VERSION ""

NS_ :

BS_:

BU_:

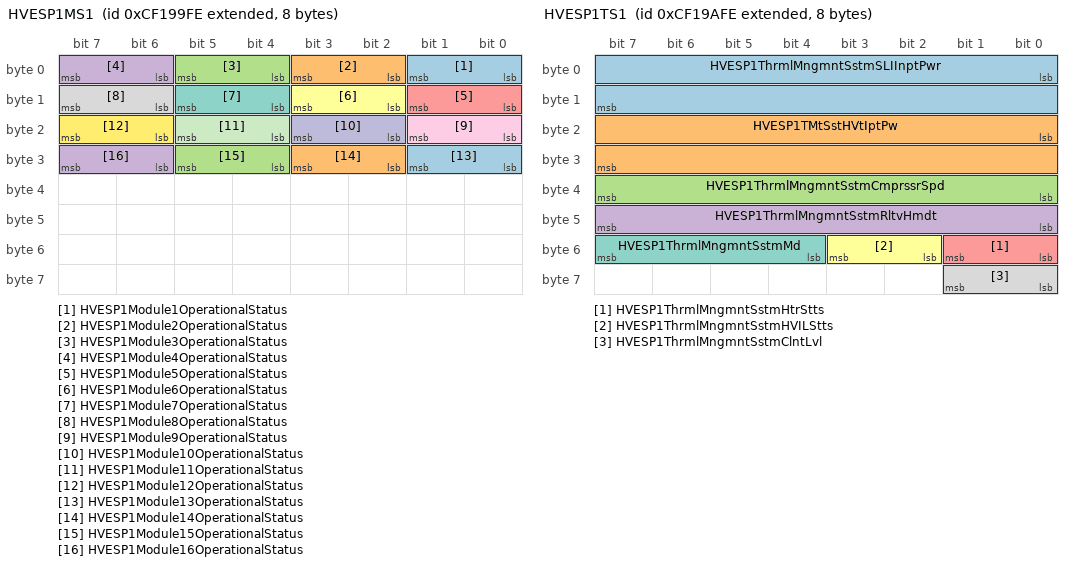
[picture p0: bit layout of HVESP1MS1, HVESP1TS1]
BO_ 2364643838 HVESP1MS1: 8 Vector__XXX
 SG_ HVESP1Module1OperationalStatus : 0|2@1+ (1,0) [0|3] "" Vector__XXX
 SG_ HVESP1Module2OperationalStatus : 2|2@1+ (1,0) [0|3] "" Vector__XXX
 SG_ HVESP1Module3OperationalStatus : 4|2@1+ (1,0) [0|3] "" Vector__XXX
 SG_ HVESP1Module4OperationalStatus : 6|2@1+ (1,0) [0|3] "" Vector__XXX
 SG_ HVESP1Module5OperationalStatus : 8|2@1+ (1,0) [0|3] "" Vector__XXX
 SG_ HVESP1Module6OperationalStatus : 10|2@1+ (1,0) [0|3] "" Vector__XXX
 SG_ HVESP1Module7OperationalStatus : 12|2@1+ (1,0) [0|3] "" Vector__XXX
 SG_ HVESP1Module8OperationalStatus : 14|2@1+ (1,0) [0|3] "" Vector__XXX
 SG_ HVESP1Module9OperationalStatus : 16|2@1+ (1,0) [0|3] "" Vector__XXX
 SG_ HVESP1Module10OperationalStatus : 18|2@1+ (1,0) [0|3] "" Vector__XXX
 SG_ HVESP1Module11OperationalStatus : 20|2@1+ (1,0) [0|3] "" Vector__XXX
 SG_ HVESP1Module12OperationalStatus : 22|2@1+ (1,0) [0|3] "" Vector__XXX
 SG_ HVESP1Module13OperationalStatus : 24|2@1+ (1,0) [0|3] "" Vector__XXX
 SG_ HVESP1Module14OperationalStatus : 26|2@1+ (1,0) [0|3] "" Vector__XXX
 SG_ HVESP1Module15OperationalStatus : 28|2@1+ (1,0) [0|3] "" Vector__XXX
 SG_ HVESP1Module16OperationalStatus : 30|2@1+ (1,0) [0|3] "" Vector__XXX

BO_ 2364644094 HVESP1TS1: 8 Vector__XXX
 SG_ HVESP1ThrmlMngmntSstmSLIInptPwr : 0|16@1+ (0.5,0) [0|32127.5] "W" Vector__XXX
 SG_ HVESP1TMtSstHVtIptPw : 16|16@1+ (0.5,0) [0|32127.5] "W" Vector__XXX
 SG_ HVESP1ThrmlMngmntSstmCmprssrSpd : 32|8@1+ (32,0) [0|8000] "rpm" Vector__XXX
 SG_ HVESP1ThrmlMngmntSstmRltvHmdt : 40|8@1+ (0.4,0) [0|100] "%" Vector__XXX
 SG_ HVESP1ThrmlMngmntSstmHtrStts : 48|2@1+ (1,0) [0|3] "" Vector__XXX
 SG_ HVESP1ThrmlMngmntSstmHVILStts : 50|2@1+ (1,0) [0|3] "" Vector__XXX
 SG_ HVESP1ThrmlMngmntSstmMd : 52|4@1+ (1,0) [0|15] "" Vector__XXX
 SG_ HVESP1ThrmlMngmntSstmClntLvl : 56|2@1+ (1,0) [0|3] "" Vector__XXX

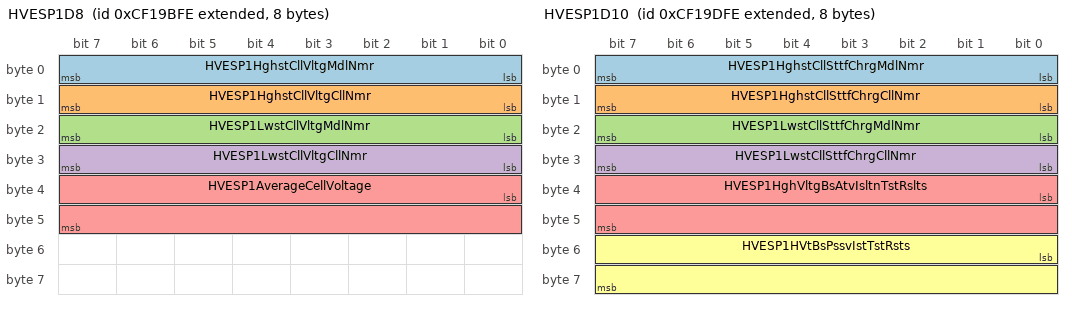
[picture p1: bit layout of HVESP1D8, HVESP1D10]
BO_ 2364644350 HVESP1D8: 8 Vector__XXX
 SG_ HVESP1HghstCllVltgMdlNmr : 0|8@1+ (1,0) [0|250] "count" Vector__XXX
 SG_ HVESP1HghstCllVltgCllNmr : 8|8@1+ (1,0) [0|250] "count" Vector__XXX
 SG_ HVESP1LwstCllVltgMdlNmr : 16|8@1+ (1,0) [0|250] "count" Vector__XXX
 SG_ HVESP1LwstCllVltgCllNmr : 24|8@1+ (1,0) [0|250] "count" Vector__XXX
 SG_ HVESP1AverageCellVoltage : 32|16@1+ (0.001,0) [0|64.255] "V" Vector__XXX

BO_ 2364644606 HVESP1D9: 8 Vector__XXX
 SG_ HVESP1HghstCllTmprtrMdlNmr : 0|8@1+ (1,0) [0|250] "count" Vector__XXX
 SG_ HVESP1HghstCllTmprtrCllNmr : 8|8@1+ (1,0) [0|250] "count" Vector__XXX
 SG_ HVESP1LwstCllTmprtrMdlNmr : 16|8@1+ (1,0) [0|250] "count" Vector__XXX
 SG_ HVESP1LwstCllTmprtrCllNmr : 24|8@1+ (1,0) [0|250] "count" Vector__XXX

BO_ 2364644862 HVESP1D10: 8 Vector__XXX
 SG_ HVESP1HghstCllSttfChrgMdlNmr : 0|8@1+ (1,0) [0|250] "count" Vector__XXX
 SG_ HVESP1HghstCllSttfChrgCllNmr : 8|8@1+ (1,0) [0|250] "count" Vector__XXX
 SG_ HVESP1LwstCllSttfChrgMdlNmr : 16|8@1+ (1,0) [0|250] "count" Vector__XXX
 SG_ HVESP1LwstCllSttfChrgCllNmr : 24|8@1+ (1,0) [0|250] "count" Vector__XXX
 SG_ HVESP1HghVltgBsAtvIsltnTstRslts : 32|16@1+ (0.1,0) [0|6425.5] "ohm/V" Vector__XXX
 SG_ HVESP1HVtBsPssvIstTstRsts : 48|16@1+ (0.1,0) [0|6425.5] "ohm/V" Vector__XXX

BO_ 2364645118 HVESP1D11: 8 Vector__XXX
 SG_ HVESP1BsVltgNgtvtChsssGrndVltg : 0|16@1+ (0.05,0) [0|3212.75] "V" Vector__XXX
 SG_ HVESP1VltgLvlNgtvtChsssGrndVltg : 16|16@1+ (0.05,0) [0|3212.75] "V" Vector__XXX

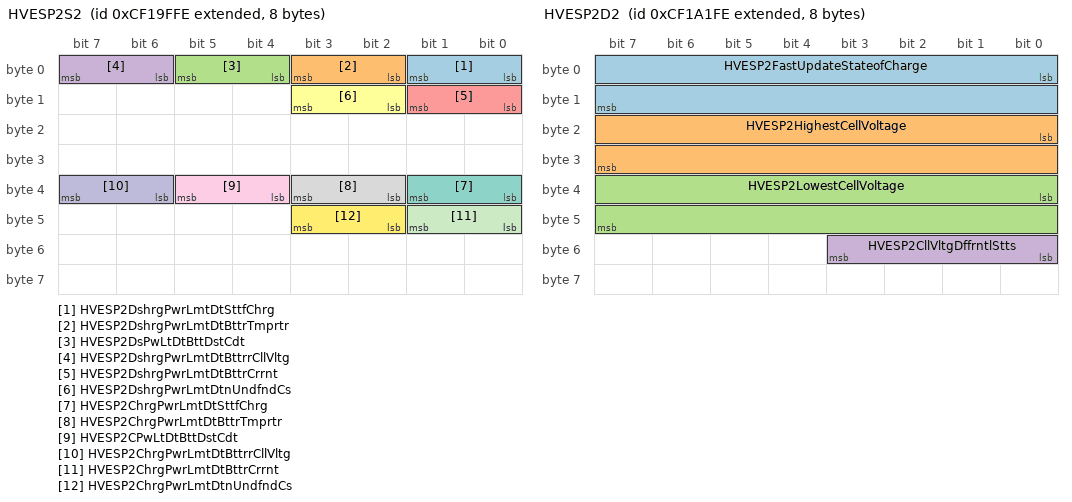
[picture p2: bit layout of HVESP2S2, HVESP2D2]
BO_ 2364645374 HVESP2S2: 8 Vector__XXX
 SG_ HVESP2DshrgPwrLmtDtSttfChrg : 0|2@1+ (1,0) [0|3] "" Vector__XXX
 SG_ HVESP2DshrgPwrLmtDtBttrTmprtr : 2|2@1+ (1,0) [0|3] "" Vector__XXX
 SG_ HVESP2DsPwLtDtBttDstCdt : 4|2@1+ (1,0) [0|3] "" Vector__XXX
 SG_ HVESP2DshrgPwrLmtDtBttrrCllVltg : 6|2@1+ (1,0) [0|3] "" Vector__XXX
 SG_ HVESP2DshrgPwrLmtDtBttrCrrnt : 8|2@1+ (1,0) [0|3] "" Vector__XXX
 SG_ HVESP2DshrgPwrLmtDtnUndfndCs : 10|2@1+ (1,0) [0|3] "" Vector__XXX
 SG_ HVESP2ChrgPwrLmtDtSttfChrg : 32|2@1+ (1,0) [0|3] "" Vector__XXX
 SG_ HVESP2ChrgPwrLmtDtBttrTmprtr : 34|2@1+ (1,0) [0|3] "" Vector__XXX
 SG_ HVESP2CPwLtDtBttDstCdt : 36|2@1+ (1,0) [0|3] "" Vector__XXX
 SG_ HVESP2ChrgPwrLmtDtBttrrCllVltg : 38|2@1+ (1,0) [0|3] "" Vector__XXX
 SG_ HVESP2ChrgPwrLmtDtBttrCrrnt : 40|2@1+ (1,0) [0|3] "" Vector__XXX
 SG_ HVESP2ChrgPwrLmtDtnUndfndCs : 42|2@1+ (1,0) [0|3] "" Vector__XXX

BO_ 2364645630 HVESP2D1: 8 Vector__XXX
 SG_ HVESP2AvailableDischargePower : 0|16@1+ (0.05,0) [0|3212.75] "kW" Vector__XXX
 SG_ HVESP2AvailableChargePower : 16|16@1+ (0.05,0) [0|3212.75] "kW" Vector__XXX
 SG_ HVESP2VoltageLevel : 32|16@1+ (0.05,0) [0|3212.75] "V" Vector__XXX
 SG_ HVESP2Current : 48|16@1+ (0.05,-1600) [-1600|1612.75] "A" Vector__XXX

BO_ 2364645886 HVESP2D2: 8 Vector__XXX
 SG_ HVESP2FastUpdateStateofCharge : 0|16@1+ (0.0015625,0) [0|100.3984375] "%" Vector__XXX
 SG_ HVESP2HighestCellVoltage : 16|16@1+ (0.001,0) [0|64.255] "V" Vector__XXX
 SG_ HVESP2LowestCellVoltage : 32|16@1+ (0.001,0) [0|64.255] "V" Vector__XXX
 SG_ HVESP2CllVltgDffrntlStts : 48|4@1+ (1,0) [0|15] "" Vector__XXX

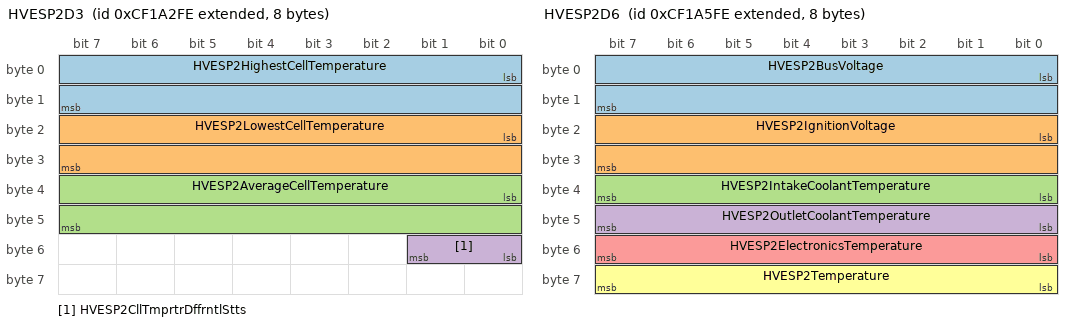
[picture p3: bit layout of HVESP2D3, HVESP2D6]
BO_ 2364646142 HVESP2D3: 8 Vector__XXX
 SG_ HVESP2HighestCellTemperature : 0|16@1+ (0.03125,-273) [-273|1734.96875] "degC" Vector__XXX
 SG_ HVESP2LowestCellTemperature : 16|16@1+ (0.03125,-273) [-273|1734.96875] "degC" Vector__XXX
 SG_ HVESP2AverageCellTemperature : 32|16@1+ (0.03125,-273) [-273|1734.96875] "degC" Vector__XXX
 SG_ HVESP2CllTmprtrDffrntlStts : 48|2@1+ (1,0) [0|3] "" Vector__XXX

BO_ 2364646398 HVESP2D4: 8 Vector__XXX
 SG_ HVESP2DischargeCapacity : 0|16@1+ (0.01,0) [0|642.55] "Ah" Vector__XXX
 SG_ HVESP2ChargeCapacity : 16|16@1+ (0.01,0) [0|642.55] "Ah" Vector__XXX
 SG_ HVESP2CellBalancingCount : 32|16@1+ (1,0) [0|64255] "count" Vector__XXX

BO_ 2364646654 HVESP2D5: 8 Vector__XXX
 SG_ HVESP2DischargeCurrentLimit : 0|16@1+ (0.05,-1600) [-1600|1612.75] "A" Vector__XXX
 SG_ HVESP2ChargeCurrentLimit : 16|16@1+ (0.05,-1600) [-1600|1612.75] "A" Vector__XXX
 SG_ HVESP2LowestCellStateofCharge : 32|16@1+ (0.0015625,0) [0|100.3984375] "%" Vector__XXX
 SG_ HVESP2HighestCellStateofCharge : 48|16@1+ (0.0015625,0) [0|100.3984375] "%" Vector__XXX

BO_ 2364646910 HVESP2D6: 8 Vector__XXX
 SG_ HVESP2BusVoltage : 0|16@1+ (0.05,0) [0|3212.75] "V" Vector__XXX
 SG_ HVESP2IgnitionVoltage : 16|16@1+ (0.01,0) [0|642.55] "V" Vector__XXX
 SG_ HVESP2IntakeCoolantTemperature : 32|8@1+ (1,-40) [-40|210] "degC" Vector__XXX
 SG_ HVESP2OutletCoolantTemperature : 40|8@1+ (1,-40) [-40|210] "degC" Vector__XXX
 SG_ HVESP2ElectronicsTemperature : 48|8@1+ (1,-40) [-40|210] "degC" Vector__XXX
 SG_ HVESP2Temperature : 56|8@1+ (1,-40) [-40|210] "degC" Vector__XXX

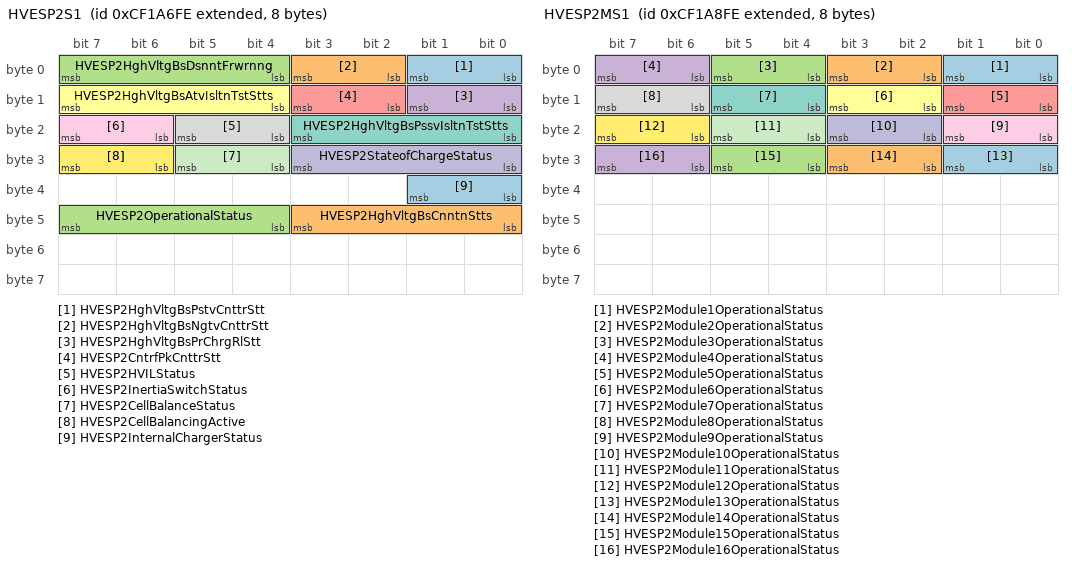
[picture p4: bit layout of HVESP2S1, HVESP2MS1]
BO_ 2364647166 HVESP2S1: 8 Vector__XXX
 SG_ HVESP2HghVltgBsPstvCnttrStt : 0|2@1+ (1,0) [0|3] "" Vector__XXX
 SG_ HVESP2HghVltgBsNgtvCnttrStt : 2|2@1+ (1,0) [0|3] "" Vector__XXX
 SG_ HVESP2HghVltgBsDsnntFrwrnng : 4|4@1+ (1,0) [0|15] "" Vector__XXX
 SG_ HVESP2HghVltgBsPrChrgRlStt : 8|2@1+ (1,0) [0|3] "" Vector__XXX
 SG_ HVESP2CntrfPkCnttrStt : 10|2@1+ (1,0) [0|3] "" Vector__XXX
 SG_ HVESP2HghVltgBsAtvIsltnTstStts : 12|4@1+ (1,0) [0|15] "" Vector__XXX
 SG_ HVESP2HghVltgBsPssvIsltnTstStts : 16|4@1+ (1,0) [0|15] "" Vector__XXX
 SG_ HVESP2HVILStatus : 20|2@1+ (1,0) [0|3] "" Vector__XXX
 SG_ HVESP2InertiaSwitchStatus : 22|2@1+ (1,0) [0|3] "" Vector__XXX
 SG_ HVESP2StateofChargeStatus : 24|4@1+ (1,0) [0|15] "" Vector__XXX
 SG_ HVESP2CellBalanceStatus : 28|2@1+ (1,0) [0|3] "" Vector__XXX
 SG_ HVESP2CellBalancingActive : 30|2@1+ (1,0) [0|3] "" Vector__XXX
 SG_ HVESP2InternalChargerStatus : 32|2@1+ (1,0) [0|3] "" Vector__XXX
 SG_ HVESP2HghVltgBsCnntnStts : 40|4@1+ (1,0) [0|15] "" Vector__XXX
 SG_ HVESP2OperationalStatus : 44|4@1+ (1,0) [0|15] "" Vector__XXX

BO_ 2364647422 HVESP2D7: 8 Vector__XXX
 SG_ HVESP2DischargeEnergyCapacity : 0|24@1+ (0.001,0) [0|16449.535] "kWh" Vector__XXX
 SG_ HVESP2ChargeEnergyCapacity : 24|24@1+ (0.001,0) [0|16449.535] "kWh" Vector__XXX
 SG_ HVESP2MaximumChargeVoltageLimit : 48|16@1+ (0.05,0) [0|3212.75] "V" Vector__XXX

BO_ 2364647678 HVESP2MS1: 8 Vector__XXX
 SG_ HVESP2Module1OperationalStatus : 0|2@1+ (1,0) [0|3] "" Vector__XXX
 SG_ HVESP2Module2OperationalStatus : 2|2@1+ (1,0) [0|3] "" Vector__XXX
 SG_ HVESP2Module3OperationalStatus : 4|2@1+ (1,0) [0|3] "" Vector__XXX
 SG_ HVESP2Module4OperationalStatus : 6|2@1+ (1,0) [0|3] "" Vector__XXX
 SG_ HVESP2Module5OperationalStatus : 8|2@1+ (1,0) [0|3] "" Vector__XXX
 SG_ HVESP2Module6OperationalStatus : 10|2@1+ (1,0) [0|3] "" Vector__XXX
 SG_ HVESP2Module7OperationalStatus : 12|2@1+ (1,0) [0|3] "" Vector__XXX
 SG_ HVESP2Module8OperationalStatus : 14|2@1+ (1,0) [0|3] "" Vector__XXX
 SG_ HVESP2Module9OperationalStatus : 16|2@1+ (1,0) [0|3] "" Vector__XXX
 SG_ HVESP2Module10OperationalStatus : 18|2@1+ (1,0) [0|3] "" Vector__XXX
 SG_ HVESP2Module11OperationalStatus : 20|2@1+ (1,0) [0|3] "" Vector__XXX
 SG_ HVESP2Module12OperationalStatus : 22|2@1+ (1,0) [0|3] "" Vector__XXX
 SG_ HVESP2Module13OperationalStatus : 24|2@1+ (1,0) [0|3] "" Vector__XXX
 SG_ HVESP2Module14OperationalStatus : 26|2@1+ (1,0) [0|3] "" Vector__XXX
 SG_ HVESP2Module15OperationalStatus : 28|2@1+ (1,0) [0|3] "" Vector__XXX
 SG_ HVESP2Module16OperationalStatus : 30|2@1+ (1,0) [0|3] "" Vector__XXX

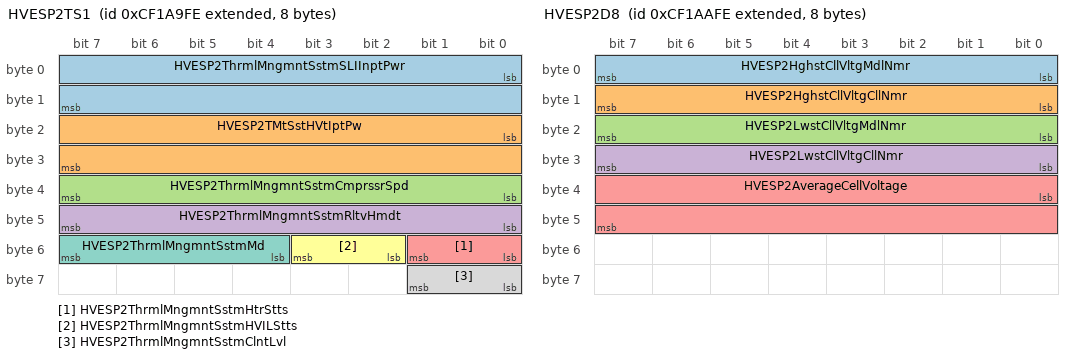
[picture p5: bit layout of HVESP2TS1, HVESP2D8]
BO_ 2364647934 HVESP2TS1: 8 Vector__XXX
 SG_ HVESP2ThrmlMngmntSstmSLIInptPwr : 0|16@1+ (0.5,0) [0|32127.5] "W" Vector__XXX
 SG_ HVESP2TMtSstHVtIptPw : 16|16@1+ (0.5,0) [0|32127.5] "W" Vector__XXX
 SG_ HVESP2ThrmlMngmntSstmCmprssrSpd : 32|8@1+ (32,0) [0|8000] "rpm" Vector__XXX
 SG_ HVESP2ThrmlMngmntSstmRltvHmdt : 40|8@1+ (0.4,0) [0|100] "%" Vector__XXX
 SG_ HVESP2ThrmlMngmntSstmHtrStts : 48|2@1+ (1,0) [0|3] "" Vector__XXX
 SG_ HVESP2ThrmlMngmntSstmHVILStts : 50|2@1+ (1,0) [0|3] "" Vector__XXX
 SG_ HVESP2ThrmlMngmntSstmMd : 52|4@1+ (1,0) [0|15] "" Vector__XXX
 SG_ HVESP2ThrmlMngmntSstmClntLvl : 56|2@1+ (1,0) [0|3] "" Vector__XXX

BO_ 2364648190 HVESP2D8: 8 Vector__XXX
 SG_ HVESP2HghstCllVltgMdlNmr : 0|8@1+ (1,0) [0|250] "count" Vector__XXX
 SG_ HVESP2HghstCllVltgCllNmr : 8|8@1+ (1,0) [0|250] "count" Vector__XXX
 SG_ HVESP2LwstCllVltgMdlNmr : 16|8@1+ (1,0) [0|250] "count" Vector__XXX
 SG_ HVESP2LwstCllVltgCllNmr : 24|8@1+ (1,0) [0|250] "count" Vector__XXX
 SG_ HVESP2AverageCellVoltage : 32|16@1+ (0.001,0) [0|64.255] "V" Vector__XXX

BO_ 2364648446 HVESP2D9: 8 Vector__XXX
 SG_ HVESP2HghstCllTmprtrMdlNmr : 0|8@1+ (1,0) [0|250] "count" Vector__XXX
 SG_ HVESP2HghstCllTmprtrCllNmr : 8|8@1+ (1,0) [0|250] "count" Vector__XXX
 SG_ HVESP2LwstCllTmprtrMdlNmr : 16|8@1+ (1,0) [0|250] "count" Vector__XXX
 SG_ HVESP2LwstCllTmprtrCllNmr : 24|8@1+ (1,0) [0|250] "count" Vector__XXX

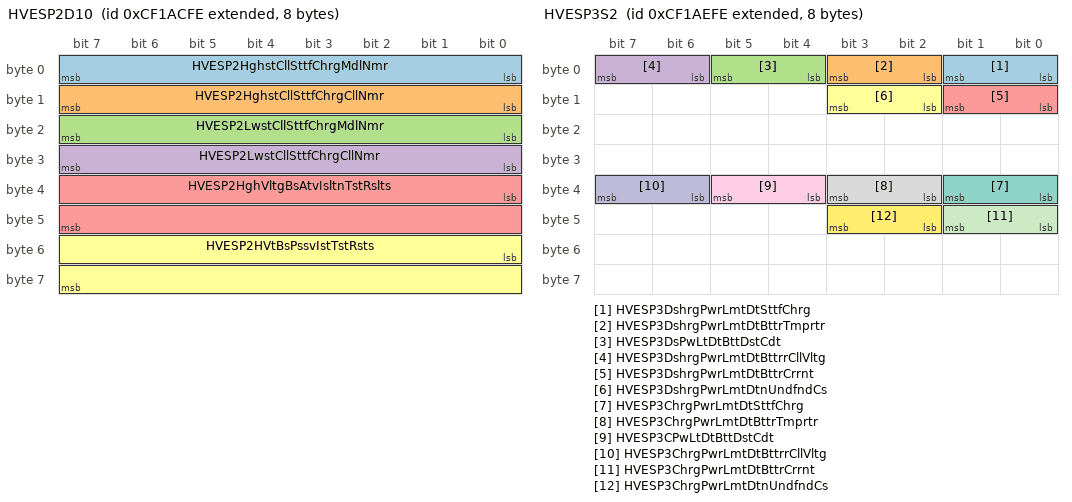
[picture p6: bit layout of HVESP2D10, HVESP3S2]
BO_ 2364648702 HVESP2D10: 8 Vector__XXX
 SG_ HVESP2HghstCllSttfChrgMdlNmr : 0|8@1+ (1,0) [0|250] "count" Vector__XXX
 SG_ HVESP2HghstCllSttfChrgCllNmr : 8|8@1+ (1,0) [0|250] "count" Vector__XXX
 SG_ HVESP2LwstCllSttfChrgMdlNmr : 16|8@1+ (1,0) [0|250] "count" Vector__XXX
 SG_ HVESP2LwstCllSttfChrgCllNmr : 24|8@1+ (1,0) [0|250] "count" Vector__XXX
 SG_ HVESP2HghVltgBsAtvIsltnTstRslts : 32|16@1+ (0.1,0) [0|6425.5] "ohm/V" Vector__XXX
 SG_ HVESP2HVtBsPssvIstTstRsts : 48|16@1+ (0.1,0) [0|6425.5] "ohm/V" Vector__XXX

BO_ 2364648958 HVESP2D11: 8 Vector__XXX
 SG_ HVESP2BsVltgNgtvtChsssGrndVltg : 0|16@1+ (0.05,0) [0|3212.75] "V" Vector__XXX
 SG_ HVESP2VltgLvlNgtvtChsssGrndVltg : 16|16@1+ (0.05,0) [0|3212.75] "V" Vector__XXX

BO_ 2364649214 HVESP3S2: 8 Vector__XXX
 SG_ HVESP3DshrgPwrLmtDtSttfChrg : 0|2@1+ (1,0) [0|3] "" Vector__XXX
 SG_ HVESP3DshrgPwrLmtDtBttrTmprtr : 2|2@1+ (1,0) [0|3] "" Vector__XXX
 SG_ HVESP3DsPwLtDtBttDstCdt : 4|2@1+ (1,0) [0|3] "" Vector__XXX
 SG_ HVESP3DshrgPwrLmtDtBttrrCllVltg : 6|2@1+ (1,0) [0|3] "" Vector__XXX
 SG_ HVESP3DshrgPwrLmtDtBttrCrrnt : 8|2@1+ (1,0) [0|3] "" Vector__XXX
 SG_ HVESP3DshrgPwrLmtDtnUndfndCs : 10|2@1+ (1,0) [0|3] "" Vector__XXX
 SG_ HVESP3ChrgPwrLmtDtSttfChrg : 32|2@1+ (1,0) [0|3] "" Vector__XXX
 SG_ HVESP3ChrgPwrLmtDtBttrTmprtr : 34|2@1+ (1,0) [0|3] "" Vector__XXX
 SG_ HVESP3CPwLtDtBttDstCdt : 36|2@1+ (1,0) [0|3] "" Vector__XXX
 SG_ HVESP3ChrgPwrLmtDtBttrrCllVltg : 38|2@1+ (1,0) [0|3] "" Vector__XXX
 SG_ HVESP3ChrgPwrLmtDtBttrCrrnt : 40|2@1+ (1,0) [0|3] "" Vector__XXX
 SG_ HVESP3ChrgPwrLmtDtnUndfndCs : 42|2@1+ (1,0) [0|3] "" Vector__XXX

BO_ 2364649470 HVESP3D1: 8 Vector__XXX
 SG_ HVESP3AvailableDischargePower : 0|16@1+ (0.05,0) [0|3212.75] "kW" Vector__XXX
 SG_ HVESP3AvailableChargePower : 16|16@1+ (0.05,0) [0|3212.75] "kW" Vector__XXX
 SG_ HVESP3VoltageLevel : 32|16@1+ (0.05,0) [0|3212.75] "V" Vector__XXX
 SG_ HVESP3Current : 48|16@1+ (0.05,-1600) [-1600|1612.75] "A" Vector__XXX

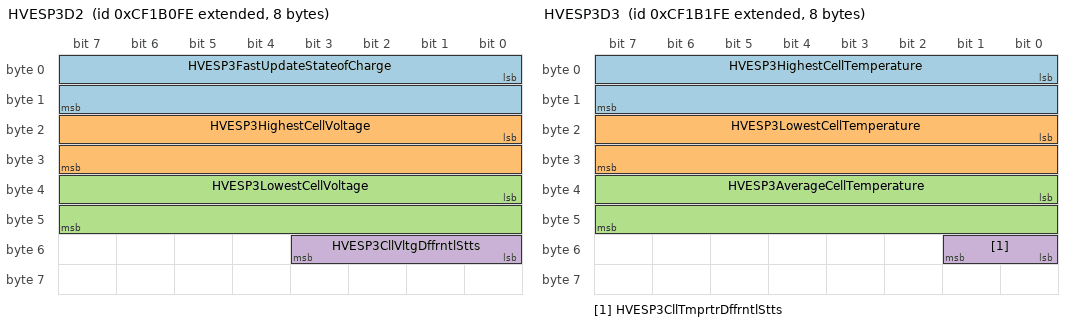
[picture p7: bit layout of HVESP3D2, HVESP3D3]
BO_ 2364649726 HVESP3D2: 8 Vector__XXX
 SG_ HVESP3FastUpdateStateofCharge : 0|16@1+ (0.0015625,0) [0|100.3984375] "%" Vector__XXX
 SG_ HVESP3HighestCellVoltage : 16|16@1+ (0.001,0) [0|64.255] "V" Vector__XXX
 SG_ HVESP3LowestCellVoltage : 32|16@1+ (0.001,0) [0|64.255] "V" Vector__XXX
 SG_ HVESP3CllVltgDffrntlStts : 48|4@1+ (1,0) [0|15] "" Vector__XXX

BO_ 2364649982 HVESP3D3: 8 Vector__XXX
 SG_ HVESP3HighestCellTemperature : 0|16@1+ (0.03125,-273) [-273|1734.96875] "degC" Vector__XXX
 SG_ HVESP3LowestCellTemperature : 16|16@1+ (0.03125,-273) [-273|1734.96875] "degC" Vector__XXX
 SG_ HVESP3AverageCellTemperature : 32|16@1+ (0.03125,-273) [-273|1734.96875] "degC" Vector__XXX
 SG_ HVESP3CllTmprtrDffrntlStts : 48|2@1+ (1,0) [0|3] "" Vector__XXX

BO_ 2364650238 HVESP3D4: 8 Vector__XXX
 SG_ HVESP3DischargeCapacity : 0|16@1+ (0.01,0) [0|642.55] "Ah" Vector__XXX
 SG_ HVESP3ChargeCapacity : 16|16@1+ (0.01,0) [0|642.55] "Ah" Vector__XXX
 SG_ HVESP3CellBalancingCount : 32|16@1+ (1,0) [0|64255] "count" Vector__XXX

BO_ 2364650494 HVESP3D5: 8 Vector__XXX
 SG_ HVESP3DischargeCurrentLimit : 0|16@1+ (0.05,-1600) [-1600|1612.75] "A" Vector__XXX
 SG_ HVESP3ChargeCurrentLimit : 16|16@1+ (0.05,-1600) [-1600|1612.75] "A" Vector__XXX
 SG_ HVESP3LowestCellStateofCharge : 32|16@1+ (0.0015625,0) [0|100.3984375] "%" Vector__XXX
 SG_ HVESP3HighestCellStateofCharge : 48|16@1+ (0.0015625,0) [0|100.3984375] "%" Vector__XXX

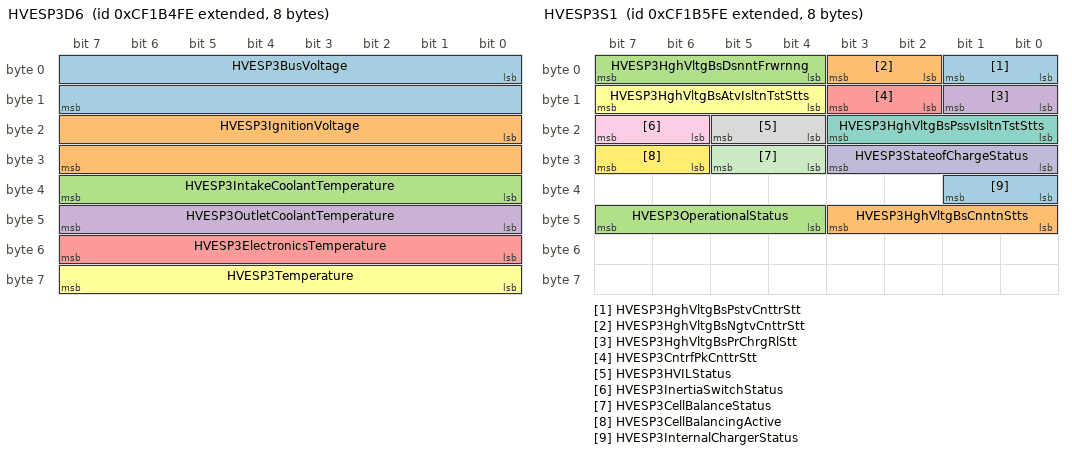
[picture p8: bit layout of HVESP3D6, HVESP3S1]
BO_ 2364650750 HVESP3D6: 8 Vector__XXX
 SG_ HVESP3BusVoltage : 0|16@1+ (0.05,0) [0|3212.75] "V" Vector__XXX
 SG_ HVESP3IgnitionVoltage : 16|16@1+ (0.01,0) [0|642.55] "V" Vector__XXX
 SG_ HVESP3IntakeCoolantTemperature : 32|8@1+ (1,-40) [-40|210] "degC" Vector__XXX
 SG_ HVESP3OutletCoolantTemperature : 40|8@1+ (1,-40) [-40|210] "degC" Vector__XXX
 SG_ HVESP3ElectronicsTemperature : 48|8@1+ (1,-40) [-40|210] "degC" Vector__XXX
 SG_ HVESP3Temperature : 56|8@1+ (1,-40) [-40|210] "degC" Vector__XXX

BO_ 2364651006 HVESP3S1: 8 Vector__XXX
 SG_ HVESP3HghVltgBsPstvCnttrStt : 0|2@1+ (1,0) [0|3] "" Vector__XXX
 SG_ HVESP3HghVltgBsNgtvCnttrStt : 2|2@1+ (1,0) [0|3] "" Vector__XXX
 SG_ HVESP3HghVltgBsDsnntFrwrnng : 4|4@1+ (1,0) [0|15] "" Vector__XXX
 SG_ HVESP3HghVltgBsPrChrgRlStt : 8|2@1+ (1,0) [0|3] "" Vector__XXX
 SG_ HVESP3CntrfPkCnttrStt : 10|2@1+ (1,0) [0|3] "" Vector__XXX
 SG_ HVESP3HghVltgBsAtvIsltnTstStts : 12|4@1+ (1,0) [0|15] "" Vector__XXX
 SG_ HVESP3HghVltgBsPssvIsltnTstStts : 16|4@1+ (1,0) [0|15] "" Vector__XXX
 SG_ HVESP3HVILStatus : 20|2@1+ (1,0) [0|3] "" Vector__XXX
 SG_ HVESP3InertiaSwitchStatus : 22|2@1+ (1,0) [0|3] "" Vector__XXX
 SG_ HVESP3StateofChargeStatus : 24|4@1+ (1,0) [0|15] "" Vector__XXX
 SG_ HVESP3CellBalanceStatus : 28|2@1+ (1,0) [0|3] "" Vector__XXX
 SG_ HVESP3CellBalancingActive : 30|2@1+ (1,0) [0|3] "" Vector__XXX
 SG_ HVESP3InternalChargerStatus : 32|2@1+ (1,0) [0|3] "" Vector__XXX
 SG_ HVESP3HghVltgBsCnntnStts : 40|4@1+ (1,0) [0|15] "" Vector__XXX
 SG_ HVESP3OperationalStatus : 44|4@1+ (1,0) [0|15] "" Vector__XXX

BO_ 2364651262 HVESP3D7: 8 Vector__XXX
 SG_ HVESP3DischargeEnergyCapacity : 0|24@1+ (0.001,0) [0|16449.535] "kWh" Vector__XXX
 SG_ HVESP3ChargeEnergyCapacity : 24|24@1+ (0.001,0) [0|16449.535] "kWh" Vector__XXX
 SG_ HVESP3MaximumChargeVoltageLimit : 48|16@1+ (0.05,0) [0|3212.75] "V" Vector__XXX

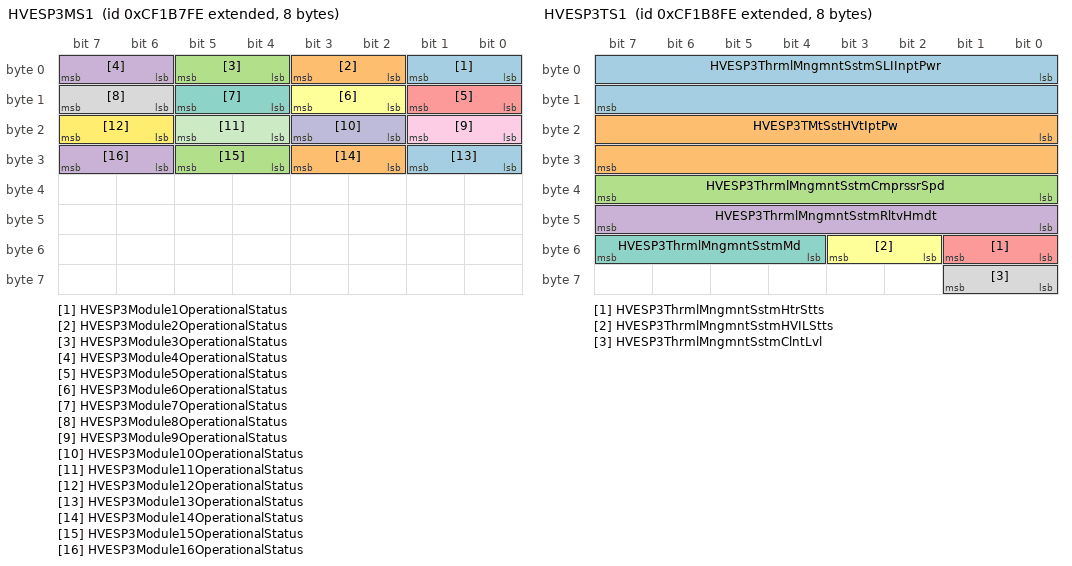
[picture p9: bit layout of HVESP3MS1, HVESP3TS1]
BO_ 2364651518 HVESP3MS1: 8 Vector__XXX
 SG_ HVESP3Module1OperationalStatus : 0|2@1+ (1,0) [0|3] "" Vector__XXX
 SG_ HVESP3Module2OperationalStatus : 2|2@1+ (1,0) [0|3] "" Vector__XXX
 SG_ HVESP3Module3OperationalStatus : 4|2@1+ (1,0) [0|3] "" Vector__XXX
 SG_ HVESP3Module4OperationalStatus : 6|2@1+ (1,0) [0|3] "" Vector__XXX
 SG_ HVESP3Module5OperationalStatus : 8|2@1+ (1,0) [0|3] "" Vector__XXX
 SG_ HVESP3Module6OperationalStatus : 10|2@1+ (1,0) [0|3] "" Vector__XXX
 SG_ HVESP3Module7OperationalStatus : 12|2@1+ (1,0) [0|3] "" Vector__XXX
 SG_ HVESP3Module8OperationalStatus : 14|2@1+ (1,0) [0|3] "" Vector__XXX
 SG_ HVESP3Module9OperationalStatus : 16|2@1+ (1,0) [0|3] "" Vector__XXX
 SG_ HVESP3Module10OperationalStatus : 18|2@1+ (1,0) [0|3] "" Vector__XXX
 SG_ HVESP3Module11OperationalStatus : 20|2@1+ (1,0) [0|3] "" Vector__XXX
 SG_ HVESP3Module12OperationalStatus : 22|2@1+ (1,0) [0|3] "" Vector__XXX
 SG_ HVESP3Module13OperationalStatus : 24|2@1+ (1,0) [0|3] "" Vector__XXX
 SG_ HVESP3Module14OperationalStatus : 26|2@1+ (1,0) [0|3] "" Vector__XXX
 SG_ HVESP3Module15OperationalStatus : 28|2@1+ (1,0) [0|3] "" Vector__XXX
 SG_ HVESP3Module16OperationalStatus : 30|2@1+ (1,0) [0|3] "" Vector__XXX

BO_ 2364651774 HVESP3TS1: 8 Vector__XXX
 SG_ HVESP3ThrmlMngmntSstmSLIInptPwr : 0|16@1+ (0.5,0) [0|32127.5] "W" Vector__XXX
 SG_ HVESP3TMtSstHVtIptPw : 16|16@1+ (0.5,0) [0|32127.5] "W" Vector__XXX
 SG_ HVESP3ThrmlMngmntSstmCmprssrSpd : 32|8@1+ (32,0) [0|8000] "rpm" Vector__XXX
 SG_ HVESP3ThrmlMngmntSstmRltvHmdt : 40|8@1+ (0.4,0) [0|100] "%" Vector__XXX
 SG_ HVESP3ThrmlMngmntSstmHtrStts : 48|2@1+ (1,0) [0|3] "" Vector__XXX
 SG_ HVESP3ThrmlMngmntSstmHVILStts : 50|2@1+ (1,0) [0|3] "" Vector__XXX
 SG_ HVESP3ThrmlMngmntSstmMd : 52|4@1+ (1,0) [0|15] "" Vector__XXX
 SG_ HVESP3ThrmlMngmntSstmClntLvl : 56|2@1+ (1,0) [0|3] "" Vector__XXX

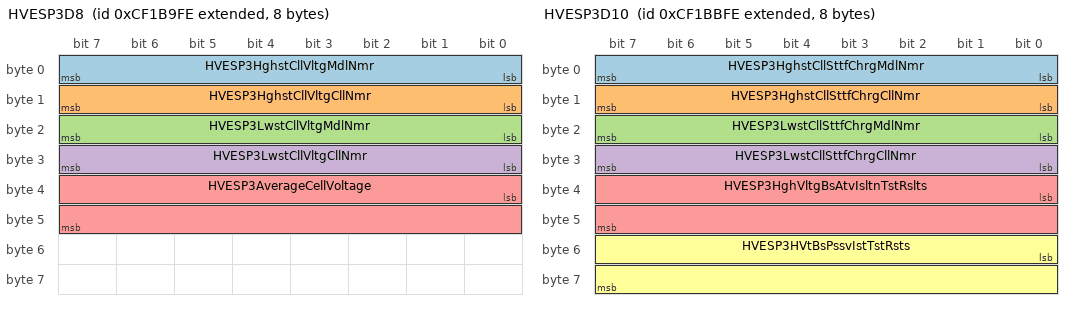
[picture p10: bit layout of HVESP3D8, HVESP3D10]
BO_ 2364652030 HVESP3D8: 8 Vector__XXX
 SG_ HVESP3HghstCllVltgMdlNmr : 0|8@1+ (1,0) [0|250] "count" Vector__XXX
 SG_ HVESP3HghstCllVltgCllNmr : 8|8@1+ (1,0) [0|250] "count" Vector__XXX
 SG_ HVESP3LwstCllVltgMdlNmr : 16|8@1+ (1,0) [0|250] "count" Vector__XXX
 SG_ HVESP3LwstCllVltgCllNmr : 24|8@1+ (1,0) [0|250] "count" Vector__XXX
 SG_ HVESP3AverageCellVoltage : 32|16@1+ (0.001,0) [0|64.255] "V" Vector__XXX

BO_ 2364652286 HVESP3D9: 8 Vector__XXX
 SG_ HVESP3HghstCllTmprtrMdlNmr : 0|8@1+ (1,0) [0|250] "count" Vector__XXX
 SG_ HVESP3HghstCllTmprtrCllNmr : 8|8@1+ (1,0) [0|250] "count" Vector__XXX
 SG_ HVESP3LwstCllTmprtrMdlNmr : 16|8@1+ (1,0) [0|250] "count" Vector__XXX
 SG_ HVESP3LwstCllTmprtrCllNmr : 24|8@1+ (1,0) [0|250] "count" Vector__XXX

BO_ 2364652542 HVESP3D10: 8 Vector__XXX
 SG_ HVESP3HghstCllSttfChrgMdlNmr : 0|8@1+ (1,0) [0|250] "count" Vector__XXX
 SG_ HVESP3HghstCllSttfChrgCllNmr : 8|8@1+ (1,0) [0|250] "count" Vector__XXX
 SG_ HVESP3LwstCllSttfChrgMdlNmr : 16|8@1+ (1,0) [0|250] "count" Vector__XXX
 SG_ HVESP3LwstCllSttfChrgCllNmr : 24|8@1+ (1,0) [0|250] "count" Vector__XXX
 SG_ HVESP3HghVltgBsAtvIsltnTstRslts : 32|16@1+ (0.1,0) [0|6425.5] "ohm/V" Vector__XXX
 SG_ HVESP3HVtBsPssvIstTstRsts : 48|16@1+ (0.1,0) [0|6425.5] "ohm/V" Vector__XXX

BO_ 2364652798 HVESP3D11: 8 Vector__XXX
 SG_ HVESP3BsVltgNgtvtChsssGrndVltg : 0|16@1+ (0.05,0) [0|3212.75] "V" Vector__XXX
 SG_ HVESP3VltgLvlNgtvtChsssGrndVltg : 16|16@1+ (0.05,0) [0|3212.75] "V" Vector__XXX

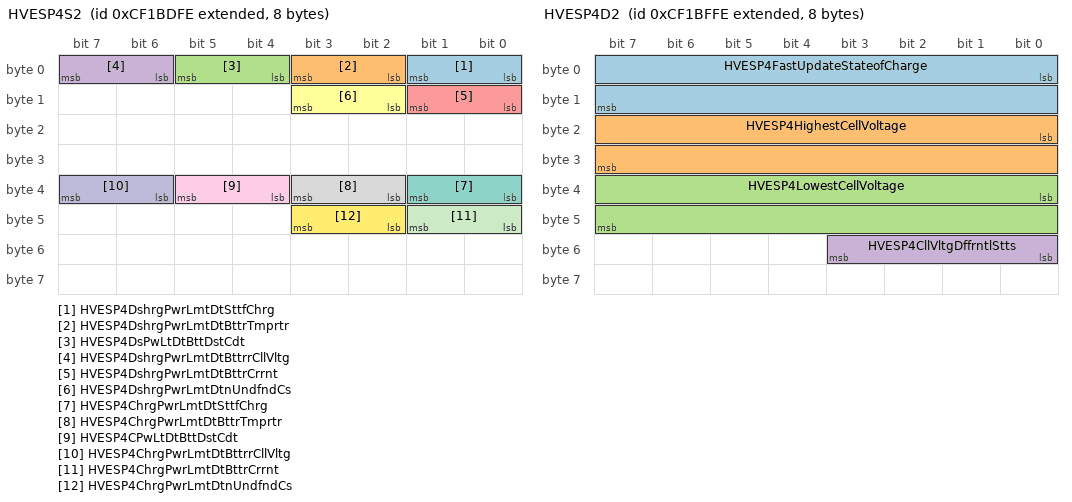
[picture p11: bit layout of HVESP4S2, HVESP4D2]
BO_ 2364653054 HVESP4S2: 8 Vector__XXX
 SG_ HVESP4DshrgPwrLmtDtSttfChrg : 0|2@1+ (1,0) [0|3] "" Vector__XXX
 SG_ HVESP4DshrgPwrLmtDtBttrTmprtr : 2|2@1+ (1,0) [0|3] "" Vector__XXX
 SG_ HVESP4DsPwLtDtBttDstCdt : 4|2@1+ (1,0) [0|3] "" Vector__XXX
 SG_ HVESP4DshrgPwrLmtDtBttrrCllVltg : 6|2@1+ (1,0) [0|3] "" Vector__XXX
 SG_ HVESP4DshrgPwrLmtDtBttrCrrnt : 8|2@1+ (1,0) [0|3] "" Vector__XXX
 SG_ HVESP4DshrgPwrLmtDtnUndfndCs : 10|2@1+ (1,0) [0|3] "" Vector__XXX
 SG_ HVESP4ChrgPwrLmtDtSttfChrg : 32|2@1+ (1,0) [0|3] "" Vector__XXX
 SG_ HVESP4ChrgPwrLmtDtBttrTmprtr : 34|2@1+ (1,0) [0|3] "" Vector__XXX
 SG_ HVESP4CPwLtDtBttDstCdt : 36|2@1+ (1,0) [0|3] "" Vector__XXX
 SG_ HVESP4ChrgPwrLmtDtBttrrCllVltg : 38|2@1+ (1,0) [0|3] "" Vector__XXX
 SG_ HVESP4ChrgPwrLmtDtBttrCrrnt : 40|2@1+ (1,0) [0|3] "" Vector__XXX
 SG_ HVESP4ChrgPwrLmtDtnUndfndCs : 42|2@1+ (1,0) [0|3] "" Vector__XXX

BO_ 2364653310 HVESP4D1: 8 Vector__XXX
 SG_ HVESP4AvailableDischargePower : 0|16@1+ (0.05,0) [0|3212.75] "kW" Vector__XXX
 SG_ HVESP4AvailableChargePower : 16|16@1+ (0.05,0) [0|3212.75] "kW" Vector__XXX
 SG_ HVESP4VoltageLevel : 32|16@1+ (0.05,0) [0|3212.75] "V" Vector__XXX
 SG_ HVESP4Current : 48|16@1+ (0.05,-1600) [-1600|1612.75] "A" Vector__XXX

BO_ 2364653566 HVESP4D2: 8 Vector__XXX
 SG_ HVESP4FastUpdateStateofCharge : 0|16@1+ (0.0015625,0) [0|100.3984375] "%" Vector__XXX
 SG_ HVESP4HighestCellVoltage : 16|16@1+ (0.001,0) [0|64.255] "V" Vector__XXX
 SG_ HVESP4LowestCellVoltage : 32|16@1+ (0.001,0) [0|64.255] "V" Vector__XXX
 SG_ HVESP4CllVltgDffrntlStts : 48|4@1+ (1,0) [0|15] "" Vector__XXX

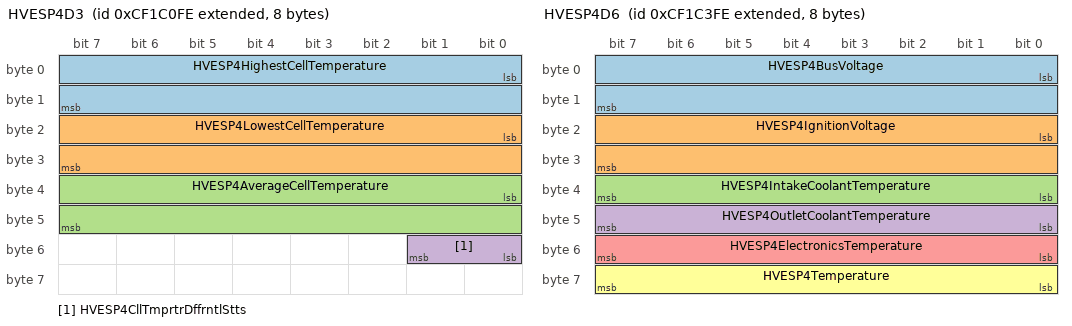
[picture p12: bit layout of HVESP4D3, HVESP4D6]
BO_ 2364653822 HVESP4D3: 8 Vector__XXX
 SG_ HVESP4HighestCellTemperature : 0|16@1+ (0.03125,-273) [-273|1734.96875] "degC" Vector__XXX
 SG_ HVESP4LowestCellTemperature : 16|16@1+ (0.03125,-273) [-273|1734.96875] "degC" Vector__XXX
 SG_ HVESP4AverageCellTemperature : 32|16@1+ (0.03125,-273) [-273|1734.96875] "degC" Vector__XXX
 SG_ HVESP4CllTmprtrDffrntlStts : 48|2@1+ (1,0) [0|3] "" Vector__XXX

BO_ 2364654078 HVESP4D4: 8 Vector__XXX
 SG_ HVESP4DischargeCapacity : 0|16@1+ (0.01,0) [0|642.55] "Ah" Vector__XXX
 SG_ HVESP4ChargeCapacity : 16|16@1+ (0.01,0) [0|642.55] "Ah" Vector__XXX
 SG_ HVESP4CellBalancingCount : 32|16@1+ (1,0) [0|64255] "count" Vector__XXX

BO_ 2364654334 HVESP4D5: 8 Vector__XXX
 SG_ HVESP4DischargeCurrentLimit : 0|16@1+ (0.05,-1600) [-1600|1612.75] "A" Vector__XXX
 SG_ HVESP4ChargeCurrentLimit : 16|16@1+ (0.05,-1600) [-1600|1612.75] "A" Vector__XXX
 SG_ HVESP4LowestCellStateofCharge : 32|16@1+ (0.0015625,0) [0|100.3984375] "%" Vector__XXX
 SG_ HVESP4HighestCellStateofCharge : 48|16@1+ (0.0015625,0) [0|100.3984375] "%" Vector__XXX

BO_ 2364654590 HVESP4D6: 8 Vector__XXX
 SG_ HVESP4BusVoltage : 0|16@1+ (0.05,0) [0|3212.75] "V" Vector__XXX
 SG_ HVESP4IgnitionVoltage : 16|16@1+ (0.01,0) [0|642.55] "V" Vector__XXX
 SG_ HVESP4IntakeCoolantTemperature : 32|8@1+ (1,-40) [-40|210] "degC" Vector__XXX
 SG_ HVESP4OutletCoolantTemperature : 40|8@1+ (1,-40) [-40|210] "degC" Vector__XXX
 SG_ HVESP4ElectronicsTemperature : 48|8@1+ (1,-40) [-40|210] "degC" Vector__XXX
 SG_ HVESP4Temperature : 56|8@1+ (1,-40) [-40|210] "degC" Vector__XXX

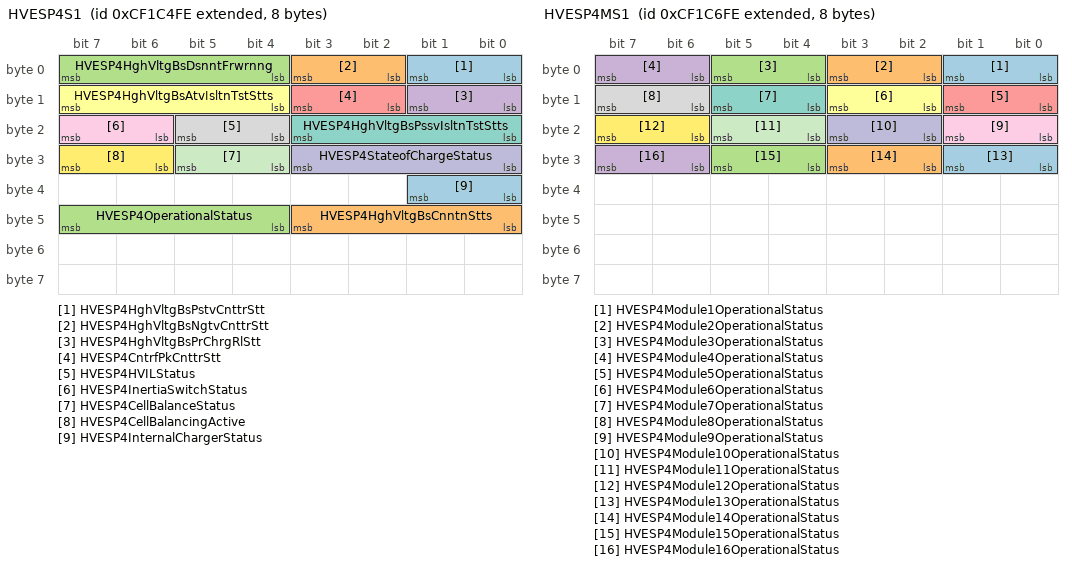
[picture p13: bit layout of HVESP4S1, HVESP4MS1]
BO_ 2364654846 HVESP4S1: 8 Vector__XXX
 SG_ HVESP4HghVltgBsPstvCnttrStt : 0|2@1+ (1,0) [0|3] "" Vector__XXX
 SG_ HVESP4HghVltgBsNgtvCnttrStt : 2|2@1+ (1,0) [0|3] "" Vector__XXX
 SG_ HVESP4HghVltgBsDsnntFrwrnng : 4|4@1+ (1,0) [0|15] "" Vector__XXX
 SG_ HVESP4HghVltgBsPrChrgRlStt : 8|2@1+ (1,0) [0|3] "" Vector__XXX
 SG_ HVESP4CntrfPkCnttrStt : 10|2@1+ (1,0) [0|3] "" Vector__XXX
 SG_ HVESP4HghVltgBsAtvIsltnTstStts : 12|4@1+ (1,0) [0|15] "" Vector__XXX
 SG_ HVESP4HghVltgBsPssvIsltnTstStts : 16|4@1+ (1,0) [0|15] "" Vector__XXX
 SG_ HVESP4HVILStatus : 20|2@1+ (1,0) [0|3] "" Vector__XXX
 SG_ HVESP4InertiaSwitchStatus : 22|2@1+ (1,0) [0|3] "" Vector__XXX
 SG_ HVESP4StateofChargeStatus : 24|4@1+ (1,0) [0|15] "" Vector__XXX
 SG_ HVESP4CellBalanceStatus : 28|2@1+ (1,0) [0|3] "" Vector__XXX
 SG_ HVESP4CellBalancingActive : 30|2@1+ (1,0) [0|3] "" Vector__XXX
 SG_ HVESP4InternalChargerStatus : 32|2@1+ (1,0) [0|3] "" Vector__XXX
 SG_ HVESP4HghVltgBsCnntnStts : 40|4@1+ (1,0) [0|15] "" Vector__XXX
 SG_ HVESP4OperationalStatus : 44|4@1+ (1,0) [0|15] "" Vector__XXX

BO_ 2364655102 HVESP4D7: 8 Vector__XXX
 SG_ HVESP4DischargeEnergyCapacity : 0|24@1+ (0.001,0) [0|16449.535] "kWh" Vector__XXX
 SG_ HVESP4ChargeEnergyCapacity : 24|24@1+ (0.001,0) [0|16449.535] "kWh" Vector__XXX
 SG_ HVESP4MaximumChargeVoltageLimit : 48|16@1+ (0.05,0) [0|3212.75] "V" Vector__XXX

BO_ 2364655358 HVESP4MS1: 8 Vector__XXX
 SG_ HVESP4Module1OperationalStatus : 0|2@1+ (1,0) [0|3] "" Vector__XXX
 SG_ HVESP4Module2OperationalStatus : 2|2@1+ (1,0) [0|3] "" Vector__XXX
 SG_ HVESP4Module3OperationalStatus : 4|2@1+ (1,0) [0|3] "" Vector__XXX
 SG_ HVESP4Module4OperationalStatus : 6|2@1+ (1,0) [0|3] "" Vector__XXX
 SG_ HVESP4Module5OperationalStatus : 8|2@1+ (1,0) [0|3] "" Vector__XXX
 SG_ HVESP4Module6OperationalStatus : 10|2@1+ (1,0) [0|3] "" Vector__XXX
 SG_ HVESP4Module7OperationalStatus : 12|2@1+ (1,0) [0|3] "" Vector__XXX
 SG_ HVESP4Module8OperationalStatus : 14|2@1+ (1,0) [0|3] "" Vector__XXX
 SG_ HVESP4Module9OperationalStatus : 16|2@1+ (1,0) [0|3] "" Vector__XXX
 SG_ HVESP4Module10OperationalStatus : 18|2@1+ (1,0) [0|3] "" Vector__XXX
 SG_ HVESP4Module11OperationalStatus : 20|2@1+ (1,0) [0|3] "" Vector__XXX
 SG_ HVESP4Module12OperationalStatus : 22|2@1+ (1,0) [0|3] "" Vector__XXX
 SG_ HVESP4Module13OperationalStatus : 24|2@1+ (1,0) [0|3] "" Vector__XXX
 SG_ HVESP4Module14OperationalStatus : 26|2@1+ (1,0) [0|3] "" Vector__XXX
 SG_ HVESP4Module15OperationalStatus : 28|2@1+ (1,0) [0|3] "" Vector__XXX
 SG_ HVESP4Module16OperationalStatus : 30|2@1+ (1,0) [0|3] "" Vector__XXX

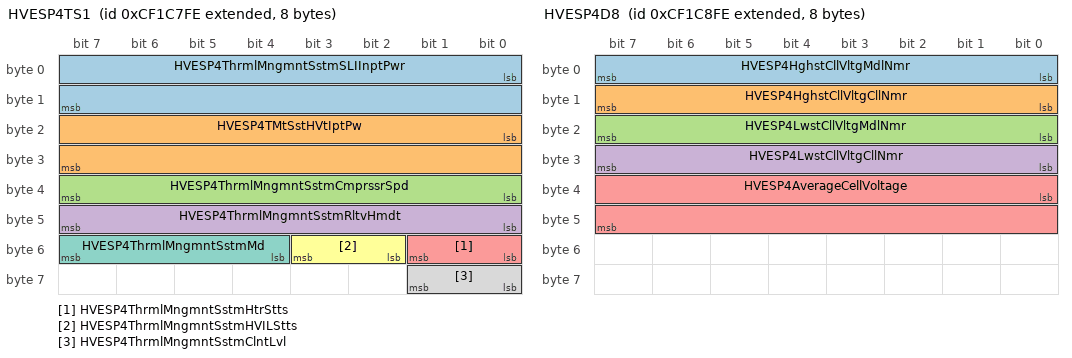
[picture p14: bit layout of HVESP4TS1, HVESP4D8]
BO_ 2364655614 HVESP4TS1: 8 Vector__XXX
 SG_ HVESP4ThrmlMngmntSstmSLIInptPwr : 0|16@1+ (0.5,0) [0|32127.5] "W" Vector__XXX
 SG_ HVESP4TMtSstHVtIptPw : 16|16@1+ (0.5,0) [0|32127.5] "W" Vector__XXX
 SG_ HVESP4ThrmlMngmntSstmCmprssrSpd : 32|8@1+ (32,0) [0|8000] "rpm" Vector__XXX
 SG_ HVESP4ThrmlMngmntSstmRltvHmdt : 40|8@1+ (0.4,0) [0|100] "%" Vector__XXX
 SG_ HVESP4ThrmlMngmntSstmHtrStts : 48|2@1+ (1,0) [0|3] "" Vector__XXX
 SG_ HVESP4ThrmlMngmntSstmHVILStts : 50|2@1+ (1,0) [0|3] "" Vector__XXX
 SG_ HVESP4ThrmlMngmntSstmMd : 52|4@1+ (1,0) [0|15] "" Vector__XXX
 SG_ HVESP4ThrmlMngmntSstmClntLvl : 56|2@1+ (1,0) [0|3] "" Vector__XXX

BO_ 2364655870 HVESP4D8: 8 Vector__XXX
 SG_ HVESP4HghstCllVltgMdlNmr : 0|8@1+ (1,0) [0|250] "count" Vector__XXX
 SG_ HVESP4HghstCllVltgCllNmr : 8|8@1+ (1,0) [0|250] "count" Vector__XXX
 SG_ HVESP4LwstCllVltgMdlNmr : 16|8@1+ (1,0) [0|250] "count" Vector__XXX
 SG_ HVESP4LwstCllVltgCllNmr : 24|8@1+ (1,0) [0|250] "count" Vector__XXX
 SG_ HVESP4AverageCellVoltage : 32|16@1+ (0.001,0) [0|64.255] "V" Vector__XXX

BO_ 2364656126 HVESP4D9: 8 Vector__XXX
 SG_ HVESP4HghstCllTmprtrMdlNmr : 0|8@1+ (1,0) [0|250] "count" Vector__XXX
 SG_ HVESP4HghstCllTmprtrCllNmr : 8|8@1+ (1,0) [0|250] "count" Vector__XXX
 SG_ HVESP4LwstCllTmprtrMdlNmr : 16|8@1+ (1,0) [0|250] "count" Vector__XXX
 SG_ HVESP4LwstCllTmprtrCllNmr : 24|8@1+ (1,0) [0|250] "count" Vector__XXX

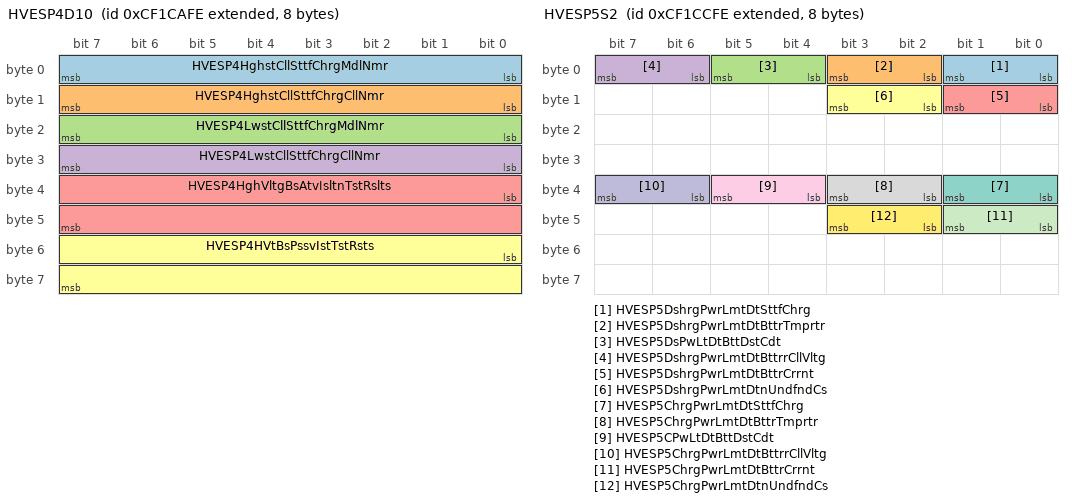
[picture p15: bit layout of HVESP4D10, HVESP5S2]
BO_ 2364656382 HVESP4D10: 8 Vector__XXX
 SG_ HVESP4HghstCllSttfChrgMdlNmr : 0|8@1+ (1,0) [0|250] "count" Vector__XXX
 SG_ HVESP4HghstCllSttfChrgCllNmr : 8|8@1+ (1,0) [0|250] "count" Vector__XXX
 SG_ HVESP4LwstCllSttfChrgMdlNmr : 16|8@1+ (1,0) [0|250] "count" Vector__XXX
 SG_ HVESP4LwstCllSttfChrgCllNmr : 24|8@1+ (1,0) [0|250] "count" Vector__XXX
 SG_ HVESP4HghVltgBsAtvIsltnTstRslts : 32|16@1+ (0.1,0) [0|6425.5] "ohm/V" Vector__XXX
 SG_ HVESP4HVtBsPssvIstTstRsts : 48|16@1+ (0.1,0) [0|6425.5] "ohm/V" Vector__XXX

BO_ 2364656638 HVESP4D11: 8 Vector__XXX
 SG_ HVESP4BsVltgNgtvtChsssGrndVltg : 0|16@1+ (0.05,0) [0|3212.75] "V" Vector__XXX
 SG_ HVESP4VltgLvlNgtvtChsssGrndVltg : 16|16@1+ (0.05,0) [0|3212.75] "V" Vector__XXX

BO_ 2364656894 HVESP5S2: 8 Vector__XXX
 SG_ HVESP5DshrgPwrLmtDtSttfChrg : 0|2@1+ (1,0) [0|3] "" Vector__XXX
 SG_ HVESP5DshrgPwrLmtDtBttrTmprtr : 2|2@1+ (1,0) [0|3] "" Vector__XXX
 SG_ HVESP5DsPwLtDtBttDstCdt : 4|2@1+ (1,0) [0|3] "" Vector__XXX
 SG_ HVESP5DshrgPwrLmtDtBttrrCllVltg : 6|2@1+ (1,0) [0|3] "" Vector__XXX
 SG_ HVESP5DshrgPwrLmtDtBttrCrrnt : 8|2@1+ (1,0) [0|3] "" Vector__XXX
 SG_ HVESP5DshrgPwrLmtDtnUndfndCs : 10|2@1+ (1,0) [0|3] "" Vector__XXX
 SG_ HVESP5ChrgPwrLmtDtSttfChrg : 32|2@1+ (1,0) [0|3] "" Vector__XXX
 SG_ HVESP5ChrgPwrLmtDtBttrTmprtr : 34|2@1+ (1,0) [0|3] "" Vector__XXX
 SG_ HVESP5CPwLtDtBttDstCdt : 36|2@1+ (1,0) [0|3] "" Vector__XXX
 SG_ HVESP5ChrgPwrLmtDtBttrrCllVltg : 38|2@1+ (1,0) [0|3] "" Vector__XXX
 SG_ HVESP5ChrgPwrLmtDtBttrCrrnt : 40|2@1+ (1,0) [0|3] "" Vector__XXX
 SG_ HVESP5ChrgPwrLmtDtnUndfndCs : 42|2@1+ (1,0) [0|3] "" Vector__XXX

BO_ 2364657150 HVESP5D1: 8 Vector__XXX
 SG_ HVESP5AvailableDischargePower : 0|16@1+ (0.05,0) [0|3212.75] "kW" Vector__XXX
 SG_ HVESP5AvailableChargePower : 16|16@1+ (0.05,0) [0|3212.75] "kW" Vector__XXX
 SG_ HVESP5VoltageLevel : 32|16@1+ (0.05,0) [0|3212.75] "V" Vector__XXX
 SG_ HVESP5Current : 48|16@1+ (0.05,-1600) [-1600|1612.75] "A" Vector__XXX

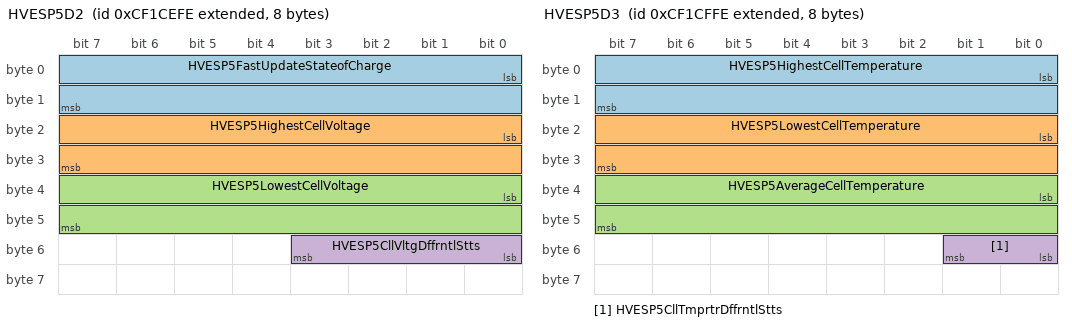
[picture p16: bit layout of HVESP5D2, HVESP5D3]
BO_ 2364657406 HVESP5D2: 8 Vector__XXX
 SG_ HVESP5FastUpdateStateofCharge : 0|16@1+ (0.0015625,0) [0|100.3984375] "%" Vector__XXX
 SG_ HVESP5HighestCellVoltage : 16|16@1+ (0.001,0) [0|64.255] "V" Vector__XXX
 SG_ HVESP5LowestCellVoltage : 32|16@1+ (0.001,0) [0|64.255] "V" Vector__XXX
 SG_ HVESP5CllVltgDffrntlStts : 48|4@1+ (1,0) [0|15] "" Vector__XXX

BO_ 2364657662 HVESP5D3: 8 Vector__XXX
 SG_ HVESP5HighestCellTemperature : 0|16@1+ (0.03125,-273) [-273|1734.96875] "degC" Vector__XXX
 SG_ HVESP5LowestCellTemperature : 16|16@1+ (0.03125,-273) [-273|1734.96875] "degC" Vector__XXX
 SG_ HVESP5AverageCellTemperature : 32|16@1+ (0.03125,-273) [-273|1734.96875] "degC" Vector__XXX
 SG_ HVESP5CllTmprtrDffrntlStts : 48|2@1+ (1,0) [0|3] "" Vector__XXX

BO_ 2364657918 HVESP5D4: 8 Vector__XXX
 SG_ HVESP5DischargeCapacity : 0|16@1+ (0.01,0) [0|642.55] "Ah" Vector__XXX
 SG_ HVESP5ChargeCapacity : 16|16@1+ (0.01,0) [0|642.55] "Ah" Vector__XXX
 SG_ HVESP5CellBalancingCount : 32|16@1+ (1,0) [0|64255] "count" Vector__XXX

BO_ 2364658174 HVESP5D5: 8 Vector__XXX
 SG_ HVESP5DischargeCurrentLimit : 0|16@1+ (0.05,-1600) [-1600|1612.75] "A" Vector__XXX
 SG_ HVESP5ChargeCurrentLimit : 16|16@1+ (0.05,-1600) [-1600|1612.75] "A" Vector__XXX
 SG_ HVESP5LowestCellStateofCharge : 32|16@1+ (0.0015625,0) [0|100.3984375] "%" Vector__XXX
 SG_ HVESP5HighestCellStateofCharge : 48|16@1+ (0.0015625,0) [0|100.3984375] "%" Vector__XXX

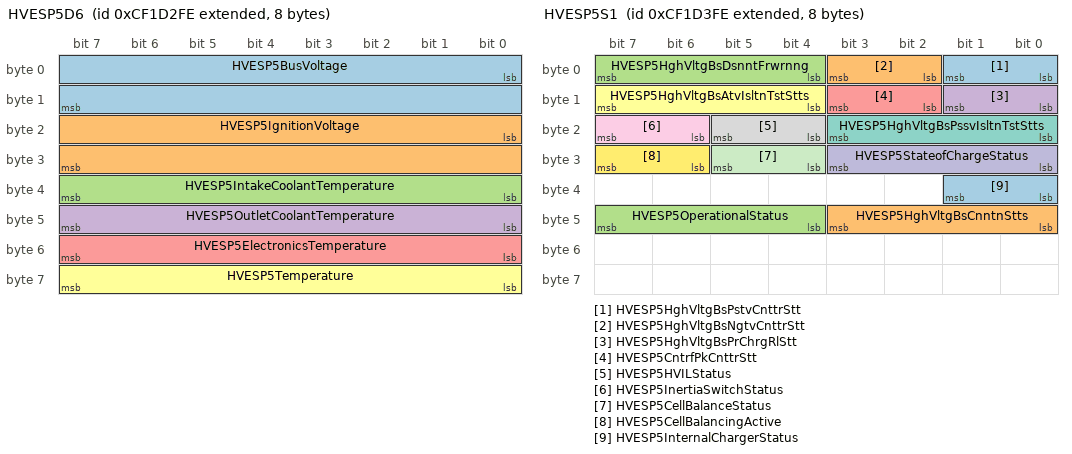
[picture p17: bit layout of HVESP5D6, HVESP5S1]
BO_ 2364658430 HVESP5D6: 8 Vector__XXX
 SG_ HVESP5BusVoltage : 0|16@1+ (0.05,0) [0|3212.75] "V" Vector__XXX
 SG_ HVESP5IgnitionVoltage : 16|16@1+ (0.01,0) [0|642.55] "V" Vector__XXX
 SG_ HVESP5IntakeCoolantTemperature : 32|8@1+ (1,-40) [-40|210] "degC" Vector__XXX
 SG_ HVESP5OutletCoolantTemperature : 40|8@1+ (1,-40) [-40|210] "degC" Vector__XXX
 SG_ HVESP5ElectronicsTemperature : 48|8@1+ (1,-40) [-40|210] "degC" Vector__XXX
 SG_ HVESP5Temperature : 56|8@1+ (1,-40) [-40|210] "degC" Vector__XXX

BO_ 2364658686 HVESP5S1: 8 Vector__XXX
 SG_ HVESP5HghVltgBsPstvCnttrStt : 0|2@1+ (1,0) [0|3] "" Vector__XXX
 SG_ HVESP5HghVltgBsNgtvCnttrStt : 2|2@1+ (1,0) [0|3] "" Vector__XXX
 SG_ HVESP5HghVltgBsDsnntFrwrnng : 4|4@1+ (1,0) [0|15] "" Vector__XXX
 SG_ HVESP5HghVltgBsPrChrgRlStt : 8|2@1+ (1,0) [0|3] "" Vector__XXX
 SG_ HVESP5CntrfPkCnttrStt : 10|2@1+ (1,0) [0|3] "" Vector__XXX
 SG_ HVESP5HghVltgBsAtvIsltnTstStts : 12|4@1+ (1,0) [0|15] "" Vector__XXX
 SG_ HVESP5HghVltgBsPssvIsltnTstStts : 16|4@1+ (1,0) [0|15] "" Vector__XXX
 SG_ HVESP5HVILStatus : 20|2@1+ (1,0) [0|3] "" Vector__XXX
 SG_ HVESP5InertiaSwitchStatus : 22|2@1+ (1,0) [0|3] "" Vector__XXX
 SG_ HVESP5StateofChargeStatus : 24|4@1+ (1,0) [0|15] "" Vector__XXX
 SG_ HVESP5CellBalanceStatus : 28|2@1+ (1,0) [0|3] "" Vector__XXX
 SG_ HVESP5CellBalancingActive : 30|2@1+ (1,0) [0|3] "" Vector__XXX
 SG_ HVESP5InternalChargerStatus : 32|2@1+ (1,0) [0|3] "" Vector__XXX
 SG_ HVESP5HghVltgBsCnntnStts : 40|4@1+ (1,0) [0|15] "" Vector__XXX
 SG_ HVESP5OperationalStatus : 44|4@1+ (1,0) [0|15] "" Vector__XXX

BO_ 2364658942 HVESP5D7: 8 Vector__XXX
 SG_ HVESP5DischargeEnergyCapacity : 0|24@1+ (0.001,0) [0|16449.535] "kWh" Vector__XXX
 SG_ HVESP5ChargeEnergyCapacity : 24|24@1+ (0.001,0) [0|16449.535] "kWh" Vector__XXX
 SG_ HVESP5MaximumChargeVoltageLimit : 48|16@1+ (0.05,0) [0|3212.75] "V" Vector__XXX

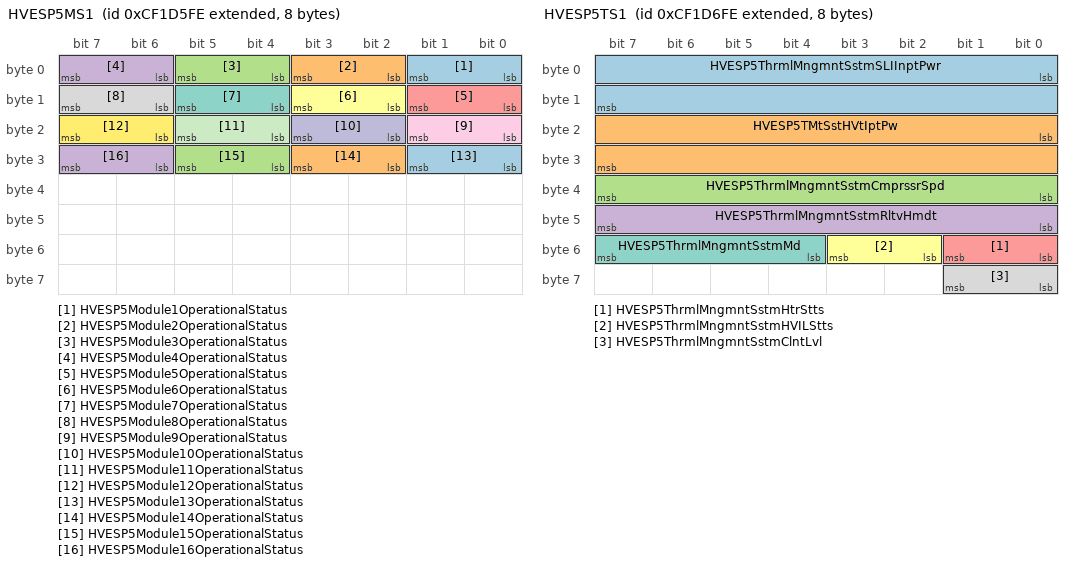
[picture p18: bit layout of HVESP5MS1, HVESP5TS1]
BO_ 2364659198 HVESP5MS1: 8 Vector__XXX
 SG_ HVESP5Module1OperationalStatus : 0|2@1+ (1,0) [0|3] "" Vector__XXX
 SG_ HVESP5Module2OperationalStatus : 2|2@1+ (1,0) [0|3] "" Vector__XXX
 SG_ HVESP5Module3OperationalStatus : 4|2@1+ (1,0) [0|3] "" Vector__XXX
 SG_ HVESP5Module4OperationalStatus : 6|2@1+ (1,0) [0|3] "" Vector__XXX
 SG_ HVESP5Module5OperationalStatus : 8|2@1+ (1,0) [0|3] "" Vector__XXX
 SG_ HVESP5Module6OperationalStatus : 10|2@1+ (1,0) [0|3] "" Vector__XXX
 SG_ HVESP5Module7OperationalStatus : 12|2@1+ (1,0) [0|3] "" Vector__XXX
 SG_ HVESP5Module8OperationalStatus : 14|2@1+ (1,0) [0|3] "" Vector__XXX
 SG_ HVESP5Module9OperationalStatus : 16|2@1+ (1,0) [0|3] "" Vector__XXX
 SG_ HVESP5Module10OperationalStatus : 18|2@1+ (1,0) [0|3] "" Vector__XXX
 SG_ HVESP5Module11OperationalStatus : 20|2@1+ (1,0) [0|3] "" Vector__XXX
 SG_ HVESP5Module12OperationalStatus : 22|2@1+ (1,0) [0|3] "" Vector__XXX
 SG_ HVESP5Module13OperationalStatus : 24|2@1+ (1,0) [0|3] "" Vector__XXX
 SG_ HVESP5Module14OperationalStatus : 26|2@1+ (1,0) [0|3] "" Vector__XXX
 SG_ HVESP5Module15OperationalStatus : 28|2@1+ (1,0) [0|3] "" Vector__XXX
 SG_ HVESP5Module16OperationalStatus : 30|2@1+ (1,0) [0|3] "" Vector__XXX

BO_ 2364659454 HVESP5TS1: 8 Vector__XXX
 SG_ HVESP5ThrmlMngmntSstmSLIInptPwr : 0|16@1+ (0.5,0) [0|32127.5] "W" Vector__XXX
 SG_ HVESP5TMtSstHVtIptPw : 16|16@1+ (0.5,0) [0|32127.5] "W" Vector__XXX
 SG_ HVESP5ThrmlMngmntSstmCmprssrSpd : 32|8@1+ (32,0) [0|8000] "rpm" Vector__XXX
 SG_ HVESP5ThrmlMngmntSstmRltvHmdt : 40|8@1+ (0.4,0) [0|100] "%" Vector__XXX
 SG_ HVESP5ThrmlMngmntSstmHtrStts : 48|2@1+ (1,0) [0|3] "" Vector__XXX
 SG_ HVESP5ThrmlMngmntSstmHVILStts : 50|2@1+ (1,0) [0|3] "" Vector__XXX
 SG_ HVESP5ThrmlMngmntSstmMd : 52|4@1+ (1,0) [0|15] "" Vector__XXX
 SG_ HVESP5ThrmlMngmntSstmClntLvl : 56|2@1+ (1,0) [0|3] "" Vector__XXX

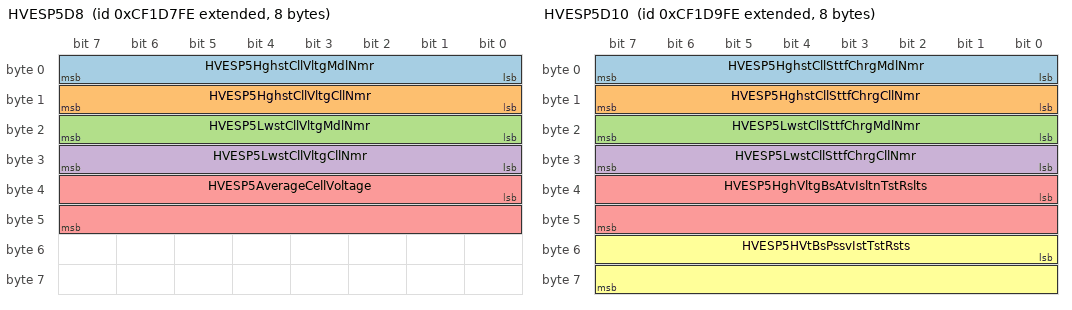
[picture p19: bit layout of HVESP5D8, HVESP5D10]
BO_ 2364659710 HVESP5D8: 8 Vector__XXX
 SG_ HVESP5HghstCllVltgMdlNmr : 0|8@1+ (1,0) [0|250] "count" Vector__XXX
 SG_ HVESP5HghstCllVltgCllNmr : 8|8@1+ (1,0) [0|250] "count" Vector__XXX
 SG_ HVESP5LwstCllVltgMdlNmr : 16|8@1+ (1,0) [0|250] "count" Vector__XXX
 SG_ HVESP5LwstCllVltgCllNmr : 24|8@1+ (1,0) [0|250] "count" Vector__XXX
 SG_ HVESP5AverageCellVoltage : 32|16@1+ (0.001,0) [0|64.255] "V" Vector__XXX

BO_ 2364659966 HVESP5D9: 8 Vector__XXX
 SG_ HVESP5HghstCllTmprtrMdlNmr : 0|8@1+ (1,0) [0|250] "count" Vector__XXX
 SG_ HVESP5HghstCllTmprtrCllNmr : 8|8@1+ (1,0) [0|250] "count" Vector__XXX
 SG_ HVESP5LwstCllTmprtrMdlNmr : 16|8@1+ (1,0) [0|250] "count" Vector__XXX
 SG_ HVESP5LwstCllTmprtrCllNmr : 24|8@1+ (1,0) [0|250] "count" Vector__XXX

BO_ 2364660222 HVESP5D10: 8 Vector__XXX
 SG_ HVESP5HghstCllSttfChrgMdlNmr : 0|8@1+ (1,0) [0|250] "count" Vector__XXX
 SG_ HVESP5HghstCllSttfChrgCllNmr : 8|8@1+ (1,0) [0|250] "count" Vector__XXX
 SG_ HVESP5LwstCllSttfChrgMdlNmr : 16|8@1+ (1,0) [0|250] "count" Vector__XXX
 SG_ HVESP5LwstCllSttfChrgCllNmr : 24|8@1+ (1,0) [0|250] "count" Vector__XXX
 SG_ HVESP5HghVltgBsAtvIsltnTstRslts : 32|16@1+ (0.1,0) [0|6425.5] "ohm/V" Vector__XXX
 SG_ HVESP5HVtBsPssvIstTstRsts : 48|16@1+ (0.1,0) [0|6425.5] "ohm/V" Vector__XXX

BO_ 2364660478 HVESP5D11: 8 Vector__XXX
 SG_ HVESP5BsVltgNgtvtChsssGrndVltg : 0|16@1+ (0.05,0) [0|3212.75] "V" Vector__XXX
 SG_ HVESP5VltgLvlNgtvtChsssGrndVltg : 16|16@1+ (0.05,0) [0|3212.75] "V" Vector__XXX

CM_ BO_ 2364643838 "High Voltage Energy Storage Pack 1 Module Status 1";
CM_ SG_ 2364643838 HVESP1Module1OperationalStatus "HVESP1 Module 1 Operational Status: Operational Status of Module 1 in this High Voltage Energy Storage Pack Instance.  Not Operational is used when the module is initializing or not able to function (e.g. internal module level monitors have failed). ...";
CM_ SG_ 2364643838 HVESP1Module2OperationalStatus "HVESP1 Module 2 Operational Status: Operational Status of Module 2 in this High Voltage Energy Storage Pack Instance.  Not Operational is used when the module is initializing or not able to function (e.g. internal module level monitors have failed). ...";
CM_ SG_ 2364643838 HVESP1Module3OperationalStatus "HVESP1 Module 3 Operational Status: Operational Status of Module 3 in this High Voltage Energy Storage Pack Instance.  Not Operational is used when the module is initializing or not able to function (e.g. internal module level monitors have failed). ...";
CM_ SG_ 2364643838 HVESP1Module4OperationalStatus "HVESP1 Module 4 Operational Status: Operational Status of Module 4 in this High Voltage Energy Storage Pack Instance.  Not Operational is used when the module is initializing or not able to function (e.g. internal module level monitors have failed). ...";
CM_ SG_ 2364643838 HVESP1Module5OperationalStatus "HVESP1 Module 5 Operational Status: Operational Status of Module 5 in this High Voltage Energy Storage Pack Instance.  Not Operational is used when the module is initializing or not able to function (e.g. internal module level monitors have failed). ...";
CM_ SG_ 2364643838 HVESP1Module6OperationalStatus "HVESP1 Module 6 Operational Status: Operational Status of Module 6 in this High Voltage Energy Storage Pack Instance.  Not Operational is used when the module is initializing or not able to function (e.g. internal module level monitors have failed). ...";
CM_ SG_ 2364643838 HVESP1Module7OperationalStatus "HVESP1 Module 7 Operational Status: Operational Status of Module 7 in this High Voltage Energy Storage Pack Instance.  Not Operational is used when the module is initializing or not able to function (e.g. internal module level monitors have failed). ...";
CM_ SG_ 2364643838 HVESP1Module8OperationalStatus "HVESP1 Module 8 Operational Status: Operational Status of Module 8 in this High Voltage Energy Storage Pack Instance.  Not Operational is used when the module is initializing or not able to function (e.g. internal module level monitors have failed). ...";
CM_ SG_ 2364643838 HVESP1Module9OperationalStatus "HVESP1 Module 9 Operational Status: Operational Status of Module 9 in this High Voltage Energy Storage Pack Instance.  Not Operational is used when the module is initializing or not able to function (e.g. internal module level monitors have failed). ...";
CM_ SG_ 2364643838 HVESP1Module10OperationalStatus "HVESP1 Module 10 Operational Status: Operational Status of Module 10 in this High Voltage Energy Storage Pack Instance.  Not Operational is used when the module is initializing or not able to function (e.g. internal module level monitors have failed)...";
CM_ SG_ 2364643838 HVESP1Module11OperationalStatus "HVESP1 Module 11 Operational Status: Operational Status of Module 11 in this High Voltage Energy Storage Pack Instance.  Not Operational is used when the module is initializing or not able to function (e.g. internal module level monitors have failed)...";
CM_ SG_ 2364643838 HVESP1Module12OperationalStatus "HVESP1 Module 12 Operational Status: Operational Status of Module 12 in this High Voltage Energy Storage Pack Instance.  Not Operational is used when the module is initializing or not able to function (e.g. internal module level monitors have failed)...";
CM_ SG_ 2364643838 HVESP1Module13OperationalStatus "HVESP1 Module 13 Operational Status: Operational Status of Module 13 in this High Voltage Energy Storage Pack Instance.  Not Operational is used when the module is initializing or not able to function (e.g. internal module level monitors have failed)...";
CM_ SG_ 2364643838 HVESP1Module14OperationalStatus "HVESP1 Module 14 Operational Status: Operational Status of Module 14 in this High Voltage Energy Storage Pack Instance.  Not Operational is used when the module is initializing or not able to function (e.g. internal module level monitors have failed)...";
CM_ SG_ 2364643838 HVESP1Module15OperationalStatus "HVESP1 Module 15 Operational Status: Operational Status of Module 15 in this High Voltage Energy Storage Pack Instance.  Not Operational is used when the module is initializing or not able to function (e.g. internal module level monitors have failed)...";
CM_ SG_ 2364643838 HVESP1Module16OperationalStatus "HVESP1 Module 16 Operational Status: Operational Status of Module 16 in this High Voltage Energy Storage Pack Instance.  Not Operational is used when the module is initializing or not able to function (e.g. internal module level monitors have failed)...";
CM_ BO_ 2364644094 "High Voltage Energy Storage Pack 1 Thermal Management System Status 1";
CM_ SG_ 2364644094 HVESP1ThrmlMngmntSstmSLIInptPwr "HVESP1 Thermal Management System SLI Input Power: This is the low-voltage power consumed by this HVES Thermal Management System (TMS).This parameter is for one of multiple packs in an HVESS.  If there is only one pack in the system, the HVESS paramet...";
CM_ SG_ 2364644094 HVESP1TMtSstHVtIptPw "HVESP1 Thermal Management System High-Voltage Input Power: This is the high-voltage power consumed by this HVES Thermal Management System (TMS).This parameter is for one of multiple packs in an HVESS.  If there is only one pack in the system, the HVE...";
CM_ SG_ 2364644094 HVESP1ThrmlMngmntSstmCmprssrSpd "HVESP1 Thermal Management System Compressor Speed: When this High Voltage Energy Storage Pack Thermal Management System is equipped with an active cooling system (e.g. air conditioner), this is the Compressor Speed.This parameter is for one of multip...";
CM_ SG_ 2364644094 HVESP1ThrmlMngmntSstmRltvHmdt "HVESP1 Thermal Management System Relative Humidty: When this High Voltage Energy Storage Pack Thermal Management System is equipped with a relative humidity sensor, this is the  measured Relative Humidity.This parameter is for one of multiple packs i...";
CM_ SG_ 2364644094 HVESP1ThrmlMngmntSstmHtrStts "HVESP1 Thermal Management System Heater Status: The state of this High Voltage Energy Storage Pack heaterThis parameter is for one of multiple packs in an HVESS.  If there is only one pack in the system, the HVESS parameters should be used. If there ...";
CM_ SG_ 2364644094 HVESP1ThrmlMngmntSstmHVILStts "HVESP1 Thermal Management System HVIL Status: In multiple HVES configurations, this is the status of the High Voltage Interlock Loop from the viewpoint of this Thermal Management System.00b = HVIL Closed01b = HVIL Open10b = Error11b = Not AvailableTh...";
CM_ SG_ 2364644094 HVESP1ThrmlMngmntSstmMd "HVESP1 Thermal Management System Mode: Indicates the operating mode of the Thermal Management System.  The heat transfer medium may be (e.g. liquid or air).  The cooling system may be fans, liquid coolant, or a combination of mediums.  The system may...";
CM_ SG_ 2364644094 HVESP1ThrmlMngmntSstmClntLvl "HVESP1 Thermal Management System Coolant Level: Indicates the coolant level in this HVES Thermal Management System (TMS).This parameter is for one of multiple packs in an HVESS.  If there is only one pack in the system, the HVESS parameters should be...";
CM_ BO_ 2364644350 "High Voltage Energy Storage Pack 1 Data 8";
CM_ SG_ 2364644350 HVESP1HghstCllVltgMdlNmr "HVESP1 Highest Cell Voltage Module Number: Identifies the location of the module containing SPN 11055 (HVESP1 Highest Cell Voltage).This parameter is for one of multiple packs in an HVESS.  If there is only one pack in the system, the HVESS parameter...";
CM_ SG_ 2364644350 HVESP1HghstCllVltgCllNmr "HVESP1 Highest Cell Voltage Cell Number: Identifies the location of SPN 11055 (HVESP1 Highest Cell Voltage) within SPN 11115 (HVESP1 Highest Cell Voltage Module Number).This parameter is for one of multiple packs in an HVESS.  If there is only one pa...";
CM_ SG_ 2364644350 HVESP1LwstCllVltgMdlNmr "HVESP1 Lowest Cell Voltage Module Number: Identifies the location of the module containing SPN 11056 (HVESP1 Lowest Cell Voltage).This parameter is for one of multiple packs in an HVESS.  If there is only one pack in the system, the HVESS parameters ...";
CM_ SG_ 2364644350 HVESP1LwstCllVltgCllNmr "HVESP1 Lowest Cell Voltage Cell Number: Identifies the location of SPN 11056 (HVESP1 Lowest Cell Voltage) within SPN 11117 (HVESP1 Lowest Cell Voltage Module Number).This parameter is for one of multiple packs in an HVESS.  If there is only one pack ...";
CM_ SG_ 2364644350 HVESP1AverageCellVoltage "HVESP1 Average Cell Voltage: The average cell voltage in this High Voltage Energy Storage Pack instance.This parameter is for one of multiple packs in an HVESS.  If there is only one pack in the system, the HVESS parameters should be used. If there a...";
CM_ BO_ 2364644606 "High Voltage Energy Storage Pack 1 Data 9";
CM_ SG_ 2364644606 HVESP1HghstCllTmprtrMdlNmr "HVESP1 Highest Cell Temperature Module Number: Identifies the location of the module containing SPN 11058 (HVESP1 Highest Cell Temperature).This parameter is for one of multiple packs in an HVESS.  If there is only one pack in the system, the HVESS p...";
CM_ SG_ 2364644606 HVESP1HghstCllTmprtrCllNmr "HVESP1 Highest Cell Temperature Cell Number: Identifies the location of SPN 11058 (HVESP1 Highest Cell Temperature) within SPN 11120 (HVESP1 Highest Cell Temperature Module Number).This parameter is for one of multiple packs in an HVESS.  If there is...";
CM_ SG_ 2364644606 HVESP1LwstCllTmprtrMdlNmr "HVESP1 Lowest Cell Temperature Module Number: Identifies the location of the module containing SPN 11059 (HVESP1 Lowest Cell Temperature).This parameter is for one of multiple packs in an HVESS.  If there is only one pack in the system, the HVESS par...";
CM_ SG_ 2364644606 HVESP1LwstCllTmprtrCllNmr "HVESP1 Lowest Cell Temperature Cell Number: Identifies the location of SPN 11059 (HVESP1 Lowest Cell Temperature) within SPN 11122 (HVESP1 Lowest Cell Temperature Module Number).This parameter is for one of multiple packs in an HVESS.  If there is on...";
CM_ BO_ 2364644862 "High Voltage Energy Storage Pack 1 Data 10";
CM_ SG_ 2364644862 HVESP1HghstCllSttfChrgMdlNmr "HVESP1 Highest Cell State of Charge Module Number: Identifies the location of the module containing SPN 11068 (HVESP1 Highest Cell State of Charge).This parameter is for one of multiple packs in an HVESS.  If there is only one pack in the system, the...";
CM_ SG_ 2364644862 HVESP1HghstCllSttfChrgCllNmr "HVESP1 Highest Cell State of Charge Cell Number: Identifies the location of SPN 11068 (HVESP1 Highest Cell State of Charge) within SPN 11124 (HVESP1 Highest Cell State of Charge Module Number).This parameter is for one of multiple packs in an HVESS. ...";
CM_ SG_ 2364644862 HVESP1LwstCllSttfChrgMdlNmr "HVESP1 Lowest Cell State of Charge Module Number: Identifies the location of the module containing SPN 11067 (HVESP1 Lowest Cell State of Charge).This parameter is for one of multiple packs in an HVESS.  If there is only one pack in the system, the H...";
CM_ SG_ 2364644862 HVESP1LwstCllSttfChrgCllNmr "HVESP1 Lowest Cell State of Charge Cell Number: Identifies the location of SPN 11067 (HVESP1 Lowest Cell State of Charge) within SPN 11126 (HVESP1 Lowest Cell State of Charge Module Number).This parameter is for one of multiple packs in an HVESS.  If...";
CM_ SG_ 2364644862 HVESP1HghVltgBsAtvIsltnTstRslts "HVESP1 High-Voltage Bus Active Isolation Test Results: The isolation resistance expressed in Ohms per Volt that resulted from the High-Voltage Bus Active Isolation Test.See SPN 11080 (HVESP1 High-Voltage Bus Active Isolation Test Status) for test sta...";
CM_ SG_ 2364644862 HVESP1HVtBsPssvIstTstRsts "HVESP1 High-Voltage Bus Passive Isolation Test Results: The isolation resistance expressed in Ohms per Volt that resulted from the High-Voltage Bus Passive Isolation Test.See SPN 11081 (HVESP1 High-Voltage Bus Passive Isolation Test Status) for test ...";
CM_ BO_ 2364645118 "High Voltage Energy Storage Pack 1 Data 11";
CM_ SG_ 2364645118 HVESP1BsVltgNgtvtChsssGrndVltg "HVESP1 Bus Voltage Negative to Chassis Ground Voltage: Voltage difference between the most negative terminal of the HVES battery and chassis measured on the hybrid system bus side (not the battery side) of any HVES contained output contactor.  This v...";
CM_ SG_ 2364645118 HVESP1VltgLvlNgtvtChsssGrndVltg "HVESP1 Voltage Level Negative to Chassis Ground Voltage: Voltage difference between the most negative terminal of the HVES battery and chassis measured at the battery side of any HVES contained output contactor.  This voltage may be used for system l...";
CM_ BO_ 2364645374 "High Voltage Energy Storage Pack 2 Status 2";
CM_ SG_ 2364645374 HVESP2DshrgPwrLmtDtSttfChrg "HVESP2 Discharge Power Limit Due to State of Charge: Indicates whether or not discharge power of this HVES instance is being limited due to state of charge.This parameter is for one of multiple packs in an HVESS.  If there is only one pack in the sys...";
CM_ SG_ 2364645374 HVESP2DshrgPwrLmtDtBttrTmprtr "HVESP2 Discharge Power Limit Due to Battery Temperature: Indicates whether or not discharge power of this HVES instance is being limited due to battery temperature.This parameter is for one of multiple packs in an HVESS.  If there is only one pack in...";
CM_ SG_ 2364645374 HVESP2DsPwLtDtBttDstCdt "HVESP2 Discharge Power Limit Due to Battery Diagnostic Condition: Indicates whether or not discharge power of this HVES instance is being limited due to a battery diagnostic condition.This parameter is for one of multiple packs in an HVESS.  If there...";
CM_ SG_ 2364645374 HVESP2DshrgPwrLmtDtBttrrCllVltg "HVESP2 Discharge Power Limit Due to Battery or Cell Voltage: Indicates whether or not discharge power of this HVES instance is being limited due to a battery or cell voltage level.This parameter is for one of multiple packs in an HVESS.  If there is ...";
CM_ SG_ 2364645374 HVESP2DshrgPwrLmtDtBttrCrrnt "HVESP2 Discharge Power Limit Due to Battery Current: Indicates whether or not discharge power of this HVES instance is being limited due to battery current.This parameter is for one of multiple packs in an HVESS.  If there is only one pack in the sys...";
CM_ SG_ 2364645374 HVESP2DshrgPwrLmtDtnUndfndCs "HVESP2 Discharge Power Limit Due to an Undefined Cause: Indicates whether or not discharge power of this HVES instance is being limited due to an undefined cause.This parameter is for one of multiple packs in an HVESS.  If there is only one pack in t...";
CM_ SG_ 2364645374 HVESP2ChrgPwrLmtDtSttfChrg "HVESP2 Charge Power Limit Due to State of Charge: Indicates whether or not charge power of this HVES instance is being limited due to state of charge.This parameter is for one of multiple packs in an HVESS.  If there is only one pack in the system, t...";
CM_ SG_ 2364645374 HVESP2ChrgPwrLmtDtBttrTmprtr "HVESP2 Charge Power Limit Due to Battery Temperature: Indicates whether or not charge power of this HVES instance is being limited due to battery temperature.This parameter is for one of multiple packs in an HVESS.  If there is only one pack in the s...";
CM_ SG_ 2364645374 HVESP2CPwLtDtBttDstCdt "HVESP2 Charge Power Limit Due to Battery Diagnostic Condition: Indicates whether or not charge power of this HVES instance is being limited due to a battery diagnostic condition.This parameter is for one of multiple packs in an HVESS.  If there is on...";
CM_ SG_ 2364645374 HVESP2ChrgPwrLmtDtBttrrCllVltg "HVESP2 Charge Power Limit Due to Battery or Cell Voltage: Indicates whether or not charge power of this HVES instance is being limited due to a battery or cell voltage level.This parameter is for one of multiple packs in an HVESS.  If there is only o...";
CM_ SG_ 2364645374 HVESP2ChrgPwrLmtDtBttrCrrnt "HVESP2 Charge Power Limit Due to Battery Current: Indicates whether or not charge power of this HVES instance is being limited due to battery current.This parameter is for one of multiple packs in an HVESS.  If there is only one pack in the system, t...";
CM_ SG_ 2364645374 HVESP2ChrgPwrLmtDtnUndfndCs "HVESP2 Charge Power Limit Due to an Undefined Cause: Indicates whether or not charge power of this HVES instance is being limited due to an undefined cause.This parameter is for one of multiple packs in an HVESS.  If there is only one pack in the sys...";
CM_ BO_ 2364645630 "High Voltage Energy Storage Pack 2 Data 1";
CM_ SG_ 2364645630 HVESP2AvailableDischargePower "HVESP2 Available Discharge Power: The rate at which this High Voltage Energy Storage Pack instance can currently provide energy for propulsion or other uses.This parameter is for one of multiple packs in an HVESS.  If there is only one pack in the sy...";
CM_ SG_ 2364645630 HVESP2AvailableChargePower "HVESP2 Available Charge Power: The rate at which this High Voltage Energy Storage Pack instance can currently receive energy from a regenerative or recharging system.This parameter is for one of multiple packs in an HVESS.  If there is only one pack ...";
CM_ SG_ 2364645630 HVESP2VoltageLevel "HVESP2 Voltage Level: The voltage level of this High Voltage Energy Storage Pack instance. This parameter should be synchronized with SPN 11169 (HVESP2 Current) such that a realized power value can be calculated.  If the HVES component physically con...";
CM_ SG_ 2364645630 HVESP2Current "HVESP2 Current: The current in or out of this High Voltage Energy Storage Pack instance. This parameter should be synchronized with SPN 11168 (HVESP2 Voltage Level) such that a realized power value can be calculated.  This parameter is defined from t...";
CM_ BO_ 2364645886 "High Voltage Energy Storage Pack 2 Data 2";
CM_ SG_ 2364645886 HVESP2FastUpdateStateofCharge "HVESP2 Fast Update State of Charge: Indicates this High Voltage Energy Storage Pack instance state of charge.  0% means no charge remaining, 100% means the system is fully charged in terms of physical limits of this energy storage pack instance.  Acc...";
CM_ SG_ 2364645886 HVESP2HighestCellVoltage "HVESP2 Highest Cell Voltage: The highest voltage level reported by any cell in this High Voltage Energy Storage Pack instance. If a single voltage sensor covers more than one cell, the value in this parameter is for the smallest group of cells measur...";
CM_ SG_ 2364645886 HVESP2LowestCellVoltage "HVESP2 Lowest Cell Voltage: The lowest voltage level reported by any cell in this High Voltage Energy Storage Pack instance. If a single voltage sensor covers more than one cell, the value in this parameter is for the smallest group of cells measured...";
CM_ SG_ 2364645886 HVESP2CllVltgDffrntlStts "HVESP2 Cell Voltage Differential Status: Indicates whether or not the differential between the highest and lowest cell voltages are within acceptable limits, according to this High Voltage Energy Storage Pack instance. The actual voltage differential...";
CM_ BO_ 2364646142 "High Voltage Energy Storage Pack 2 Data 3";
CM_ SG_ 2364646142 HVESP2HighestCellTemperature "HVESP2 Highest Cell Temperature: The highest temperature level reported by any cell in this High Voltage Energy Storage Pack instance.  If a single temperature sensor covers more than one cell, the value in this parameter is for the smallest group of...";
CM_ SG_ 2364646142 HVESP2LowestCellTemperature "HVESP2 Lowest Cell Temperature: The lowest temperature level reported by any cell in this High Voltage Energy Storage Pack instance.  If a single temperature sensor covers more than one cell, the value in this parameter is for the smallest group of c...";
CM_ SG_ 2364646142 HVESP2AverageCellTemperature "HVESP2 Average Cell Temperature: The average temperature level of all cells in this High Voltage Energy Storage Pack instance.This parameter is for one of multiple packs in an HVESS.  If there is only one pack in the system, the HVESS parameters shou...";
CM_ SG_ 2364646142 HVESP2CllTmprtrDffrntlStts "HVESP2 Cell Temperature Differential Status: Indicates whether or not the differential between the highest and lowest cell temperatures are within acceptable limits per this High Voltage Energy Storage Pack instance.  The actual temperature different...";
CM_ BO_ 2364646398 "High Voltage Energy Storage Pack 2 Data 4";
CM_ SG_ 2364646398 HVESP2DischargeCapacity "HVESP2 Discharge Capacity: The amount of stored electrical charge in this High Voltage Energy Storage Pack instance that is available for use by the hybrid system, i.e. “how full is the tank”.  See SPN 11206 (HVESP2 Discharge Energy Capacity) for kil...";
CM_ SG_ 2364646398 HVESP2ChargeCapacity "HVESP2 Charge Capacity: The amount of unused electrical charge storage in this High Voltage Energy Storage Pack instance that is available to be filled by charging, i.e. “how much empty space is remaining in the tank”.  See SPN 11207 (HVESP2 Charge E...";
CM_ SG_ 2364646398 HVESP2CellBalancingCount "HVESP2 Cell Balancing Count: The number of cells that are currently being balanced in this High Voltage Energy Storage Pack instance.This parameter is for one of multiple packs in an HVESS.  If there is only one pack in the system, the HVESS paramete...";
CM_ BO_ 2364646654 "High Voltage Energy Storage Pack 2 Data 5";
CM_ SG_ 2364646654 HVESP2DischargeCurrentLimit "HVESP2 Discharge Current Limit: The maximum permissible current flow out of this High Voltage Energy Storage Pack instance. This parameter is defined from the high voltage energy storage pack's point of view.A negative value represents current flowin...";
CM_ SG_ 2364646654 HVESP2ChargeCurrentLimit "HVESP2 Charge Current Limit: The maximum permissible current flow into this High Voltage Energy Storage Pack instance. This parameter is defined from the high voltage energy storage pack's point of view.A positive value represents current flowing int...";
CM_ SG_ 2364646654 HVESP2LowestCellStateofCharge "HVESP2 Lowest Cell State of Charge: Indicates the state of charge of the lowest-charged cell in this High Voltage Energy Storage Pack instance.  0% means no charge remaining, 100% means the cell is fully charged.   If a single state of charge value c...";
CM_ SG_ 2364646654 HVESP2HighestCellStateofCharge "HVESP2 Highest Cell State of Charge: Indicates the state of charge of the highest-charged cell in this High Voltage Energy Storage Pack instance.  0% means no charge remaining, 100% means the cell is fully charged.  If a single state of charge value ...";
CM_ BO_ 2364646910 "High Voltage Energy Storage Pack 2 Data 6";
CM_ SG_ 2364646910 HVESP2BusVoltage "HVESP2 Bus Voltage: The voltage level of the high voltage bus, as measured by this High Voltage Energy Storage Pack instance on the bus side (not the battery side) of its contactors.This parameter is for one of multiple packs in an HVESS.  If there i...";
CM_ SG_ 2364646910 HVESP2IgnitionVoltage "HVESP2 Ignition Voltage: The voltage level at the ignition input of this High Voltage Energy Storage Pack controller.This parameter is for one of multiple packs in an HVESS.  If there is only one pack in the system, the HVESS parameters should be use...";
CM_ SG_ 2364646910 HVESP2IntakeCoolantTemperature "HVESP2 Intake Coolant Temperature: The temperature of liquid coolant as it enters this High Voltage Energy Storage Pack instance.This parameter is for one of multiple packs in an HVESS.  If there is only one pack in the system, the HVESS parameters s...";
CM_ SG_ 2364646910 HVESP2OutletCoolantTemperature "HVESP2 Outlet Coolant Temperature: The temperature of liquid coolant as it exits this High Voltage Energy Storage Pack instance.This parameter is for one of multiple packs in an HVESS.  If there is only one pack in the system, the HVESS parameters sh...";
CM_ SG_ 2364646910 HVESP2ElectronicsTemperature "HVESP2 Electronics Temperature: The temperature of the electronics or control modules in this High Voltage Energy Storage Pack instance.  If there are multiple temperature sensors then this parameter would be set to the maximum sensor reading.This pa...";
CM_ SG_ 2364646910 HVESP2Temperature "HVESP2 Temperature: The temperature of this High Voltage Energy Storage Pack instance. The value may be determined from a unique sensor specifically for this purpose, or by aggregating various temperature sensor readings within the pack.This paramete...";
CM_ BO_ 2364647166 "High Voltage Energy Storage Pack 2 Status 1";
CM_ SG_ 2364647166 HVESP2HghVltgBsPstvCnttrStt "HVESP2 High-Voltage Bus (Positive) Contactor State: Position of this High Voltage Energy Storage Pack instance positive side bus contactor.  When this contactor is closed, the positive side of this HVES instance is connected to the positive side of t...";
CM_ SG_ 2364647166 HVESP2HghVltgBsNgtvCnttrStt "HVESP2 High-Voltage Bus (Negative) Contactor State: Position of this High Voltage Energy Storage Pack instance negative side bus contactor.  When this contactor is closed, the negative side of this HVES instance is connected to the negative side of t...";
CM_ SG_ 2364647166 HVESP2HghVltgBsDsnntFrwrnng "HVESP2 High-Voltage Bus Disconnect Forewarning: Indicates that this High Voltage Energy Storage Pack instance is about to disconnect from the high voltage bus due to unacceptable conditions.This parameter is for one of multiple packs in an HVESS. If ...";
CM_ SG_ 2364647166 HVESP2HghVltgBsPrChrgRlStt "HVESP2 High-Voltage Bus Pre-Charge Relay State: Position of the high-voltage bus contactor pre-charge relay.  When this relay is closed, this High Voltage Energy Storage Pack instance is bringing the high-voltage bus up to its operating level.This pa...";
CM_ SG_ 2364647166 HVESP2CntrfPkCnttrStt "HVESP2 Center of Pack Contactor State: Position of the center high-voltage contactor.  When this contactor is closed, the positive half of this High Voltage Energy Storage Pack instance is connected to the negative half.  If a system controls the pos...";
CM_ SG_ 2364647166 HVESP2HghVltgBsAtvIsltnTstStts "HVESP2 High-Voltage Bus Active Isolation Test Status: Status of the high-voltage bus electrical active isolation test as performed by this High Voltage Energy Storage Pack instance.This parameter is for one of multiple packs in an HVESS. If there is ...";
CM_ SG_ 2364647166 HVESP2HghVltgBsPssvIsltnTstStts "HVESP2 High-Voltage Bus Passive Isolation Test Status: Status of the high-voltage bus electrical passive isolation test as performed by this High Voltage Energy Storage Pack instance.This parameter is for one of multiple packs in an HVESS. If there i...";
CM_ SG_ 2364647166 HVESP2HVILStatus "HVESP2 HVIL Status: Status of the High Voltage Interlock Loop from the viewpoint of this High Voltage Energy Storage Pack instance.This parameter is for one of multiple packs in an HVESS. If there is only one pack in the system, the HVESS parameters ...";
CM_ SG_ 2364647166 HVESP2InertiaSwitchStatus "HVESP2 Inertia Switch Status: Switch indicating that an impact has been sensed by this High Voltage Energy Storage Pack instance. The impact indication may require action by another controller, or by this HVES instance itself.  For example, a control...";
CM_ SG_ 2364647166 HVESP2StateofChargeStatus "HVESP2 State of Charge Status: Status of this High Voltage Energy Storage Pack instance State of Charge (SOC).  Note:  A given HVES controller may not support all of the states.This parameter is for one of multiple packs in an HVESS.  If there is onl...";
CM_ SG_ 2364647166 HVESP2CellBalanceStatus "HVESP2 Cell Balance Status: Indicates whether or not the cells in this High Voltage Energy Storage Pack instance are balanced.This parameter is for one of multiple packs in an HVESS.  If there is only one pack in the system, the HVESS parameters shou...";
CM_ SG_ 2364647166 HVESP2CellBalancingActive "HVESP2 Cell Balancing Active: Indicates whether or not the cells in this High Voltage Energy Storage Pack instance are currently being balanced.This parameter is for one of multiple packs in an HVESS.  If there is only one pack in the system, the HVE...";
CM_ SG_ 2364647166 HVESP2InternalChargerStatus "HVESP2 Internal Charger Status: Indicates that the charger in this HVES instance is on.  External chargers may use the External Energy Source Connection Status (SPN 7898) and related SPs.This parameter is for one of multiple packs in an HVESS. If the...";
CM_ SG_ 2364647166 HVESP2HghVltgBsCnntnStts "HVESP2 High-Voltage Bus Connection Status: This parameter provides high level feedback on this High Voltage Energy Storage Pack instance high voltage bus connection.  For specific contactor information, see SPN 11191 (HVESP2 High-Voltage Bus (Positiv...";
CM_ SG_ 2364647166 HVESP2OperationalStatus "HVESP2 Operational Status: Provides feedback on where this High Voltage Energy Storage Pack instance is in its operating spectrum, and includes feedback in response to the Operation Consent [i.e. SPN 11151 (HVESP2 Operation Consent)] and Power Down C...";
CM_ BO_ 2364647422 "High Voltage Energy Storage Pack 2 Data 7";
CM_ SG_ 2364647422 HVESP2DischargeEnergyCapacity "HVESP2 Discharge Energy Capacity: The amount of stored electrical energy in this High Voltage Energy Storage Pack instance that is available for use by the hybrid system, i.e. “how full is the tank”.  See SPN 11178 (HVESP2 Discharge Capacity) for Amp...";
CM_ SG_ 2364647422 HVESP2ChargeEnergyCapacity "HVESP2 Charge Energy Capacity: The amount of unused electrical energy storage available to be filled by charging this High Voltage Energy Storage Pack instance, i.e. “how much empty space is remaining in the tank”.  See SPN 11179 (HVESP2 Charge Capac...";
CM_ SG_ 2364647422 HVESP2MaximumChargeVoltageLimit "HVESP2 Maximum Charge Voltage Limit: The maximum voltage level not to be exceeded while charging this High Voltage Energy Storage Pack instance.  If this parameter is not supported, the maximum charge voltage should be limited to SPN 11250 (HVESP2 Re...";
CM_ BO_ 2364647678 "High Voltage Energy Storage Pack 2 Module Status 1";
CM_ SG_ 2364647678 HVESP2Module1OperationalStatus "HVESP2 Module 1 Operational Status: Operational Status of Module 1 in this High Voltage Energy Storage Pack Instance.  Not Operational is used when the module is initializing or not able to function (e.g. internal module level monitors have failed). ...";
CM_ SG_ 2364647678 HVESP2Module2OperationalStatus "HVESP2 Module 2 Operational Status: Operational Status of Module 2 in this High Voltage Energy Storage Pack Instance.  Not Operational is used when the module is initializing or not able to function (e.g. internal module level monitors have failed). ...";
CM_ SG_ 2364647678 HVESP2Module3OperationalStatus "HVESP2 Module 3 Operational Status: Operational Status of Module 3 in this High Voltage Energy Storage Pack Instance.  Not Operational is used when the module is initializing or not able to function (e.g. internal module level monitors have failed). ...";
CM_ SG_ 2364647678 HVESP2Module4OperationalStatus "HVESP2 Module 4 Operational Status: Operational Status of Module 4 in this High Voltage Energy Storage Pack Instance.  Not Operational is used when the module is initializing or not able to function (e.g. internal module level monitors have failed). ...";
CM_ SG_ 2364647678 HVESP2Module5OperationalStatus "HVESP2 Module 5 Operational Status: Operational Status of Module 5 in this High Voltage Energy Storage Pack Instance.  Not Operational is used when the module is initializing or not able to function (e.g. internal module level monitors have failed). ...";
CM_ SG_ 2364647678 HVESP2Module6OperationalStatus "HVESP2 Module 6 Operational Status: Operational Status of Module 6 in this High Voltage Energy Storage Pack Instance.  Not Operational is used when the module is initializing or not able to function (e.g. internal module level monitors have failed). ...";
CM_ SG_ 2364647678 HVESP2Module7OperationalStatus "HVESP2 Module 7 Operational Status: Operational Status of Module 7 in this High Voltage Energy Storage Pack Instance.  Not Operational is used when the module is initializing or not able to function (e.g. internal module level monitors have failed). ...";
CM_ SG_ 2364647678 HVESP2Module8OperationalStatus "HVESP2 Module 8 Operational Status: Operational Status of Module 8 in this High Voltage Energy Storage Pack Instance.  Not Operational is used when the module is initializing or not able to function (e.g. internal module level monitors have failed). ...";
CM_ SG_ 2364647678 HVESP2Module9OperationalStatus "HVESP2 Module 9 Operational Status: Operational Status of Module 9 in this High Voltage Energy Storage Pack Instance.  Not Operational is used when the module is initializing or not able to function (e.g. internal module level monitors have failed). ...";
CM_ SG_ 2364647678 HVESP2Module10OperationalStatus "HVESP2 Module 10 Operational Status: Operational Status of Module 10 in this High Voltage Energy Storage Pack Instance.  Not Operational is used when the module is initializing or not able to function (e.g. internal module level monitors have failed)...";
CM_ SG_ 2364647678 HVESP2Module11OperationalStatus "HVESP2 Module 11 Operational Status: Operational Status of Module 11 in this High Voltage Energy Storage Pack Instance.  Not Operational is used when the module is initializing or not able to function (e.g. internal module level monitors have failed)...";
CM_ SG_ 2364647678 HVESP2Module12OperationalStatus "HVESP2 Module 12 Operational Status: Operational Status of Module 12 in this High Voltage Energy Storage Pack Instance.  Not Operational is used when the module is initializing or not able to function (e.g. internal module level monitors have failed)...";
CM_ SG_ 2364647678 HVESP2Module13OperationalStatus "HVESP2 Module 13 Operational Status: Operational Status of Module 13 in this High Voltage Energy Storage Pack Instance.  Not Operational is used when the module is initializing or not able to function (e.g. internal module level monitors have failed)...";
CM_ SG_ 2364647678 HVESP2Module14OperationalStatus "HVESP2 Module 14 Operational Status: Operational Status of Module 14 in this High Voltage Energy Storage Pack Instance.  Not Operational is used when the module is initializing or not able to function (e.g. internal module level monitors have failed)...";
CM_ SG_ 2364647678 HVESP2Module15OperationalStatus "HVESP2 Module 15 Operational Status: Operational Status of Module 15 in this High Voltage Energy Storage Pack Instance.  Not Operational is used when the module is initializing or not able to function (e.g. internal module level monitors have failed)...";
CM_ SG_ 2364647678 HVESP2Module16OperationalStatus "HVESP2 Module 16 Operational Status: Operational Status of Module 16 in this High Voltage Energy Storage Pack Instance.  Not Operational is used when the module is initializing or not able to function (e.g. internal module level monitors have failed)...";
CM_ BO_ 2364647934 "High Voltage Energy Storage Pack 2 Thermal Management System Status 1";
CM_ SG_ 2364647934 HVESP2ThrmlMngmntSstmSLIInptPwr "HVESP2 Thermal Management System SLI Input Power: This is the low-voltage power consumed by this HVES Thermal Management System (TMS).This parameter is for one of multiple packs in an HVESS.  If there is only one pack in the system, the HVESS paramet...";
CM_ SG_ 2364647934 HVESP2TMtSstHVtIptPw "HVESP2 Thermal Management System High-Voltage Input Power: This is the high-voltage power consumed by this HVES Thermal Management System (TMS).This parameter is for one of multiple packs in an HVESS.  If there is only one pack in the system, the HVE...";
CM_ SG_ 2364647934 HVESP2ThrmlMngmntSstmCmprssrSpd "HVESP2 Thermal Management System Compressor Speed: When this High Voltage Energy Storage Pack Thermal Management System is equipped with an active cooling system (e.g. air conditioner), this is the Compressor Speed.This parameter is for one of multip...";
CM_ SG_ 2364647934 HVESP2ThrmlMngmntSstmRltvHmdt "HVESP2 Thermal Management System Relative Humidty: When this High Voltage Energy Storage Pack Thermal Management System is equipped with a relative humidity sensor, this is the  measured Relative Humidity.This parameter is for one of multiple packs i...";
CM_ SG_ 2364647934 HVESP2ThrmlMngmntSstmHtrStts "HVESP2 Thermal Management System Heater Status: The state of this High Voltage Energy Storage Pack heaterThis parameter is for one of multiple packs in an HVESS.  If there is only one pack in the system, the HVESS parameters should be used. If there ...";
CM_ SG_ 2364647934 HVESP2ThrmlMngmntSstmHVILStts "HVESP2 Thermal Management System HVIL Status: In multiple HVES configurations, this is the status of the High Voltage Interlock Loop from the viewpoint of this Thermal Management System.00b = HVIL Closed01b = HVIL Open10b = Error11b = Not AvailableTh...";
CM_ SG_ 2364647934 HVESP2ThrmlMngmntSstmMd "HVESP2 Thermal Management System Mode: Indicates the operating mode of the Thermal Management System.  The heat transfer medium may be (e.g. liquid or air).  The cooling system may be fans, liquid coolant, or a combination of mediums.  The system may...";
CM_ SG_ 2364647934 HVESP2ThrmlMngmntSstmClntLvl "HVESP2 Thermal Management System Coolant Level: Indicates the coolant level in this HVES Thermal Management System (TMS).This parameter is for one of multiple packs in an HVESS.  If there is only one pack in the system, the HVESS parameters should be...";
CM_ BO_ 2364648190 "High Voltage Energy Storage Pack 2 Data 8";
CM_ SG_ 2364648190 HVESP2HghstCllVltgMdlNmr "HVESP2 Highest Cell Voltage Module Number: Identifies the location of the module containing SPN 11171 (HVESP2 Highest Cell Voltage).This parameter is for one of multiple packs in an HVESS.  If there is only one pack in the system, the HVESS parameter...";
CM_ SG_ 2364648190 HVESP2HghstCllVltgCllNmr "HVESP2 Highest Cell Voltage Cell Number: Identifies the location of SPN 11171 (HVESP2 Highest Cell Voltage) within SPN 11231 (HVESP2 Highest Cell Voltage Module Number).This parameter is for one of multiple packs in an HVESS.  If there is only one pa...";
CM_ SG_ 2364648190 HVESP2LwstCllVltgMdlNmr "HVESP2 Lowest Cell Voltage Module Number: Identifies the location of the module containing SPN 11172 (HVESP2 Lowest Cell Voltage).This parameter is for one of multiple packs in an HVESS.  If there is only one pack in the system, the HVESS parameters ...";
CM_ SG_ 2364648190 HVESP2LwstCllVltgCllNmr "HVESP2 Lowest Cell Voltage Cell Number: Identifies the location of SPN 11172 (HVESP2 Lowest Cell Voltage) within SPN 11233 (HVESP2 Lowest Cell Voltage Module Number).This parameter is for one of multiple packs in an HVESS.  If there is only one pack ...";
CM_ SG_ 2364648190 HVESP2AverageCellVoltage "HVESP2 Average Cell Voltage: The average cell voltage in this High Voltage Energy Storage Pack instance.This parameter is for one of multiple packs in an HVESS.  If there is only one pack in the system, the HVESS parameters should be used. If there a...";
CM_ BO_ 2364648446 "High Voltage Energy Storage Pack 2 Data 9";
CM_ SG_ 2364648446 HVESP2HghstCllTmprtrMdlNmr "HVESP2 Highest Cell Temperature Module Number: Identifies the location of the module containing SPN 11174 (HVESP2 Highest Cell Temperature).This parameter is for one of multiple packs in an HVESS.  If there is only one pack in the system, the HVESS p...";
CM_ SG_ 2364648446 HVESP2HghstCllTmprtrCllNmr "HVESP2 Highest Cell Temperature Cell Number: Identifies the location of SPN 11174 (HVESP2 Highest Cell Temperature) within SPN 11236 (HVESP2 Highest Cell Temperature Module Number).This parameter is for one of multiple packs in an HVESS.  If there is...";
CM_ SG_ 2364648446 HVESP2LwstCllTmprtrMdlNmr "HVESP2 Lowest Cell Temperature Module Number: Identifies the location of the module containing SPN 11175 (HVESP2 Lowest Cell Temperature).This parameter is for one of multiple packs in an HVESS.  If there is only one pack in the system, the HVESS par...";
CM_ SG_ 2364648446 HVESP2LwstCllTmprtrCllNmr "HVESP2 Lowest Cell Temperature Cell Number: Identifies the location of SPN 11175 (HVESP2 Lowest Cell Temperature) within SPN 11238 (HVESP2 Lowest Cell Temperature Module Number).This parameter is for one of multiple packs in an HVESS.  If there is on...";
CM_ BO_ 2364648702 "High Voltage Energy Storage Pack 2 Data 10";
CM_ SG_ 2364648702 HVESP2HghstCllSttfChrgMdlNmr "HVESP2 Highest Cell State of Charge Module Number: Identifies the location of the module containing SPN 11184 (HVESP2 Highest Cell State of Charge).This parameter is for one of multiple packs in an HVESS.  If there is only one pack in the system, the...";
CM_ SG_ 2364648702 HVESP2HghstCllSttfChrgCllNmr "HVESP2 Highest Cell State of Charge Cell Number: Identifies the location of SPN 11184 (HVESP2 Highest Cell State of Charge) within SPN 11240 (HVESP2 Highest Cell State of Charge Module Number).This parameter is for one of multiple packs in an HVESS. ...";
CM_ SG_ 2364648702 HVESP2LwstCllSttfChrgMdlNmr "HVESP2 Lowest Cell State of Charge Module Number: Identifies the location of the module containing SPN 11183 (HVESP2 Lowest Cell State of Charge).This parameter is for one of multiple packs in an HVESS.  If there is only one pack in the system, the H...";
CM_ SG_ 2364648702 HVESP2LwstCllSttfChrgCllNmr "HVESP2 Lowest Cell State of Charge Cell Number: Identifies the location of SPN 11183 (HVESP2 Lowest Cell State of Charge) within SPN 11242 (HVESP2 Lowest Cell State of Charge Module Number).This parameter is for one of multiple packs in an HVESS.  If...";
CM_ SG_ 2364648702 HVESP2HghVltgBsAtvIsltnTstRslts "HVESP2 High-Voltage Bus Active Isolation Test Results: The isolation resistance expressed in Ohms per Volt that resulted from the High-Voltage Bus Active Isolation Test.See SPN 11196 (HVESP2 High-Voltage Bus Active Isolation Test Status) for test sta...";
CM_ SG_ 2364648702 HVESP2HVtBsPssvIstTstRsts "HVESP2 High-Voltage Bus Passive Isolation Test Results: The isolation resistance expressed in Ohms per Volt that resulted from the High-Voltage Bus Passive Isolation Test.See SPN 11197 (HVESP2 High-Voltage Bus Passive Isolation Test Status) for test ...";
CM_ BO_ 2364648958 "High Voltage Energy Storage Pack 2 Data 11";
CM_ SG_ 2364648958 HVESP2BsVltgNgtvtChsssGrndVltg "HVESP2 Bus Voltage Negative to Chassis Ground Voltage: Voltage difference between the most negative terminal of the HVES battery and chassis measured on the hybrid system bus side (not the battery side) of any HVES contained output contactor.  This v...";
CM_ SG_ 2364648958 HVESP2VltgLvlNgtvtChsssGrndVltg "HVESP2 Voltage Level Negative to Chassis Ground Voltage: Voltage difference between the most negative terminal of the HVES battery and chassis measured at the battery side of any HVES contained output contactor.  This voltage may be used for system l...";
CM_ BO_ 2364649214 "High Voltage Energy Storage Pack 3 Status 2";
CM_ SG_ 2364649214 HVESP3DshrgPwrLmtDtSttfChrg "HVESP3 Discharge Power Limit Due to State of Charge: Indicates whether or not discharge power of this HVES instance is being limited due to state of charge.This parameter is for one of multiple packs in an HVESS.  If there is only one pack in the sys...";
CM_ SG_ 2364649214 HVESP3DshrgPwrLmtDtBttrTmprtr "HVESP3 Discharge Power Limit Due to Battery Temperature: Indicates whether or not discharge power of this HVES instance is being limited due to battery temperature.This parameter is for one of multiple packs in an HVESS.  If there is only one pack in...";
CM_ SG_ 2364649214 HVESP3DsPwLtDtBttDstCdt "HVESP3 Discharge Power Limit Due to Battery Diagnostic Condition: Indicates whether or not discharge power of this HVES instance is being limited due to a battery diagnostic condition.This parameter is for one of multiple packs in an HVESS.  If there...";
CM_ SG_ 2364649214 HVESP3DshrgPwrLmtDtBttrrCllVltg "HVESP3 Discharge Power Limit Due to Battery or Cell Voltage: Indicates whether or not discharge power of this HVES instance is being limited due to a battery or cell voltage level.This parameter is for one of multiple packs in an HVESS.  If there is ...";
CM_ SG_ 2364649214 HVESP3DshrgPwrLmtDtBttrCrrnt "HVESP3 Discharge Power Limit Due to Battery Current: Indicates whether or not discharge power of this HVES instance is being limited due to battery current.This parameter is for one of multiple packs in an HVESS.  If there is only one pack in the sys...";
CM_ SG_ 2364649214 HVESP3DshrgPwrLmtDtnUndfndCs "HVESP3 Discharge Power Limit Due to an Undefined Cause: Indicates whether or not discharge power of this HVES instance is being limited due to an undefined cause.This parameter is for one of multiple packs in an HVESS.  If there is only one pack in t...";
CM_ SG_ 2364649214 HVESP3ChrgPwrLmtDtSttfChrg "HVESP3 Charge Power Limit Due to State of Charge: Indicates whether or not charge power of this HVES instance is being limited due to state of charge.This parameter is for one of multiple packs in an HVESS.  If there is only one pack in the system, t...";
CM_ SG_ 2364649214 HVESP3ChrgPwrLmtDtBttrTmprtr "HVESP3 Charge Power Limit Due to Battery Temperature: Indicates whether or not charge power of this HVES instance is being limited due to battery temperature.This parameter is for one of multiple packs in an HVESS.  If there is only one pack in the s...";
CM_ SG_ 2364649214 HVESP3CPwLtDtBttDstCdt "HVESP3 Charge Power Limit Due to Battery Diagnostic Condition: Indicates whether or not charge power of this HVES instance is being limited due to a battery diagnostic condition.This parameter is for one of multiple packs in an HVESS.  If there is on...";
CM_ SG_ 2364649214 HVESP3ChrgPwrLmtDtBttrrCllVltg "HVESP3 Charge Power Limit Due to Battery or Cell Voltage: Indicates whether or not charge power of this HVES instance is being limited due to a battery or cell voltage level.This parameter is for one of multiple packs in an HVESS.  If there is only o...";
CM_ SG_ 2364649214 HVESP3ChrgPwrLmtDtBttrCrrnt "HVESP3 Charge Power Limit Due to Battery Current: Indicates whether or not charge power of this HVES instance is being limited due to battery current.This parameter is for one of multiple packs in an HVESS.  If there is only one pack in the system, t...";
CM_ SG_ 2364649214 HVESP3ChrgPwrLmtDtnUndfndCs "HVESP3 Charge Power Limit Due to an Undefined Cause: Indicates whether or not charge power of this HVES instance is being limited due to an undefined cause.This parameter is for one of multiple packs in an HVESS.  If there is only one pack in the sys...";
CM_ BO_ 2364649470 "High Voltage Energy Storage Pack 3 Data 1";
CM_ SG_ 2364649470 HVESP3AvailableDischargePower "HVESP3 Available Discharge Power: The rate at which this High Voltage Energy Storage Pack instance can currently provide energy for propulsion or other uses.This parameter is for one of multiple packs in an HVESS.  If there is only one pack in the sy...";
CM_ SG_ 2364649470 HVESP3AvailableChargePower "HVESP3 Available Charge Power: The rate at which this High Voltage Energy Storage Pack instance can currently receive energy from a regenerative or recharging system.This parameter is for one of multiple packs in an HVESS.  If there is only one pack ...";
CM_ SG_ 2364649470 HVESP3VoltageLevel "HVESP3 Voltage Level: The voltage level of this High Voltage Energy Storage Pack instance. This parameter should be synchronized with SPN 11285 (HVESP3 Current) such that a realized power value can be calculated.  If the HVES component physically con...";
CM_ SG_ 2364649470 HVESP3Current "HVESP3 Current: The current in or out of this High Voltage Energy Storage Pack instance. This parameter should be synchronized with SPN 11284 (HVESP3 Voltage Level) such that a realized power value can be calculated.  This parameter is defined from t...";
CM_ BO_ 2364649726 "High Voltage Energy Storage Pack 3 Data 2";
CM_ SG_ 2364649726 HVESP3FastUpdateStateofCharge "HVESP3 Fast Update State of Charge: Indicates this High Voltage Energy Storage Pack instance state of charge.  0% means no charge remaining, 100% means the system is fully charged in terms of physical limits of this energy storage pack instance.  Acc...";
CM_ SG_ 2364649726 HVESP3HighestCellVoltage "HVESP3 Highest Cell Voltage: The highest voltage level reported by any cell in this High Voltage Energy Storage Pack instance. If a single voltage sensor covers more than one cell, the value in this parameter is for the smallest group of cells measur...";
CM_ SG_ 2364649726 HVESP3LowestCellVoltage "HVESP3 Lowest Cell Voltage: The lowest voltage level reported by any cell in this High Voltage Energy Storage Pack instance. If a single voltage sensor covers more than one cell, the value in this parameter is for the smallest group of cells measured...";
CM_ SG_ 2364649726 HVESP3CllVltgDffrntlStts "HVESP3 Cell Voltage Differential Status: Indicates whether or not the differential between the highest and lowest cell voltages are within acceptable limits, according to this High Voltage Energy Storage Pack instance. The actual voltage differential...";
CM_ BO_ 2364649982 "High Voltage Energy Storage Pack 3 Data 3";
CM_ SG_ 2364649982 HVESP3HighestCellTemperature "HVESP3 Highest Cell Temperature: The highest temperature level reported by any cell in this High Voltage Energy Storage Pack instance.  If a single temperature sensor covers more than one cell, the value in this parameter is for the smallest group of...";
CM_ SG_ 2364649982 HVESP3LowestCellTemperature "HVESP3 Lowest Cell Temperature: The lowest temperature level reported by any cell in this High Voltage Energy Storage Pack instance.  If a single temperature sensor covers more than one cell, the value in this parameter is for the smallest group of c...";
CM_ SG_ 2364649982 HVESP3AverageCellTemperature "HVESP3 Average Cell Temperature: The average temperature level of all cells in this High Voltage Energy Storage Pack instance.This parameter is for one of multiple packs in an HVESS.  If there is only one pack in the system, the HVESS parameters shou...";
CM_ SG_ 2364649982 HVESP3CllTmprtrDffrntlStts "HVESP3 Cell Temperature Differential Status: Indicates whether or not the differential between the highest and lowest cell temperatures are within acceptable limits per this High Voltage Energy Storage Pack instance.  The actual temperature different...";
CM_ BO_ 2364650238 "High Voltage Energy Storage Pack 3 Data 4";
CM_ SG_ 2364650238 HVESP3DischargeCapacity "HVESP3 Discharge Capacity: The amount of stored electrical charge in this High Voltage Energy Storage Pack instance that is available for use by the hybrid system, i.e. “how full is the tank”.  See SPN 11322 (HVESP3 Discharge Energy Capacity) for kil...";
CM_ SG_ 2364650238 HVESP3ChargeCapacity "HVESP3 Charge Capacity: The amount of unused electrical charge storage in this High Voltage Energy Storage Pack instance that is available to be filled by charging, i.e. “how much empty space is remaining in the tank”.  See SPN 11323 (HVESP3 Charge E...";
CM_ SG_ 2364650238 HVESP3CellBalancingCount "HVESP3 Cell Balancing Count: The number of cells that are currently being balanced in this High Voltage Energy Storage Pack instance.This parameter is for one of multiple packs in an HVESS.  If there is only one pack in the system, the HVESS paramete...";
CM_ BO_ 2364650494 "High Voltage Energy Storage Pack 3 Data 5";
CM_ SG_ 2364650494 HVESP3DischargeCurrentLimit "HVESP3 Discharge Current Limit: The maximum permissible current flow out of this High Voltage Energy Storage Pack instance. This parameter is defined from the high voltage energy storage pack's point of view.A negative value represents current flowin...";
CM_ SG_ 2364650494 HVESP3ChargeCurrentLimit "HVESP3 Charge Current Limit: The maximum permissible current flow into this High Voltage Energy Storage Pack instance. This parameter is defined from the high voltage energy storage pack's point of view.A positive value represents current flowing int...";
CM_ SG_ 2364650494 HVESP3LowestCellStateofCharge "HVESP3 Lowest Cell State of Charge: Indicates the state of charge of the lowest-charged cell in this High Voltage Energy Storage Pack instance.  0% means no charge remaining, 100% means the cell is fully charged.   If a single state of charge value c...";
CM_ SG_ 2364650494 HVESP3HighestCellStateofCharge "HVESP3 Highest Cell State of Charge: Indicates the state of charge of the highest-charged cell in this High Voltage Energy Storage Pack instance.  0% means no charge remaining, 100% means the cell is fully charged.  If a single state of charge value ...";
CM_ BO_ 2364650750 "High Voltage Energy Storage Pack 3 Data 6";
CM_ SG_ 2364650750 HVESP3BusVoltage "HVESP3 Bus Voltage: The voltage level of the high voltage bus, as measured by this High Voltage Energy Storage Pack instance on the bus side (not the battery side) of its contactors.This parameter is for one of multiple packs in an HVESS.  If there i...";
CM_ SG_ 2364650750 HVESP3IgnitionVoltage "HVESP3 Ignition Voltage: The voltage level at the ignition input of this High Voltage Energy Storage Pack controller.This parameter is for one of multiple packs in an HVESS.  If there is only one pack in the system, the HVESS parameters should be use...";
CM_ SG_ 2364650750 HVESP3IntakeCoolantTemperature "HVESP3 Intake Coolant Temperature: The temperature of liquid coolant as it enters this High Voltage Energy Storage Pack instance.This parameter is for one of multiple packs in an HVESS.  If there is only one pack in the system, the HVESS parameters s...";
CM_ SG_ 2364650750 HVESP3OutletCoolantTemperature "HVESP3 Outlet Coolant Temperature: The temperature of liquid coolant as it exits this High Voltage Energy Storage Pack instance.This parameter is for one of multiple packs in an HVESS.  If there is only one pack in the system, the HVESS parameters sh...";
CM_ SG_ 2364650750 HVESP3ElectronicsTemperature "HVESP3 Electronics Temperature: The temperature of the electronics or control modules in this High Voltage Energy Storage Pack instance.  If there are multiple temperature sensors then this parameter would be set to the maximum sensor reading.This pa...";
CM_ SG_ 2364650750 HVESP3Temperature "HVESP3 Temperature: The temperature of this High Voltage Energy Storage Pack instance. The value may be determined from a unique sensor specifically for this purpose, or by aggregating various temperature sensor readings within the pack.This paramete...";
CM_ BO_ 2364651006 "High Voltage Energy Storage Pack 3 Status 1";
CM_ SG_ 2364651006 HVESP3HghVltgBsPstvCnttrStt "HVESP3 High-Voltage Bus (Positive) Contactor State: Position of this High Voltage Energy Storage Pack instance positive side bus contactor.  When this contactor is closed, the positive side of this HVES instance is connected to the positive side of t...";
CM_ SG_ 2364651006 HVESP3HghVltgBsNgtvCnttrStt "HVESP3 High-Voltage Bus (Negative) Contactor State: Position of this High Voltage Energy Storage Pack instance negative side bus contactor.  When this contactor is closed, the negative side of this HVES instance is connected to the negative side of t...";
CM_ SG_ 2364651006 HVESP3HghVltgBsDsnntFrwrnng "HVESP3 High-Voltage Bus Disconnect Forewarning: Indicates that this High Voltage Energy Storage Pack instance is about to disconnect from the high voltage bus due to unacceptable conditions.This parameter is for one of multiple packs in an HVESS. If ...";
CM_ SG_ 2364651006 HVESP3HghVltgBsPrChrgRlStt "HVESP3 High-Voltage Bus Pre-Charge Relay State: Position of the high-voltage bus contactor pre-charge relay.  When this relay is closed, this High Voltage Energy Storage Pack instance is bringing the high-voltage bus up to its operating level.This pa...";
CM_ SG_ 2364651006 HVESP3CntrfPkCnttrStt "HVESP3 Center of Pack Contactor State: Position of the center high-voltage contactor.  When this contactor is closed, the positive half of this High Voltage Energy Storage Pack instance is connected to the negative half.  If a system controls the pos...";
CM_ SG_ 2364651006 HVESP3HghVltgBsAtvIsltnTstStts "HVESP3 High-Voltage Bus Active Isolation Test Status: Status of the high-voltage bus electrical active isolation test as performed by this High Voltage Energy Storage Pack instance.This parameter is for one of multiple packs in an HVESS. If there is ...";
CM_ SG_ 2364651006 HVESP3HghVltgBsPssvIsltnTstStts "HVESP3 High-Voltage Bus Passive Isolation Test Status: Status of the high-voltage bus electrical passive isolation test as performed by this High Voltage Energy Storage Pack instance.This parameter is for one of multiple packs in an HVESS. If there i...";
CM_ SG_ 2364651006 HVESP3HVILStatus "HVESP3 HVIL Status: Status of the High Voltage Interlock Loop from the viewpoint of this High Voltage Energy Storage Pack instance.This parameter is for one of multiple packs in an HVESS. If there is only one pack in the system, the HVESS parameters ...";
CM_ SG_ 2364651006 HVESP3InertiaSwitchStatus "HVESP3 Inertia Switch Status: Switch indicating that an impact has been sensed by this High Voltage Energy Storage Pack instance. The impact indication may require action by another controller, or by this HVES instance itself.  For example, a control...";
CM_ SG_ 2364651006 HVESP3StateofChargeStatus "HVESP3 State of Charge Status: Status of this High Voltage Energy Storage Pack instance State of Charge (SOC).  Note:  A given HVES controller may not support all of the states.This parameter is for one of multiple packs in an HVESS.  If there is onl...";
CM_ SG_ 2364651006 HVESP3CellBalanceStatus "HVESP3 Cell Balance Status: Indicates whether or not the cells in this High Voltage Energy Storage Pack instance are balanced.This parameter is for one of multiple packs in an HVESS.  If there is only one pack in the system, the HVESS parameters shou...";
CM_ SG_ 2364651006 HVESP3CellBalancingActive "HVESP3 Cell Balancing Active: Indicates whether or not the cells in this High Voltage Energy Storage Pack instance are currently being balanced.This parameter is for one of multiple packs in an HVESS.  If there is only one pack in the system, the HVE...";
CM_ SG_ 2364651006 HVESP3InternalChargerStatus "HVESP3 Internal Charger Status: Indicates that the charger in this HVES instance is on.  External chargers may use the External Energy Source Connection Status (SPN 7898) and related SPs.This parameter is for one of multiple packs in an HVESS. If the...";
CM_ SG_ 2364651006 HVESP3HghVltgBsCnntnStts "HVESP3 High-Voltage Bus Connection Status: This parameter provides high level feedback on this High Voltage Energy Storage Pack instance high voltage bus connection.  For specific contactor information, see SPN 11307 (HVESP3 High-Voltage Bus (Positiv...";
CM_ SG_ 2364651006 HVESP3OperationalStatus "HVESP3 Operational Status: Provides feedback on where this High Voltage Energy Storage Pack instance is in its operating spectrum, and includes feedback in response to the Operation Consent [i.e. SPN 11267 (HVESP3 Operation Consent)] and Power Down C...";
CM_ BO_ 2364651262 "High Voltage Energy Storage Pack 3 Data 7";
CM_ SG_ 2364651262 HVESP3DischargeEnergyCapacity "HVESP3 Discharge Energy Capacity: The amount of stored electrical energy in this High Voltage Energy Storage Pack instance that is available for use by the hybrid system, i.e. “how full is the tank”.  See SPN 11294 (HVESP3 Discharge Capacity) for Amp...";
CM_ SG_ 2364651262 HVESP3ChargeEnergyCapacity "HVESP3 Charge Energy Capacity: The amount of unused electrical energy storage available to be filled by charging this High Voltage Energy Storage Pack instance, i.e. “how much empty space is remaining in the tank”.  See SPN 11295 (HVESP3 Charge Capac...";
CM_ SG_ 2364651262 HVESP3MaximumChargeVoltageLimit "HVESP3 Maximum Charge Voltage Limit: The maximum voltage level not to be exceeded while charging this High Voltage Energy Storage Pack instance.  If this parameter is not supported, the maximum charge voltage should be limited to SPN 11366 (HVESP3 Re...";
CM_ BO_ 2364651518 "High Voltage Energy Storage Pack 3 Module Status 1";
CM_ SG_ 2364651518 HVESP3Module1OperationalStatus "HVESP3 Module 1 Operational Status: Operational Status of Module 1 in this High Voltage Energy Storage Pack Instance.  Not Operational is used when the module is initializing or not able to function (e.g. internal module level monitors have failed). ...";
CM_ SG_ 2364651518 HVESP3Module2OperationalStatus "HVESP3 Module 2 Operational Status: Operational Status of Module 2 in this High Voltage Energy Storage Pack Instance.  Not Operational is used when the module is initializing or not able to function (e.g. internal module level monitors have failed). ...";
CM_ SG_ 2364651518 HVESP3Module3OperationalStatus "HVESP3 Module 3 Operational Status: Operational Status of Module 3 in this High Voltage Energy Storage Pack Instance.  Not Operational is used when the module is initializing or not able to function (e.g. internal module level monitors have failed). ...";
CM_ SG_ 2364651518 HVESP3Module4OperationalStatus "HVESP3 Module 4 Operational Status: Operational Status of Module 4 in this High Voltage Energy Storage Pack Instance.  Not Operational is used when the module is initializing or not able to function (e.g. internal module level monitors have failed). ...";
CM_ SG_ 2364651518 HVESP3Module5OperationalStatus "HVESP3 Module 5 Operational Status: Operational Status of Module 5 in this High Voltage Energy Storage Pack Instance.  Not Operational is used when the module is initializing or not able to function (e.g. internal module level monitors have failed). ...";
CM_ SG_ 2364651518 HVESP3Module6OperationalStatus "HVESP3 Module 6 Operational Status: Operational Status of Module 6 in this High Voltage Energy Storage Pack Instance.  Not Operational is used when the module is initializing or not able to function (e.g. internal module level monitors have failed). ...";
CM_ SG_ 2364651518 HVESP3Module7OperationalStatus "HVESP3 Module 7 Operational Status: Operational Status of Module 7 in this High Voltage Energy Storage Pack Instance.  Not Operational is used when the module is initializing or not able to function (e.g. internal module level monitors have failed). ...";
CM_ SG_ 2364651518 HVESP3Module8OperationalStatus "HVESP3 Module 8 Operational Status: Operational Status of Module 8 in this High Voltage Energy Storage Pack Instance.  Not Operational is used when the module is initializing or not able to function (e.g. internal module level monitors have failed). ...";
CM_ SG_ 2364651518 HVESP3Module9OperationalStatus "HVESP3 Module 9 Operational Status: Operational Status of Module 9 in this High Voltage Energy Storage Pack Instance.  Not Operational is used when the module is initializing or not able to function (e.g. internal module level monitors have failed). ...";
CM_ SG_ 2364651518 HVESP3Module10OperationalStatus "HVESP3 Module 10 Operational Status: Operational Status of Module 10 in this High Voltage Energy Storage Pack Instance.  Not Operational is used when the module is initializing or not able to function (e.g. internal module level monitors have failed)...";
CM_ SG_ 2364651518 HVESP3Module11OperationalStatus "HVESP3 Module 11 Operational Status: Operational Status of Module 11 in this High Voltage Energy Storage Pack Instance.  Not Operational is used when the module is initializing or not able to function (e.g. internal module level monitors have failed)...";
CM_ SG_ 2364651518 HVESP3Module12OperationalStatus "HVESP3 Module 12 Operational Status: Operational Status of Module 12 in this High Voltage Energy Storage Pack Instance.  Not Operational is used when the module is initializing or not able to function (e.g. internal module level monitors have failed)...";
CM_ SG_ 2364651518 HVESP3Module13OperationalStatus "HVESP3 Module 13 Operational Status: Operational Status of Module 13 in this High Voltage Energy Storage Pack Instance.  Not Operational is used when the module is initializing or not able to function (e.g. internal module level monitors have failed)...";
CM_ SG_ 2364651518 HVESP3Module14OperationalStatus "HVESP3 Module 14 Operational Status: Operational Status of Module 14 in this High Voltage Energy Storage Pack Instance.  Not Operational is used when the module is initializing or not able to function (e.g. internal module level monitors have failed)...";
CM_ SG_ 2364651518 HVESP3Module15OperationalStatus "HVESP3 Module 15 Operational Status: Operational Status of Module 15 in this High Voltage Energy Storage Pack Instance.  Not Operational is used when the module is initializing or not able to function (e.g. internal module level monitors have failed)...";
CM_ SG_ 2364651518 HVESP3Module16OperationalStatus "HVESP3 Module 16 Operational Status: Operational Status of Module 16 in this High Voltage Energy Storage Pack Instance.  Not Operational is used when the module is initializing or not able to function (e.g. internal module level monitors have failed)...";
CM_ BO_ 2364651774 "High Voltage Energy Storage Pack 3 Thermal Management System Status 1";
CM_ SG_ 2364651774 HVESP3ThrmlMngmntSstmSLIInptPwr "HVESP3 Thermal Management System SLI Input Power: This is the low-voltage power consumed by this HVES Thermal Management System (TMS).This parameter is for one of multiple packs in an HVESS.  If there is only one pack in the system, the HVESS paramet...";
CM_ SG_ 2364651774 HVESP3TMtSstHVtIptPw "HVESP3 Thermal Management System High-Voltage Input Power: This is the high-voltage power consumed by this HVES Thermal Management System (TMS).This parameter is for one of multiple packs in an HVESS.  If there is only one pack in the system, the HVE...";
CM_ SG_ 2364651774 HVESP3ThrmlMngmntSstmCmprssrSpd "HVESP3 Thermal Management System Compressor Speed: When this High Voltage Energy Storage Pack Thermal Management System is equipped with an active cooling system (e.g. air conditioner), this is the Compressor Speed.This parameter is for one of multip...";
CM_ SG_ 2364651774 HVESP3ThrmlMngmntSstmRltvHmdt "HVESP3 Thermal Management System Relative Humidty: When this High Voltage Energy Storage Pack Thermal Management System is equipped with a relative humidity sensor, this is the  measured Relative Humidity.This parameter is for one of multiple packs i...";
CM_ SG_ 2364651774 HVESP3ThrmlMngmntSstmHtrStts "HVESP3 Thermal Management System Heater Status: The state of this High Voltage Energy Storage Pack heaterThis parameter is for one of multiple packs in an HVESS.  If there is only one pack in the system, the HVESS parameters should be used. If there ...";
CM_ SG_ 2364651774 HVESP3ThrmlMngmntSstmHVILStts "HVESP3 Thermal Management System HVIL Status: In multiple HVES configurations, this is the status of the High Voltage Interlock Loop from the viewpoint of this Thermal Management System.00b = HVIL Closed01b = HVIL Open10b = Error11b = Not AvailableTh...";
CM_ SG_ 2364651774 HVESP3ThrmlMngmntSstmMd "HVESP3 Thermal Management System Mode: Indicates the operating mode of the Thermal Management System.  The heat transfer medium may be (e.g. liquid or air).  The cooling system may be fans, liquid coolant, or a combination of mediums.  The system may...";
CM_ SG_ 2364651774 HVESP3ThrmlMngmntSstmClntLvl "HVESP3 Thermal Management System Coolant Level: Indicates the coolant level in this HVES Thermal Management System (TMS).This parameter is for one of multiple packs in an HVESS.  If there is only one pack in the system, the HVESS parameters should be...";
CM_ BO_ 2364652030 "High Voltage Energy Storage Pack 3 Data 8";
CM_ SG_ 2364652030 HVESP3HghstCllVltgMdlNmr "HVESP3 Highest Cell Voltage Module Number: Identifies the location of the module containing SPN 11287 (HVESP3 Highest Cell Voltage).This parameter is for one of multiple packs in an HVESS.  If there is only one pack in the system, the HVESS parameter...";
CM_ SG_ 2364652030 HVESP3HghstCllVltgCllNmr "HVESP3 Highest Cell Voltage Cell Number: Identifies the location of SPN 11287 (HVESP3 Highest Cell Voltage) within SPN 11347 (HVESP3 Highest Cell Voltage Module Number).This parameter is for one of multiple packs in an HVESS.  If there is only one pa...";
CM_ SG_ 2364652030 HVESP3LwstCllVltgMdlNmr "HVESP3 Lowest Cell Voltage Module Number: Identifies the location of the module containing SPN 11288 (HVESP3 Lowest Cell Voltage).This parameter is for one of multiple packs in an HVESS.  If there is only one pack in the system, the HVESS parameters ...";
CM_ SG_ 2364652030 HVESP3LwstCllVltgCllNmr "HVESP3 Lowest Cell Voltage Cell Number: Identifies the location of SPN 11288 (HVESP3 Lowest Cell Voltage) within SPN 11349 (HVESP3 Lowest Cell Voltage Module Number).This parameter is for one of multiple packs in an HVESS.  If there is only one pack ...";
CM_ SG_ 2364652030 HVESP3AverageCellVoltage "HVESP3 Average Cell Voltage: The average cell voltage in this High Voltage Energy Storage Pack instance.This parameter is for one of multiple packs in an HVESS.  If there is only one pack in the system, the HVESS parameters should be used. If there a...";
CM_ BO_ 2364652286 "High Voltage Energy Storage Pack 3 Data 9";
CM_ SG_ 2364652286 HVESP3HghstCllTmprtrMdlNmr "HVESP3 Highest Cell Temperature Module Number: Identifies the location of the module containing SPN 11290 (HVESP3 Highest Cell Temperature).This parameter is for one of multiple packs in an HVESS.  If there is only one pack in the system, the HVESS p...";
CM_ SG_ 2364652286 HVESP3HghstCllTmprtrCllNmr "HVESP3 Highest Cell Temperature Cell Number: Identifies the location of SPN 11290 (HVESP3 Highest Cell Temperature) within SPN 11352 (HVESP3 Highest Cell Temperature Module Number).This parameter is for one of multiple packs in an HVESS.  If there is...";
CM_ SG_ 2364652286 HVESP3LwstCllTmprtrMdlNmr "HVESP3 Lowest Cell Temperature Module Number: Identifies the location of the module containing SPN 11291 (HVESP3 Lowest Cell Temperature).This parameter is for one of multiple packs in an HVESS.  If there is only one pack in the system, the HVESS par...";
CM_ SG_ 2364652286 HVESP3LwstCllTmprtrCllNmr "HVESP3 Lowest Cell Temperature Cell Number: Identifies the location of SPN 11291 (HVESP3 Lowest Cell Temperature) within SPN 11354 (HVESP3 Lowest Cell Temperature Module Number).This parameter is for one of multiple packs in an HVESS.  If there is on...";
CM_ BO_ 2364652542 "High Voltage Energy Storage Pack 3 Data 10";
CM_ SG_ 2364652542 HVESP3HghstCllSttfChrgMdlNmr "HVESP3 Highest Cell State of Charge Module Number: Identifies the location of the module containing SPN 11300 (HVESP3 Highest Cell State of Charge).This parameter is for one of multiple packs in an HVESS.  If there is only one pack in the system, the...";
CM_ SG_ 2364652542 HVESP3HghstCllSttfChrgCllNmr "HVESP3 Highest Cell State of Charge Cell Number: Identifies the location of SPN 11300 (HVESP3 Highest Cell State of Charge) within SPN 11356 (HVESP3 Highest Cell State of Charge Module Number).This parameter is for one of multiple packs in an HVESS. ...";
CM_ SG_ 2364652542 HVESP3LwstCllSttfChrgMdlNmr "HVESP3 Lowest Cell State of Charge Module Number: Identifies the location of the module containing SPN 11299 (HVESP3 Lowest Cell State of Charge).This parameter is for one of multiple packs in an HVESS.  If there is only one pack in the system, the H...";
CM_ SG_ 2364652542 HVESP3LwstCllSttfChrgCllNmr "HVESP3 Lowest Cell State of Charge Cell Number: Identifies the location of SPN 11299 (HVESP3 Lowest Cell State of Charge) within SPN 11358 (HVESP3 Lowest Cell State of Charge Module Number).This parameter is for one of multiple packs in an HVESS.  If...";
CM_ SG_ 2364652542 HVESP3HghVltgBsAtvIsltnTstRslts "HVESP3 High-Voltage Bus Active Isolation Test Results: The isolation resistance expressed in Ohms per Volt that resulted from the High-Voltage Bus Active Isolation Test.See SPN 11312 (HVESP3 High-Voltage Bus Active Isolation Test Status) for test sta...";
CM_ SG_ 2364652542 HVESP3HVtBsPssvIstTstRsts "HVESP3 High-Voltage Bus Passive Isolation Test Results: The isolation resistance expressed in Ohms per Volt that resulted from the High-Voltage Bus Passive Isolation Test.See SPN 11313 (HVESP3 High-Voltage Bus Passive Isolation Test Status) for test ...";
CM_ BO_ 2364652798 "High Voltage Energy Storage Pack 3 Data 11";
CM_ SG_ 2364652798 HVESP3BsVltgNgtvtChsssGrndVltg "HVESP3 Bus Voltage Negative to Chassis Ground Voltage: Voltage difference between the most negative terminal of the HVES battery and chassis measured on the hybrid system bus side (not the battery side) of any HVES contained output contactor.  This v...";
CM_ SG_ 2364652798 HVESP3VltgLvlNgtvtChsssGrndVltg "HVESP3 Voltage Level Negative to Chassis Ground Voltage: Voltage difference between the most negative terminal of the HVES battery and chassis measured at the battery side of any HVES contained output contactor.  This voltage may be used for system l...";
CM_ BO_ 2364653054 "High Voltage Energy Storage Pack 4 Status 2";
CM_ SG_ 2364653054 HVESP4DshrgPwrLmtDtSttfChrg "HVESP4 Discharge Power Limit Due to State of Charge: Indicates whether or not discharge power of this HVES instance is being limited due to state of charge.This parameter is for one of multiple packs in an HVESS.  If there is only one pack in the sys...";
CM_ SG_ 2364653054 HVESP4DshrgPwrLmtDtBttrTmprtr "HVESP4 Discharge Power Limit Due to Battery Temperature: Indicates whether or not discharge power of this HVES instance is being limited due to battery temperature.This parameter is for one of multiple packs in an HVESS.  If there is only one pack in...";
CM_ SG_ 2364653054 HVESP4DsPwLtDtBttDstCdt "HVESP4 Discharge Power Limit Due to Battery Diagnostic Condition: Indicates whether or not discharge power of this HVES instance is being limited due to a battery diagnostic condition.This parameter is for one of multiple packs in an HVESS.  If there...";
CM_ SG_ 2364653054 HVESP4DshrgPwrLmtDtBttrrCllVltg "HVESP4 Discharge Power Limit Due to Battery or Cell Voltage: Indicates whether or not discharge power of this HVES instance is being limited due to a battery or cell voltage level.This parameter is for one of multiple packs in an HVESS.  If there is ...";
CM_ SG_ 2364653054 HVESP4DshrgPwrLmtDtBttrCrrnt "HVESP4 Discharge Power Limit Due to Battery Current: Indicates whether or not discharge power of this HVES instance is being limited due to battery current.This parameter is for one of multiple packs in an HVESS.  If there is only one pack in the sys...";
CM_ SG_ 2364653054 HVESP4DshrgPwrLmtDtnUndfndCs "HVESP4 Discharge Power Limit Due to an Undefined Cause: Indicates whether or not discharge power of this HVES instance is being limited due to an undefined cause.This parameter is for one of multiple packs in an HVESS.  If there is only one pack in t...";
CM_ SG_ 2364653054 HVESP4ChrgPwrLmtDtSttfChrg "HVESP4 Charge Power Limit Due to State of Charge: Indicates whether or not charge power of this HVES instance is being limited due to state of charge.This parameter is for one of multiple packs in an HVESS.  If there is only one pack in the system, t...";
CM_ SG_ 2364653054 HVESP4ChrgPwrLmtDtBttrTmprtr "HVESP4 Charge Power Limit Due to Battery Temperature: Indicates whether or not charge power of this HVES instance is being limited due to battery temperature.This parameter is for one of multiple packs in an HVESS.  If there is only one pack in the s...";
CM_ SG_ 2364653054 HVESP4CPwLtDtBttDstCdt "HVESP4 Charge Power Limit Due to Battery Diagnostic Condition: Indicates whether or not charge power of this HVES instance is being limited due to a battery diagnostic condition.This parameter is for one of multiple packs in an HVESS.  If there is on...";
CM_ SG_ 2364653054 HVESP4ChrgPwrLmtDtBttrrCllVltg "HVESP4 Charge Power Limit Due to Battery or Cell Voltage: Indicates whether or not charge power of this HVES instance is being limited due to a battery or cell voltage level.This parameter is for one of multiple packs in an HVESS.  If there is only o...";
CM_ SG_ 2364653054 HVESP4ChrgPwrLmtDtBttrCrrnt "HVESP4 Charge Power Limit Due to Battery Current: Indicates whether or not charge power of this HVES instance is being limited due to battery current.This parameter is for one of multiple packs in an HVESS.  If there is only one pack in the system, t...";
CM_ SG_ 2364653054 HVESP4ChrgPwrLmtDtnUndfndCs "HVESP4 Charge Power Limit Due to an Undefined Cause: Indicates whether or not charge power of this HVES instance is being limited due to an undefined cause.This parameter is for one of multiple packs in an HVESS.  If there is only one pack in the sys...";
CM_ BO_ 2364653310 "High Voltage Energy Storage Pack 4 Data 1";
CM_ SG_ 2364653310 HVESP4AvailableDischargePower "HVESP4 Available Discharge Power: The rate at which this High Voltage Energy Storage Pack instance can currently provide energy for propulsion or other uses.This parameter is for one of multiple packs in an HVESS.  If there is only one pack in the sy...";
CM_ SG_ 2364653310 HVESP4AvailableChargePower "HVESP4 Available Charge Power: The rate at which this High Voltage Energy Storage Pack instance can currently receive energy from a regenerative or recharging system.This parameter is for one of multiple packs in an HVESS.  If there is only one pack ...";
CM_ SG_ 2364653310 HVESP4VoltageLevel "HVESP4 Voltage Level: The voltage level of this High Voltage Energy Storage Pack instance. This parameter should be synchronized with SPN 11401 (HVESP4 Current) such that a realized power value can be calculated.  If the HVES component physically con...";
CM_ SG_ 2364653310 HVESP4Current "HVESP4 Current: The current in or out of this High Voltage Energy Storage Pack instance. This parameter should be synchronized with SPN 11400 (HVESP4 Voltage Level) such that a realized power value can be calculated.  This parameter is defined from t...";
CM_ BO_ 2364653566 "High Voltage Energy Storage Pack 4 Data 2";
CM_ SG_ 2364653566 HVESP4FastUpdateStateofCharge "HVESP4 Fast Update State of Charge: Indicates this High Voltage Energy Storage Pack instance state of charge.  0% means no charge remaining, 100% means the system is fully charged in terms of physical limits of this energy storage pack instance.  Acc...";
CM_ SG_ 2364653566 HVESP4HighestCellVoltage "HVESP4 Highest Cell Voltage: The highest voltage level reported by any cell in this High Voltage Energy Storage Pack instance. If a single voltage sensor covers more than one cell, the value in this parameter is for the smallest group of cells measur...";
CM_ SG_ 2364653566 HVESP4LowestCellVoltage "HVESP4 Lowest Cell Voltage: The lowest voltage level reported by any cell in this High Voltage Energy Storage Pack instance. If a single voltage sensor covers more than one cell, the value in this parameter is for the smallest group of cells measured...";
CM_ SG_ 2364653566 HVESP4CllVltgDffrntlStts "HVESP4 Cell Voltage Differential Status: Indicates whether or not the differential between the highest and lowest cell voltages are within acceptable limits, according to this High Voltage Energy Storage Pack instance. The actual voltage differential...";
CM_ BO_ 2364653822 "High Voltage Energy Storage Pack 4 Data 3";
CM_ SG_ 2364653822 HVESP4HighestCellTemperature "HVESP4 Highest Cell Temperature: The highest temperature level reported by any cell in this High Voltage Energy Storage Pack instance.  If a single temperature sensor covers more than one cell, the value in this parameter is for the smallest group of...";
CM_ SG_ 2364653822 HVESP4LowestCellTemperature "HVESP4 Lowest Cell Temperature: The lowest temperature level reported by any cell in this High Voltage Energy Storage Pack instance.  If a single temperature sensor covers more than one cell, the value in this parameter is for the smallest group of c...";
CM_ SG_ 2364653822 HVESP4AverageCellTemperature "HVESP4 Average Cell Temperature: The average temperature level of all cells in this High Voltage Energy Storage Pack instance.This parameter is for one of multiple packs in an HVESS.  If there is only one pack in the system, the HVESS parameters shou...";
CM_ SG_ 2364653822 HVESP4CllTmprtrDffrntlStts "HVESP4 Cell Temperature Differential Status: Indicates whether or not the differential between the highest and lowest cell temperatures are within acceptable limits per this High Voltage Energy Storage Pack instance.  The actual temperature different...";
CM_ BO_ 2364654078 "High Voltage Energy Storage Pack 4 Data 4";
CM_ SG_ 2364654078 HVESP4DischargeCapacity "HVESP4 Discharge Capacity: The amount of stored electrical charge in this High Voltage Energy Storage Pack instance that is available for use by the hybrid system, i.e. “how full is the tank”.  See SPN 11438 (HVESP4 Discharge Energy Capacity) for kil...";
CM_ SG_ 2364654078 HVESP4ChargeCapacity "HVESP4 Charge Capacity: The amount of unused electrical charge storage in this High Voltage Energy Storage Pack instance that is available to be filled by charging, i.e. “how much empty space is remaining in the tank”.  See SPN 11439 (HVESP4 Charge E...";
CM_ SG_ 2364654078 HVESP4CellBalancingCount "HVESP4 Cell Balancing Count: The number of cells that are currently being balanced in this High Voltage Energy Storage Pack instance.This parameter is for one of multiple packs in an HVESS.  If there is only one pack in the system, the HVESS paramete...";
CM_ BO_ 2364654334 "High Voltage Energy Storage Pack 4 Data 5";
CM_ SG_ 2364654334 HVESP4DischargeCurrentLimit "HVESP4 Discharge Current Limit: The maximum permissible current flow out of this High Voltage Energy Storage Pack instance. This parameter is defined from the high voltage energy storage pack's point of view.A negative value represents current flowin...";
CM_ SG_ 2364654334 HVESP4ChargeCurrentLimit "HVESP4 Charge Current Limit: The maximum permissible current flow into this High Voltage Energy Storage Pack instance. This parameter is defined from the high voltage energy storage pack's point of view.A positive value represents current flowing int...";
CM_ SG_ 2364654334 HVESP4LowestCellStateofCharge "HVESP4 Lowest Cell State of Charge: Indicates the state of charge of the lowest-charged cell in this High Voltage Energy Storage Pack instance.  0% means no charge remaining, 100% means the cell is fully charged.   If a single state of charge value c...";
CM_ SG_ 2364654334 HVESP4HighestCellStateofCharge "HVESP4 Highest Cell State of Charge: Indicates the state of charge of the highest-charged cell in this High Voltage Energy Storage Pack instance.  0% means no charge remaining, 100% means the cell is fully charged.  If a single state of charge value ...";
CM_ BO_ 2364654590 "High Voltage Energy Storage Pack 4 Data 6";
CM_ SG_ 2364654590 HVESP4BusVoltage "HVESP4 Bus Voltage: The voltage level of the high voltage bus, as measured by this High Voltage Energy Storage Pack instance on the bus side (not the battery side) of its contactors.This parameter is for one of multiple packs in an HVESS.  If there i...";
CM_ SG_ 2364654590 HVESP4IgnitionVoltage "HVESP4 Ignition Voltage: The voltage level at the ignition input of this High Voltage Energy Storage Pack controller.This parameter is for one of multiple packs in an HVESS.  If there is only one pack in the system, the HVESS parameters should be use...";
CM_ SG_ 2364654590 HVESP4IntakeCoolantTemperature "HVESP4 Intake Coolant Temperature: The temperature of liquid coolant as it enters this High Voltage Energy Storage Pack instance.This parameter is for one of multiple packs in an HVESS.  If there is only one pack in the system, the HVESS parameters s...";
CM_ SG_ 2364654590 HVESP4OutletCoolantTemperature "HVESP4 Outlet Coolant Temperature: The temperature of liquid coolant as it exits this High Voltage Energy Storage Pack instance.This parameter is for one of multiple packs in an HVESS.  If there is only one pack in the system, the HVESS parameters sh...";
CM_ SG_ 2364654590 HVESP4ElectronicsTemperature "HVESP4 Electronics Temperature: The temperature of the electronics or control modules in this High Voltage Energy Storage Pack instance.  If there are multiple temperature sensors then this parameter would be set to the maximum sensor reading.This pa...";
CM_ SG_ 2364654590 HVESP4Temperature "HVESP4 Temperature: The temperature of this High Voltage Energy Storage Pack instance. The value may be determined from a unique sensor specifically for this purpose, or by aggregating various temperature sensor readings within the pack.This paramete...";
CM_ BO_ 2364654846 "High Voltage Energy Storage Pack 4 Status 1";
CM_ SG_ 2364654846 HVESP4HghVltgBsPstvCnttrStt "HVESP4 High-Voltage Bus (Positive) Contactor State: Position of this High Voltage Energy Storage Pack instance positive side bus contactor.  When this contactor is closed, the positive side of this HVES instance is connected to the positive side of t...";
CM_ SG_ 2364654846 HVESP4HghVltgBsNgtvCnttrStt "HVESP4 High-Voltage Bus (Negative) Contactor State: Position of this High Voltage Energy Storage Pack instance negative side bus contactor.  When this contactor is closed, the negative side of this HVES instance is connected to the negative side of t...";
CM_ SG_ 2364654846 HVESP4HghVltgBsDsnntFrwrnng "HVESP4 High-Voltage Bus Disconnect Forewarning: Indicates that this High Voltage Energy Storage Pack instance is about to disconnect from the high voltage bus due to unacceptable conditions.This parameter is for one of multiple packs in an HVESS. If ...";
CM_ SG_ 2364654846 HVESP4HghVltgBsPrChrgRlStt "HVESP4 High-Voltage Bus Pre-Charge Relay State: Position of the high-voltage bus contactor pre-charge relay.  When this relay is closed, this High Voltage Energy Storage Pack instance is bringing the high-voltage bus up to its operating level.This pa...";
CM_ SG_ 2364654846 HVESP4CntrfPkCnttrStt "HVESP4 Center of Pack Contactor State: Position of the center high-voltage contactor.  When this contactor is closed, the positive half of this High Voltage Energy Storage Pack instance is connected to the negative half.  If a system controls the pos...";
CM_ SG_ 2364654846 HVESP4HghVltgBsAtvIsltnTstStts "HVESP4 High-Voltage Bus Active Isolation Test Status: Status of the high-voltage bus electrical active isolation test as performed by this High Voltage Energy Storage Pack instance.This parameter is for one of multiple packs in an HVESS. If there is ...";
CM_ SG_ 2364654846 HVESP4HghVltgBsPssvIsltnTstStts "HVESP4 High-Voltage Bus Passive Isolation Test Status: Status of the high-voltage bus electrical passive isolation test as performed by this High Voltage Energy Storage Pack instance.This parameter is for one of multiple packs in an HVESS. If there i...";
CM_ SG_ 2364654846 HVESP4HVILStatus "HVESP4 HVIL Status: Status of the High Voltage Interlock Loop from the viewpoint of this High Voltage Energy Storage Pack instance.This parameter is for one of multiple packs in an HVESS. If there is only one pack in the system, the HVESS parameters ...";
CM_ SG_ 2364654846 HVESP4InertiaSwitchStatus "HVESP4 Inertia Switch Status: Switch indicating that an impact has been sensed by this High Voltage Energy Storage Pack instance. The impact indication may require action by another controller, or by this HVES instance itself.  For example, a control...";
CM_ SG_ 2364654846 HVESP4StateofChargeStatus "HVESP4 State of Charge Status: Status of this High Voltage Energy Storage Pack instance State of Charge (SOC).  Note:  A given HVES controller may not support all of the states.This parameter is for one of multiple packs in an HVESS.  If there is onl...";
CM_ SG_ 2364654846 HVESP4CellBalanceStatus "HVESP4 Cell Balance Status: Indicates whether or not the cells in this High Voltage Energy Storage Pack instance are balanced.This parameter is for one of multiple packs in an HVESS.  If there is only one pack in the system, the HVESS parameters shou...";
CM_ SG_ 2364654846 HVESP4CellBalancingActive "HVESP4 Cell Balancing Active: Indicates whether or not the cells in this High Voltage Energy Storage Pack instance are currently being balanced.This parameter is for one of multiple packs in an HVESS.  If there is only one pack in the system, the HVE...";
CM_ SG_ 2364654846 HVESP4InternalChargerStatus "HVESP4 Internal Charger Status: Indicates that the charger in this HVES instance is on.  External chargers may use the External Energy Source Connection Status (SPN 7898) and related SPs.This parameter is for one of multiple packs in an HVESS. If the...";
CM_ SG_ 2364654846 HVESP4HghVltgBsCnntnStts "HVESP4 High-Voltage Bus Connection Status: This parameter provides high level feedback on this High Voltage Energy Storage Pack instance high voltage bus connection.  For specific contactor information, see SPN 11423 (HVESP4 High-Voltage Bus (Positiv...";
CM_ SG_ 2364654846 HVESP4OperationalStatus "HVESP4 Operational Status: Provides feedback on where this High Voltage Energy Storage Pack instance is in its operating spectrum, and includes feedback in response to the Operation Consent [i.e. SPN 11383 (HVESP4 Operation Consent)] and Power Down C...";
CM_ BO_ 2364655102 "High Voltage Energy Storage Pack 4 Data 7";
CM_ SG_ 2364655102 HVESP4DischargeEnergyCapacity "HVESP4 Discharge Energy Capacity: The amount of stored electrical energy in this High Voltage Energy Storage Pack instance that is available for use by the hybrid system, i.e. “how full is the tank”.  See SPN 11410 (HVESP4 Discharge Capacity) for Amp...";
CM_ SG_ 2364655102 HVESP4ChargeEnergyCapacity "HVESP4 Charge Energy Capacity: The amount of unused electrical energy storage available to be filled by charging this High Voltage Energy Storage Pack instance, i.e. “how much empty space is remaining in the tank”.  See SPN 11411 (HVESP4 Charge Capac...";
CM_ SG_ 2364655102 HVESP4MaximumChargeVoltageLimit "HVESP4 Maximum Charge Voltage Limit: The maximum voltage level not to be exceeded while charging this High Voltage Energy Storage Pack instance.  If this parameter is not supported, the maximum charge voltage should be limited to SPN 11482 (HVESP4 Re...";
CM_ BO_ 2364655358 "High Voltage Energy Storage Pack 4 Module Status 1";
CM_ SG_ 2364655358 HVESP4Module1OperationalStatus "HVESP4 Module 1 Operational Status: Operational Status of Module 1 in this High Voltage Energy Storage Pack Instance.  Not Operational is used when the module is initializing or not able to function (e.g. internal module level monitors have failed). ...";
CM_ SG_ 2364655358 HVESP4Module2OperationalStatus "HVESP4 Module 2 Operational Status: Operational Status of Module 2 in this High Voltage Energy Storage Pack Instance.  Not Operational is used when the module is initializing or not able to function (e.g. internal module level monitors have failed). ...";
CM_ SG_ 2364655358 HVESP4Module3OperationalStatus "HVESP4 Module 3 Operational Status: Operational Status of Module 3 in this High Voltage Energy Storage Pack Instance.  Not Operational is used when the module is initializing or not able to function (e.g. internal module level monitors have failed). ...";
CM_ SG_ 2364655358 HVESP4Module4OperationalStatus "HVESP4 Module 4 Operational Status: Operational Status of Module 4 in this High Voltage Energy Storage Pack Instance.  Not Operational is used when the module is initializing or not able to function (e.g. internal module level monitors have failed). ...";
CM_ SG_ 2364655358 HVESP4Module5OperationalStatus "HVESP4 Module 5 Operational Status: Operational Status of Module 5 in this High Voltage Energy Storage Pack Instance.  Not Operational is used when the module is initializing or not able to function (e.g. internal module level monitors have failed). ...";
CM_ SG_ 2364655358 HVESP4Module6OperationalStatus "HVESP4 Module 6 Operational Status: Operational Status of Module 6 in this High Voltage Energy Storage Pack Instance.  Not Operational is used when the module is initializing or not able to function (e.g. internal module level monitors have failed). ...";
CM_ SG_ 2364655358 HVESP4Module7OperationalStatus "HVESP4 Module 7 Operational Status: Operational Status of Module 7 in this High Voltage Energy Storage Pack Instance.  Not Operational is used when the module is initializing or not able to function (e.g. internal module level monitors have failed). ...";
CM_ SG_ 2364655358 HVESP4Module8OperationalStatus "HVESP4 Module 8 Operational Status: Operational Status of Module 8 in this High Voltage Energy Storage Pack Instance.  Not Operational is used when the module is initializing or not able to function (e.g. internal module level monitors have failed). ...";
CM_ SG_ 2364655358 HVESP4Module9OperationalStatus "HVESP4 Module 9 Operational Status: Operational Status of Module 9 in this High Voltage Energy Storage Pack Instance.  Not Operational is used when the module is initializing or not able to function (e.g. internal module level monitors have failed). ...";
CM_ SG_ 2364655358 HVESP4Module10OperationalStatus "HVESP4 Module 10 Operational Status: Operational Status of Module 10 in this High Voltage Energy Storage Pack Instance.  Not Operational is used when the module is initializing or not able to function (e.g. internal module level monitors have failed)...";
CM_ SG_ 2364655358 HVESP4Module11OperationalStatus "HVESP4 Module 11 Operational Status: Operational Status of Module 11 in this High Voltage Energy Storage Pack Instance.  Not Operational is used when the module is initializing or not able to function (e.g. internal module level monitors have failed)...";
CM_ SG_ 2364655358 HVESP4Module12OperationalStatus "HVESP4 Module 12 Operational Status: Operational Status of Module 12 in this High Voltage Energy Storage Pack Instance.  Not Operational is used when the module is initializing or not able to function (e.g. internal module level monitors have failed)...";
CM_ SG_ 2364655358 HVESP4Module13OperationalStatus "HVESP4 Module 13 Operational Status: Operational Status of Module 13 in this High Voltage Energy Storage Pack Instance.  Not Operational is used when the module is initializing or not able to function (e.g. internal module level monitors have failed)...";
CM_ SG_ 2364655358 HVESP4Module14OperationalStatus "HVESP4 Module 14 Operational Status: Operational Status of Module 14 in this High Voltage Energy Storage Pack Instance.  Not Operational is used when the module is initializing or not able to function (e.g. internal module level monitors have failed)...";
CM_ SG_ 2364655358 HVESP4Module15OperationalStatus "HVESP4 Module 15 Operational Status: Operational Status of Module 15 in this High Voltage Energy Storage Pack Instance.  Not Operational is used when the module is initializing or not able to function (e.g. internal module level monitors have failed)...";
CM_ SG_ 2364655358 HVESP4Module16OperationalStatus "HVESP4 Module 16 Operational Status: Operational Status of Module 16 in this High Voltage Energy Storage Pack Instance.  Not Operational is used when the module is initializing or not able to function (e.g. internal module level monitors have failed)...";
CM_ BO_ 2364655614 "High Voltage Energy Storage Pack 4 Thermal Management System Status 1";
CM_ SG_ 2364655614 HVESP4ThrmlMngmntSstmSLIInptPwr "HVESP4 Thermal Management System SLI Input Power: This is the low-voltage power consumed by this HVES Thermal Management System (TMS).This parameter is for one of multiple packs in an HVESS.  If there is only one pack in the system, the HVESS paramet...";
CM_ SG_ 2364655614 HVESP4TMtSstHVtIptPw "HVESP4 Thermal Management System High-Voltage Input Power: This is the high-voltage power consumed by this HVES Thermal Management System (TMS).This parameter is for one of multiple packs in an HVESS.  If there is only one pack in the system, the HVE...";
CM_ SG_ 2364655614 HVESP4ThrmlMngmntSstmCmprssrSpd "HVESP4 Thermal Management System Compressor Speed: When this High Voltage Energy Storage Pack Thermal Management System is equipped with an active cooling system (e.g. air conditioner), this is the Compressor Speed.This parameter is for one of multip...";
CM_ SG_ 2364655614 HVESP4ThrmlMngmntSstmRltvHmdt "HVESP4 Thermal Management System Relative Humidty: When this High Voltage Energy Storage Pack Thermal Management System is equipped with a relative humidity sensor, this is the  measured Relative Humidity.This parameter is for one of multiple packs i...";
CM_ SG_ 2364655614 HVESP4ThrmlMngmntSstmHtrStts "HVESP4 Thermal Management System Heater Status: The state of this High Voltage Energy Storage Pack heaterThis parameter is for one of multiple packs in an HVESS.  If there is only one pack in the system, the HVESS parameters should be used. If there ...";
CM_ SG_ 2364655614 HVESP4ThrmlMngmntSstmHVILStts "HVESP4 Thermal Management System HVIL Status: In multiple HVES configurations, this is the status of the High Voltage Interlock Loop from the viewpoint of this Thermal Management System.00b = HVIL Closed01b = HVIL Open10b = Error11b = Not AvailableTh...";
CM_ SG_ 2364655614 HVESP4ThrmlMngmntSstmMd "HVESP4 Thermal Management System Mode: Indicates the operating mode of the Thermal Management System.  The heat transfer medium may be (e.g. liquid or air).  The cooling system may be fans, liquid coolant, or a combination of mediums.  The system may...";
CM_ SG_ 2364655614 HVESP4ThrmlMngmntSstmClntLvl "HVESP4 Thermal Management System Coolant Level: Indicates the coolant level in this HVES Thermal Management System (TMS).This parameter is for one of multiple packs in an HVESS.  If there is only one pack in the system, the HVESS parameters should be...";
CM_ BO_ 2364655870 "High Voltage Energy Storage Pack 4 Data 8";
CM_ SG_ 2364655870 HVESP4HghstCllVltgMdlNmr "HVESP4 Highest Cell Voltage Module Number: Identifies the location of the module containing SPN 11403 (HVESP4 Highest Cell Voltage).This parameter is for one of multiple packs in an HVESS.  If there is only one pack in the system, the HVESS parameter...";
CM_ SG_ 2364655870 HVESP4HghstCllVltgCllNmr "HVESP4 Highest Cell Voltage Cell Number: Identifies the location of SPN 11403 (HVESP4 Highest Cell Voltage) within SPN 11463 (HVESP4 Highest Cell Voltage Module Number).This parameter is for one of multiple packs in an HVESS.  If there is only one pa...";
CM_ SG_ 2364655870 HVESP4LwstCllVltgMdlNmr "HVESP4 Lowest Cell Voltage Module Number: Identifies the location of the module containing SPN 11404 (HVESP4 Lowest Cell Voltage).This parameter is for one of multiple packs in an HVESS.  If there is only one pack in the system, the HVESS parameters ...";
CM_ SG_ 2364655870 HVESP4LwstCllVltgCllNmr "HVESP4 Lowest Cell Voltage Cell Number: Identifies the location of SPN 11404 (HVESP4 Lowest Cell Voltage) within SPN 11465 (HVESP4 Lowest Cell Voltage Module Number).This parameter is for one of multiple packs in an HVESS.  If there is only one pack ...";
CM_ SG_ 2364655870 HVESP4AverageCellVoltage "HVESP4 Average Cell Voltage: The average cell voltage in this High Voltage Energy Storage Pack instance.This parameter is for one of multiple packs in an HVESS.  If there is only one pack in the system, the HVESS parameters should be used. If there a...";
CM_ BO_ 2364656126 "High Voltage Energy Storage Pack 4 Data 9";
CM_ SG_ 2364656126 HVESP4HghstCllTmprtrMdlNmr "HVESP4 Highest Cell Temperature Module Number: Identifies the location of the module containing SPN 11406 (HVESP4 Highest Cell Temperature).This parameter is for one of multiple packs in an HVESS.  If there is only one pack in the system, the HVESS p...";
CM_ SG_ 2364656126 HVESP4HghstCllTmprtrCllNmr "HVESP4 Highest Cell Temperature Cell Number: Identifies the location of SPN 11406 (HVESP4 Highest Cell Temperature) within SPN 11468 (HVESP4 Highest Cell Temperature Module Number).This parameter is for one of multiple packs in an HVESS.  If there is...";
CM_ SG_ 2364656126 HVESP4LwstCllTmprtrMdlNmr "HVESP4 Lowest Cell Temperature Module Number: Identifies the location of the module containing SPN 11407 (HVESP4 Lowest Cell Temperature).This parameter is for one of multiple packs in an HVESS.  If there is only one pack in the system, the HVESS par...";
CM_ SG_ 2364656126 HVESP4LwstCllTmprtrCllNmr "HVESP4 Lowest Cell Temperature Cell Number: Identifies the location of SPN 11407 (HVESP4 Lowest Cell Temperature) within SPN 11470 (HVESP4 Lowest Cell Temperature Module Number).This parameter is for one of multiple packs in an HVESS.  If there is on...";
CM_ BO_ 2364656382 "High Voltage Energy Storage Pack 4 Data 10";
CM_ SG_ 2364656382 HVESP4HghstCllSttfChrgMdlNmr "HVESP4 Highest Cell State of Charge Module Number: Identifies the location of the module containing SPN 11416 (HVESP4 Highest Cell State of Charge).This parameter is for one of multiple packs in an HVESS.  If there is only one pack in the system, the...";
CM_ SG_ 2364656382 HVESP4HghstCllSttfChrgCllNmr "HVESP4 Highest Cell State of Charge Cell Number: Identifies the location of SPN 11416 (HVESP4 Highest Cell State of Charge) within SPN 11472 (HVESP4 Highest Cell State of Charge Module Number).This parameter is for one of multiple packs in an HVESS. ...";
CM_ SG_ 2364656382 HVESP4LwstCllSttfChrgMdlNmr "HVESP4 Lowest Cell State of Charge Module Number: Identifies the location of the module containing SPN 11415 (HVESP4 Lowest Cell State of Charge).This parameter is for one of multiple packs in an HVESS.  If there is only one pack in the system, the H...";
CM_ SG_ 2364656382 HVESP4LwstCllSttfChrgCllNmr "HVESP4 Lowest Cell State of Charge Cell Number: Identifies the location of SPN 11415 (HVESP4 Lowest Cell State of Charge) within SPN 11474 (HVESP4 Lowest Cell State of Charge Module Number).This parameter is for one of multiple packs in an HVESS.  If...";
CM_ SG_ 2364656382 HVESP4HghVltgBsAtvIsltnTstRslts "HVESP4 High-Voltage Bus Active Isolation Test Results: The isolation resistance expressed in Ohms per Volt that resulted from the High-Voltage Bus Active Isolation Test.See SPN 11428 (HVESP4 High-Voltage Bus Active Isolation Test Status) for test sta...";
CM_ SG_ 2364656382 HVESP4HVtBsPssvIstTstRsts "HVESP4 High-Voltage Bus Passive Isolation Test Results: The isolation resistance expressed in Ohms per Volt that resulted from the High-Voltage Bus Passive Isolation Test.See SPN 11429 (HVESP4 High-Voltage Bus Passive Isolation Test Status) for test ...";
CM_ BO_ 2364656638 "High Voltage Energy Storage Pack 4 Data 11";
CM_ SG_ 2364656638 HVESP4BsVltgNgtvtChsssGrndVltg "HVESP4 Bus Voltage Negative to Chassis Ground Voltage: Voltage difference between the most negative terminal of the HVES battery and chassis measured on the hybrid system bus side (not the battery side) of any HVES contained output contactor.  This v...";
CM_ SG_ 2364656638 HVESP4VltgLvlNgtvtChsssGrndVltg "HVESP4 Voltage Level Negative to Chassis Ground Voltage: Voltage difference between the most negative terminal of the HVES battery and chassis measured at the battery side of any HVES contained output contactor.  This voltage may be used for system l...";
CM_ BO_ 2364656894 "High Voltage Energy Storage Pack 5 Status 2";
CM_ SG_ 2364656894 HVESP5DshrgPwrLmtDtSttfChrg "HVESP5 Discharge Power Limit Due to State of Charge: Indicates whether or not discharge power of this HVES instance is being limited due to state of charge.This parameter is for one of multiple packs in an HVESS.  If there is only one pack in the sys...";
CM_ SG_ 2364656894 HVESP5DshrgPwrLmtDtBttrTmprtr "HVESP5 Discharge Power Limit Due to Battery Temperature: Indicates whether or not discharge power of this HVES instance is being limited due to battery temperature.This parameter is for one of multiple packs in an HVESS.  If there is only one pack in...";
CM_ SG_ 2364656894 HVESP5DsPwLtDtBttDstCdt "HVESP5 Discharge Power Limit Due to Battery Diagnostic Condition: Indicates whether or not discharge power of this HVES instance is being limited due to a battery diagnostic condition.This parameter is for one of multiple packs in an HVESS.  If there...";
CM_ SG_ 2364656894 HVESP5DshrgPwrLmtDtBttrrCllVltg "HVESP5 Discharge Power Limit Due to Battery or Cell Voltage: Indicates whether or not discharge power of this HVES instance is being limited due to a battery or cell voltage level.This parameter is for one of multiple packs in an HVESS.  If there is ...";
CM_ SG_ 2364656894 HVESP5DshrgPwrLmtDtBttrCrrnt "HVESP5 Discharge Power Limit Due to Battery Current: Indicates whether or not discharge power of this HVES instance is being limited due to battery current.This parameter is for one of multiple packs in an HVESS.  If there is only one pack in the sys...";
CM_ SG_ 2364656894 HVESP5DshrgPwrLmtDtnUndfndCs "HVESP5 Discharge Power Limit Due to an Undefined Cause: Indicates whether or not discharge power of this HVES instance is being limited due to an undefined cause.This parameter is for one of multiple packs in an HVESS.  If there is only one pack in t...";
CM_ SG_ 2364656894 HVESP5ChrgPwrLmtDtSttfChrg "HVESP5 Charge Power Limit Due to State of Charge: Indicates whether or not charge power of this HVES instance is being limited due to state of charge.This parameter is for one of multiple packs in an HVESS.  If there is only one pack in the system, t...";
CM_ SG_ 2364656894 HVESP5ChrgPwrLmtDtBttrTmprtr "HVESP5 Charge Power Limit Due to Battery Temperature: Indicates whether or not charge power of this HVES instance is being limited due to battery temperature.This parameter is for one of multiple packs in an HVESS.  If there is only one pack in the s...";
CM_ SG_ 2364656894 HVESP5CPwLtDtBttDstCdt "HVESP5 Charge Power Limit Due to Battery Diagnostic Condition: Indicates whether or not charge power of this HVES instance is being limited due to a battery diagnostic condition.This parameter is for one of multiple packs in an HVESS.  If there is on...";
CM_ SG_ 2364656894 HVESP5ChrgPwrLmtDtBttrrCllVltg "HVESP5 Charge Power Limit Due to Battery or Cell Voltage: Indicates whether or not charge power of this HVES instance is being limited due to a battery or cell voltage level.This parameter is for one of multiple packs in an HVESS.  If there is only o...";
CM_ SG_ 2364656894 HVESP5ChrgPwrLmtDtBttrCrrnt "HVESP5 Charge Power Limit Due to Battery Current: Indicates whether or not charge power of this HVES instance is being limited due to battery current.This parameter is for one of multiple packs in an HVESS.  If there is only one pack in the system, t...";
CM_ SG_ 2364656894 HVESP5ChrgPwrLmtDtnUndfndCs "HVESP5 Charge Power Limit Due to an Undefined Cause: Indicates whether or not charge power of this HVES instance is being limited due to an undefined cause.This parameter is for one of multiple packs in an HVESS.  If there is only one pack in the sys...";
CM_ BO_ 2364657150 "High Voltage Energy Storage Pack 5 Data 1";
CM_ SG_ 2364657150 HVESP5AvailableDischargePower "HVESP5 Available Discharge Power: The rate at which this High Voltage Energy Storage Pack instance can currently provide energy for propulsion or other uses.This parameter is for one of multiple packs in an HVESS.  If there is only one pack in the sy...";
CM_ SG_ 2364657150 HVESP5AvailableChargePower "HVESP5 Available Charge Power: The rate at which this High Voltage Energy Storage Pack instance can currently receive energy from a regenerative or recharging system.This parameter is for one of multiple packs in an HVESS.  If there is only one pack ...";
CM_ SG_ 2364657150 HVESP5VoltageLevel "HVESP5 Voltage Level: The voltage level of this High Voltage Energy Storage Pack instance. This parameter should be synchronized with SPN 11517 (HVESP5 Current) such that a realized power value can be calculated.  If the HVES component physically con...";
CM_ SG_ 2364657150 HVESP5Current "HVESP5 Current: The current in or out of this High Voltage Energy Storage Pack instance. This parameter should be synchronized with SPN 11516 (HVESP5 Voltage Level) such that a realized power value can be calculated.  This parameter is defined from t...";
CM_ BO_ 2364657406 "High Voltage Energy Storage Pack 5 Data 2";
CM_ SG_ 2364657406 HVESP5FastUpdateStateofCharge "HVESP5 Fast Update State of Charge: Indicates this High Voltage Energy Storage Pack instance state of charge.  0% means no charge remaining, 100% means the system is fully charged in terms of physical limits of this energy storage pack instance.  Acc...";
CM_ SG_ 2364657406 HVESP5HighestCellVoltage "HVESP5 Highest Cell Voltage: The highest voltage level reported by any cell in this High Voltage Energy Storage Pack instance. If a single voltage sensor covers more than one cell, the value in this parameter is for the smallest group of cells measur...";
CM_ SG_ 2364657406 HVESP5LowestCellVoltage "HVESP5 Lowest Cell Voltage: The lowest voltage level reported by any cell in this High Voltage Energy Storage Pack instance. If a single voltage sensor covers more than one cell, the value in this parameter is for the smallest group of cells measured...";
CM_ SG_ 2364657406 HVESP5CllVltgDffrntlStts "HVESP5 Cell Voltage Differential Status: Indicates whether or not the differential between the highest and lowest cell voltages are within acceptable limits, according to this High Voltage Energy Storage Pack instance. The actual voltage differential...";
CM_ BO_ 2364657662 "High Voltage Energy Storage Pack 5 Data 3";
CM_ SG_ 2364657662 HVESP5HighestCellTemperature "HVESP5 Highest Cell Temperature: The highest temperature level reported by any cell in this High Voltage Energy Storage Pack instance.  If a single temperature sensor covers more than one cell, the value in this parameter is for the smallest group of...";
CM_ SG_ 2364657662 HVESP5LowestCellTemperature "HVESP5 Lowest Cell Temperature: The lowest temperature level reported by any cell in this High Voltage Energy Storage Pack instance.  If a single temperature sensor covers more than one cell, the value in this parameter is for the smallest group of c...";
CM_ SG_ 2364657662 HVESP5AverageCellTemperature "HVESP5 Average Cell Temperature: The average temperature level of all cells in this High Voltage Energy Storage Pack instance.This parameter is for one of multiple packs in an HVESS.  If there is only one pack in the system, the HVESS parameters shou...";
CM_ SG_ 2364657662 HVESP5CllTmprtrDffrntlStts "HVESP5 Cell Temperature Differential Status: Indicates whether or not the differential between the highest and lowest cell temperatures are within acceptable limits per this High Voltage Energy Storage Pack instance.  The actual temperature different...";
CM_ BO_ 2364657918 "High Voltage Energy Storage Pack 5 Data 4";
CM_ SG_ 2364657918 HVESP5DischargeCapacity "HVESP5 Discharge Capacity: The amount of stored electrical charge in this High Voltage Energy Storage Pack instance that is available for use by the hybrid system, i.e. “how full is the tank”.  See SPN 11554 (HVESP5 Discharge Energy Capacity) for kil...";
CM_ SG_ 2364657918 HVESP5ChargeCapacity "HVESP5 Charge Capacity: The amount of unused electrical charge storage in this High Voltage Energy Storage Pack instance that is available to be filled by charging, i.e. “how much empty space is remaining in the tank”.  See SPN 11555 (HVESP5 Charge E...";
CM_ SG_ 2364657918 HVESP5CellBalancingCount "HVESP5 Cell Balancing Count: The number of cells that are currently being balanced in this High Voltage Energy Storage Pack instance.This parameter is for one of multiple packs in an HVESS.  If there is only one pack in the system, the HVESS paramete...";
CM_ BO_ 2364658174 "High Voltage Energy Storage Pack 5 Data 5";
CM_ SG_ 2364658174 HVESP5DischargeCurrentLimit "HVESP5 Discharge Current Limit: The maximum permissible current flow out of this High Voltage Energy Storage Pack instance. This parameter is defined from the high voltage energy storage pack's point of view.A negative value represents current flowin...";
CM_ SG_ 2364658174 HVESP5ChargeCurrentLimit "HVESP5 Charge Current Limit: The maximum permissible current flow into this High Voltage Energy Storage Pack instance. This parameter is defined from the high voltage energy storage pack's point of view.A positive value represents current flowing int...";
CM_ SG_ 2364658174 HVESP5LowestCellStateofCharge "HVESP5 Lowest Cell State of Charge: Indicates the state of charge of the lowest-charged cell in this High Voltage Energy Storage Pack instance.  0% means no charge remaining, 100% means the cell is fully charged.   If a single state of charge value c...";
CM_ SG_ 2364658174 HVESP5HighestCellStateofCharge "HVESP5 Highest Cell State of Charge: Indicates the state of charge of the highest-charged cell in this High Voltage Energy Storage Pack instance.  0% means no charge remaining, 100% means the cell is fully charged.  If a single state of charge value ...";
CM_ BO_ 2364658430 "High Voltage Energy Storage Pack 5 Data 6";
CM_ SG_ 2364658430 HVESP5BusVoltage "HVESP5 Bus Voltage: The voltage level of the high voltage bus, as measured by this High Voltage Energy Storage Pack instance on the bus side (not the battery side) of its contactors.This parameter is for one of multiple packs in an HVESS.  If there i...";
CM_ SG_ 2364658430 HVESP5IgnitionVoltage "HVESP5 Ignition Voltage: The voltage level at the ignition input of this High Voltage Energy Storage Pack controller.This parameter is for one of multiple packs in an HVESS.  If there is only one pack in the system, the HVESS parameters should be use...";
CM_ SG_ 2364658430 HVESP5IntakeCoolantTemperature "HVESP5 Intake Coolant Temperature: The temperature of liquid coolant as it enters this High Voltage Energy Storage Pack instance.This parameter is for one of multiple packs in an HVESS.  If there is only one pack in the system, the HVESS parameters s...";
CM_ SG_ 2364658430 HVESP5OutletCoolantTemperature "HVESP5 Outlet Coolant Temperature: The temperature of liquid coolant as it exits this High Voltage Energy Storage Pack instance.This parameter is for one of multiple packs in an HVESS.  If there is only one pack in the system, the HVESS parameters sh...";
CM_ SG_ 2364658430 HVESP5ElectronicsTemperature "HVESP5 Electronics Temperature: The temperature of the electronics or control modules in this High Voltage Energy Storage Pack instance.  If there are multiple temperature sensors then this parameter would be set to the maximum sensor reading.This pa...";
CM_ SG_ 2364658430 HVESP5Temperature "HVESP5 Temperature: The temperature of this High Voltage Energy Storage Pack instance. The value may be determined from a unique sensor specifically for this purpose, or by aggregating various temperature sensor readings within the pack.This paramete...";
CM_ BO_ 2364658686 "High Voltage Energy Storage Pack 5 Status 1";
CM_ SG_ 2364658686 HVESP5HghVltgBsPstvCnttrStt "HVESP5 High-Voltage Bus (Positive) Contactor State: Position of this High Voltage Energy Storage Pack instance positive side bus contactor.  When this contactor is closed, the positive side of this HVES instance is connected to the positive side of t...";
CM_ SG_ 2364658686 HVESP5HghVltgBsNgtvCnttrStt "HVESP5 High-Voltage Bus (Negative) Contactor State: Position of this High Voltage Energy Storage Pack instance negative side bus contactor.  When this contactor is closed, the negative side of this HVES instance is connected to the negative side of t...";
CM_ SG_ 2364658686 HVESP5HghVltgBsDsnntFrwrnng "HVESP5 High-Voltage Bus Disconnect Forewarning: Indicates that this High Voltage Energy Storage Pack instance is about to disconnect from the high voltage bus due to unacceptable conditions.This parameter is for one of multiple packs in an HVESS. If ...";
CM_ SG_ 2364658686 HVESP5HghVltgBsPrChrgRlStt "HVESP5 High-Voltage Bus Pre-Charge Relay State: Position of the high-voltage bus contactor pre-charge relay.  When this relay is closed, this High Voltage Energy Storage Pack instance is bringing the high-voltage bus up to its operating level.This pa...";
CM_ SG_ 2364658686 HVESP5CntrfPkCnttrStt "HVESP5 Center of Pack Contactor State: Position of the center high-voltage contactor.  When this contactor is closed, the positive half of this High Voltage Energy Storage Pack instance is connected to the negative half.  If a system controls the pos...";
CM_ SG_ 2364658686 HVESP5HghVltgBsAtvIsltnTstStts "HVESP5 High-Voltage Bus Active Isolation Test Status: Status of the high-voltage bus electrical active isolation test as performed by this High Voltage Energy Storage Pack instance.This parameter is for one of multiple packs in an HVESS. If there is ...";
CM_ SG_ 2364658686 HVESP5HghVltgBsPssvIsltnTstStts "HVESP5 High-Voltage Bus Passive Isolation Test Status: Status of the high-voltage bus electrical passive isolation test as performed by this High Voltage Energy Storage Pack instance.This parameter is for one of multiple packs in an HVESS. If there i...";
CM_ SG_ 2364658686 HVESP5HVILStatus "HVESP5 HVIL Status: Status of the High Voltage Interlock Loop from the viewpoint of this High Voltage Energy Storage Pack instance.This parameter is for one of multiple packs in an HVESS. If there is only one pack in the system, the HVESS parameters ...";
CM_ SG_ 2364658686 HVESP5InertiaSwitchStatus "HVESP5 Inertia Switch Status: Switch indicating that an impact has been sensed by this High Voltage Energy Storage Pack instance. The impact indication may require action by another controller, or by this HVES instance itself.  For example, a control...";
CM_ SG_ 2364658686 HVESP5StateofChargeStatus "HVESP5 State of Charge Status: Status of this High Voltage Energy Storage Pack instance State of Charge (SOC).  Note:  A given HVES controller may not support all of the states.This parameter is for one of multiple packs in an HVESS.  If there is onl...";
CM_ SG_ 2364658686 HVESP5CellBalanceStatus "HVESP5 Cell Balance Status: Indicates whether or not the cells in this High Voltage Energy Storage Pack instance are balanced.This parameter is for one of multiple packs in an HVESS.  If there is only one pack in the system, the HVESS parameters shou...";
CM_ SG_ 2364658686 HVESP5CellBalancingActive "HVESP5 Cell Balancing Active: Indicates whether or not the cells in this High Voltage Energy Storage Pack instance are currently being balanced.This parameter is for one of multiple packs in an HVESS.  If there is only one pack in the system, the HVE...";
CM_ SG_ 2364658686 HVESP5InternalChargerStatus "HVESP5 Internal Charger Status: Indicates that the charger in this HVES instance is on.  External chargers may use the External Energy Source Connection Status (SPN 7898) and related SPs.This parameter is for one of multiple packs in an HVESS. If the...";
CM_ SG_ 2364658686 HVESP5HghVltgBsCnntnStts "HVESP5 High-Voltage Bus Connection Status: This parameter provides high level feedback on this High Voltage Energy Storage Pack instance high voltage bus connection.  For specific contactor information, see SPN 11539 (HVESP5 High-Voltage Bus (Positiv...";
CM_ SG_ 2364658686 HVESP5OperationalStatus "HVESP5 Operational Status: Provides feedback on where this High Voltage Energy Storage Pack instance is in its operating spectrum, and includes feedback in response to the Operation Consent [i.e. SPN 11499 (HVESP5 Operation Consent)] and Power Down C...";
CM_ BO_ 2364658942 "High Voltage Energy Storage Pack 5 Data 7";
CM_ SG_ 2364658942 HVESP5DischargeEnergyCapacity "HVESP5 Discharge Energy Capacity: The amount of stored electrical energy in this High Voltage Energy Storage Pack instance that is available for use by the hybrid system, i.e. “how full is the tank”.  See SPN 11526 (HVESP5 Discharge Capacity) for Amp...";
CM_ SG_ 2364658942 HVESP5ChargeEnergyCapacity "HVESP5 Charge Energy Capacity: The amount of unused electrical energy storage available to be filled by charging this High Voltage Energy Storage Pack instance, i.e. “how much empty space is remaining in the tank”.  See SPN 11527 (HVESP5 Charge Capac...";
CM_ SG_ 2364658942 HVESP5MaximumChargeVoltageLimit "HVESP5 Maximum Charge Voltage Limit: The maximum voltage level not to be exceeded while charging this High Voltage Energy Storage Pack instance.  If this parameter is not supported, the maximum charge voltage should be limited to SPN 11598 (HVESP5 Re...";
CM_ BO_ 2364659198 "High Voltage Energy Storage Pack 5 Module Status 1";
CM_ SG_ 2364659198 HVESP5Module1OperationalStatus "HVESP5 Module 1 Operational Status: Operational Status of Module 1 in this High Voltage Energy Storage Pack Instance.  Not Operational is used when the module is initializing or not able to function (e.g. internal module level monitors have failed). ...";
CM_ SG_ 2364659198 HVESP5Module2OperationalStatus "HVESP5 Module 2 Operational Status: Operational Status of Module 2 in this High Voltage Energy Storage Pack Instance.  Not Operational is used when the module is initializing or not able to function (e.g. internal module level monitors have failed). ...";
CM_ SG_ 2364659198 HVESP5Module3OperationalStatus "HVESP5 Module 3 Operational Status: Operational Status of Module 3 in this High Voltage Energy Storage Pack Instance.  Not Operational is used when the module is initializing or not able to function (e.g. internal module level monitors have failed). ...";
CM_ SG_ 2364659198 HVESP5Module4OperationalStatus "HVESP5 Module 4 Operational Status: Operational Status of Module 4 in this High Voltage Energy Storage Pack Instance.  Not Operational is used when the module is initializing or not able to function (e.g. internal module level monitors have failed). ...";
CM_ SG_ 2364659198 HVESP5Module5OperationalStatus "HVESP5 Module 5 Operational Status: Operational Status of Module 5 in this High Voltage Energy Storage Pack Instance.  Not Operational is used when the module is initializing or not able to function (e.g. internal module level monitors have failed). ...";
CM_ SG_ 2364659198 HVESP5Module6OperationalStatus "HVESP5 Module 6 Operational Status: Operational Status of Module 6 in this High Voltage Energy Storage Pack Instance.  Not Operational is used when the module is initializing or not able to function (e.g. internal module level monitors have failed). ...";
CM_ SG_ 2364659198 HVESP5Module7OperationalStatus "HVESP5 Module 7 Operational Status: Operational Status of Module 7 in this High Voltage Energy Storage Pack Instance.  Not Operational is used when the module is initializing or not able to function (e.g. internal module level monitors have failed). ...";
CM_ SG_ 2364659198 HVESP5Module8OperationalStatus "HVESP5 Module 8 Operational Status: Operational Status of Module 8 in this High Voltage Energy Storage Pack Instance.  Not Operational is used when the module is initializing or not able to function (e.g. internal module level monitors have failed). ...";
CM_ SG_ 2364659198 HVESP5Module9OperationalStatus "HVESP5 Module 9 Operational Status: Operational Status of Module 9 in this High Voltage Energy Storage Pack Instance.  Not Operational is used when the module is initializing or not able to function (e.g. internal module level monitors have failed). ...";
CM_ SG_ 2364659198 HVESP5Module10OperationalStatus "HVESP5 Module 10 Operational Status: Operational Status of Module 10 in this High Voltage Energy Storage Pack Instance.  Not Operational is used when the module is initializing or not able to function (e.g. internal module level monitors have failed)...";
CM_ SG_ 2364659198 HVESP5Module11OperationalStatus "HVESP5 Module 11 Operational Status: Operational Status of Module 11 in this High Voltage Energy Storage Pack Instance.  Not Operational is used when the module is initializing or not able to function (e.g. internal module level monitors have failed)...";
CM_ SG_ 2364659198 HVESP5Module12OperationalStatus "HVESP5 Module 12 Operational Status: Operational Status of Module 12 in this High Voltage Energy Storage Pack Instance.  Not Operational is used when the module is initializing or not able to function (e.g. internal module level monitors have failed)...";
CM_ SG_ 2364659198 HVESP5Module13OperationalStatus "HVESP5 Module 13 Operational Status: Operational Status of Module 13 in this High Voltage Energy Storage Pack Instance.  Not Operational is used when the module is initializing or not able to function (e.g. internal module level monitors have failed)...";
CM_ SG_ 2364659198 HVESP5Module14OperationalStatus "HVESP5 Module 14 Operational Status: Operational Status of Module 14 in this High Voltage Energy Storage Pack Instance.  Not Operational is used when the module is initializing or not able to function (e.g. internal module level monitors have failed)...";
CM_ SG_ 2364659198 HVESP5Module15OperationalStatus "HVESP5 Module 15 Operational Status: Operational Status of Module 15 in this High Voltage Energy Storage Pack Instance.  Not Operational is used when the module is initializing or not able to function (e.g. internal module level monitors have failed)...";
CM_ SG_ 2364659198 HVESP5Module16OperationalStatus "HVESP5 Module 16 Operational Status: Operational Status of Module 16 in this High Voltage Energy Storage Pack Instance.  Not Operational is used when the module is initializing or not able to function (e.g. internal module level monitors have failed)...";
CM_ BO_ 2364659454 "High Voltage Energy Storage Pack 5 Thermal Management System Status 1";
CM_ SG_ 2364659454 HVESP5ThrmlMngmntSstmSLIInptPwr "HVESP5 Thermal Management System SLI Input Power: This is the low-voltage power consumed by this HVES Thermal Management System (TMS).This parameter is for one of multiple packs in an HVESS.  If there is only one pack in the system, the HVESS paramet...";
CM_ SG_ 2364659454 HVESP5TMtSstHVtIptPw "HVESP5 Thermal Management System High-Voltage Input Power: This is the high-voltage power consumed by this HVES Thermal Management System (TMS).This parameter is for one of multiple packs in an HVESS.  If there is only one pack in the system, the HVE...";
CM_ SG_ 2364659454 HVESP5ThrmlMngmntSstmCmprssrSpd "HVESP5 Thermal Management System Compressor Speed: When this High Voltage Energy Storage Pack Thermal Management System is equipped with an active cooling system (e.g. air conditioner), this is the Compressor Speed.This parameter is for one of multip...";
CM_ SG_ 2364659454 HVESP5ThrmlMngmntSstmRltvHmdt "HVESP5 Thermal Management System Relative Humidty: When this High Voltage Energy Storage Pack Thermal Management System is equipped with a relative humidity sensor, this is the  measured Relative Humidity.This parameter is for one of multiple packs i...";
CM_ SG_ 2364659454 HVESP5ThrmlMngmntSstmHtrStts "HVESP5 Thermal Management System Heater Status: The state of this High Voltage Energy Storage Pack heaterThis parameter is for one of multiple packs in an HVESS.  If there is only one pack in the system, the HVESS parameters should be used. If there ...";
CM_ SG_ 2364659454 HVESP5ThrmlMngmntSstmHVILStts "HVESP5 Thermal Management System HVIL Status: In multiple HVES configurations, this is the status of the High Voltage Interlock Loop from the viewpoint of this Thermal Management System.00b = HVIL Closed01b = HVIL Open10b = Error11b = Not AvailableTh...";
CM_ SG_ 2364659454 HVESP5ThrmlMngmntSstmMd "HVESP5 Thermal Management System Mode: Indicates the operating mode of the Thermal Management System.  The heat transfer medium may be (e.g. liquid or air).  The cooling system may be fans, liquid coolant, or a combination of mediums.  The system may...";
CM_ SG_ 2364659454 HVESP5ThrmlMngmntSstmClntLvl "HVESP5 Thermal Management System Coolant Level: Indicates the coolant level in this HVES Thermal Management System (TMS).This parameter is for one of multiple packs in an HVESS.  If there is only one pack in the system, the HVESS parameters should be...";
CM_ BO_ 2364659710 "High Voltage Energy Storage Pack 5 Data 8";
CM_ SG_ 2364659710 HVESP5HghstCllVltgMdlNmr "HVESP5 Highest Cell Voltage Module Number: Identifies the location of the module containing SPN 11519 (HVESP5 Highest Cell Voltage).This parameter is for one of multiple packs in an HVESS.  If there is only one pack in the system, the HVESS parameter...";
CM_ SG_ 2364659710 HVESP5HghstCllVltgCllNmr "HVESP5 Highest Cell Voltage Cell Number: Identifies the location of SPN 11519 (HVESP5 Highest Cell Voltage) within SPN 11579 (HVESP5 Highest Cell Voltage Module Number).This parameter is for one of multiple packs in an HVESS.  If there is only one pa...";
CM_ SG_ 2364659710 HVESP5LwstCllVltgMdlNmr "HVESP5 Lowest Cell Voltage Module Number: Identifies the location of the module containing SPN 11520 (HVESP5 Lowest Cell Voltage).This parameter is for one of multiple packs in an HVESS.  If there is only one pack in the system, the HVESS parameters ...";
CM_ SG_ 2364659710 HVESP5LwstCllVltgCllNmr "HVESP5 Lowest Cell Voltage Cell Number: Identifies the location of SPN 11520 (HVESP5 Lowest Cell Voltage) within SPN 11581 (HVESP5 Lowest Cell Voltage Module Number).This parameter is for one of multiple packs in an HVESS.  If there is only one pack ...";
CM_ SG_ 2364659710 HVESP5AverageCellVoltage "HVESP5 Average Cell Voltage: The average cell voltage in this High Voltage Energy Storage Pack instance.This parameter is for one of multiple packs in an HVESS.  If there is only one pack in the system, the HVESS parameters should be used. If there a...";
CM_ BO_ 2364659966 "High Voltage Energy Storage Pack 5 Data 9";
CM_ SG_ 2364659966 HVESP5HghstCllTmprtrMdlNmr "HVESP5 Highest Cell Temperature Module Number: Identifies the location of the module containing SPN 11522 (HVESP5 Highest Cell Temperature).This parameter is for one of multiple packs in an HVESS.  If there is only one pack in the system, the HVESS p...";
CM_ SG_ 2364659966 HVESP5HghstCllTmprtrCllNmr "HVESP5 Highest Cell Temperature Cell Number: Identifies the location of SPN 11522 (HVESP5 Highest Cell Temperature) within SPN 11584 (HVESP5 Highest Cell Temperature Module Number).This parameter is for one of multiple packs in an HVESS.  If there is...";
CM_ SG_ 2364659966 HVESP5LwstCllTmprtrMdlNmr "HVESP5 Lowest Cell Temperature Module Number: Identifies the location of the module containing SPN 11523 (HVESP5 Lowest Cell Temperature).This parameter is for one of multiple packs in an HVESS.  If there is only one pack in the system, the HVESS par...";
CM_ SG_ 2364659966 HVESP5LwstCllTmprtrCllNmr "HVESP5 Lowest Cell Temperature Cell Number: Identifies the location of SPN 11523 (HVESP5 Lowest Cell Temperature) within SPN 11586 (HVESP5 Lowest Cell Temperature Module Number).This parameter is for one of multiple packs in an HVESS.  If there is on...";
CM_ BO_ 2364660222 "High Voltage Energy Storage Pack 5 Data 10";
CM_ SG_ 2364660222 HVESP5HghstCllSttfChrgMdlNmr "HVESP5 Highest Cell State of Charge Module Number: Identifies the location of the module containing SPN 11532 (HVESP5 Highest Cell State of Charge).This parameter is for one of multiple packs in an HVESS.  If there is only one pack in the system, the...";
CM_ SG_ 2364660222 HVESP5HghstCllSttfChrgCllNmr "HVESP5 Highest Cell State of Charge Cell Number: Identifies the location of SPN 11532 (HVESP5 Highest Cell State of Charge) within SPN 11588 (HVESP5 Highest Cell State of Charge Module Number).This parameter is for one of multiple packs in an HVESS. ...";
CM_ SG_ 2364660222 HVESP5LwstCllSttfChrgMdlNmr "HVESP5 Lowest Cell State of Charge Module Number: Identifies the location of the module containing SPN 11531 (HVESP5 Lowest Cell State of Charge).This parameter is for one of multiple packs in an HVESS.  If there is only one pack in the system, the H...";
CM_ SG_ 2364660222 HVESP5LwstCllSttfChrgCllNmr "HVESP5 Lowest Cell State of Charge Cell Number: Identifies the location of SPN 11531 (HVESP5 Lowest Cell State of Charge) within SPN 11590 (HVESP5 Lowest Cell State of Charge Module Number).This parameter is for one of multiple packs in an HVESS.  If...";
CM_ SG_ 2364660222 HVESP5HghVltgBsAtvIsltnTstRslts "HVESP5 High-Voltage Bus Active Isolation Test Results: The isolation resistance expressed in Ohms per Volt that resulted from the High-Voltage Bus Active Isolation Test.See SPN 11544 (HVESP5 High-Voltage Bus Active Isolation Test Status) for test sta...";
CM_ SG_ 2364660222 HVESP5HVtBsPssvIstTstRsts "HVESP5 High-Voltage Bus Passive Isolation Test Results: The isolation resistance expressed in Ohms per Volt that resulted from the High-Voltage Bus Passive Isolation Test.See SPN 11545 (HVESP5 High-Voltage Bus Passive Isolation Test Status) for test ...";
CM_ BO_ 2364660478 "High Voltage Energy Storage Pack 5 Data 11";
CM_ SG_ 2364660478 HVESP5BsVltgNgtvtChsssGrndVltg "HVESP5 Bus Voltage Negative to Chassis Ground Voltage: Voltage difference between the most negative terminal of the HVES battery and chassis measured on the hybrid system bus side (not the battery side) of any HVES contained output contactor.  This v...";
CM_ SG_ 2364660478 HVESP5VltgLvlNgtvtChsssGrndVltg "HVESP5 Voltage Level Negative to Chassis Ground Voltage: Voltage difference between the most negative terminal of the HVES battery and chassis measured at the battery side of any HVES contained output contactor.  This voltage may be used for system l...";
BA_DEF_ SG_  "SPN" INT 0 524287;
BA_DEF_ BO_  "VFrameFormat" ENUM  "StandardCAN","ExtendedCAN","reserved","J1939PG";
BA_DEF_DEF_  "SPN" 0;
BA_DEF_DEF_  "VFrameFormat" "J1939PG";
BA_ "SPN" SG_ 2364643838 HVESP1Module1OperationalStatus 11093;
BA_ "SPN" SG_ 2364643838 HVESP1Module2OperationalStatus 11094;
BA_ "SPN" SG_ 2364643838 HVESP1Module3OperationalStatus 11095;
BA_ "SPN" SG_ 2364643838 HVESP1Module4OperationalStatus 11096;
BA_ "SPN" SG_ 2364643838 HVESP1Module5OperationalStatus 11097;
BA_ "SPN" SG_ 2364643838 HVESP1Module6OperationalStatus 11098;
BA_ "SPN" SG_ 2364643838 HVESP1Module7OperationalStatus 11099;
BA_ "SPN" SG_ 2364643838 HVESP1Module8OperationalStatus 11100;
BA_ "SPN" SG_ 2364643838 HVESP1Module9OperationalStatus 11101;
BA_ "SPN" SG_ 2364643838 HVESP1Module10OperationalStatus 11102;
BA_ "SPN" SG_ 2364643838 HVESP1Module11OperationalStatus 11103;
BA_ "SPN" SG_ 2364643838 HVESP1Module12OperationalStatus 11104;
BA_ "SPN" SG_ 2364643838 HVESP1Module13OperationalStatus 11105;
BA_ "SPN" SG_ 2364643838 HVESP1Module14OperationalStatus 11106;
BA_ "SPN" SG_ 2364643838 HVESP1Module15OperationalStatus 11107;
BA_ "SPN" SG_ 2364643838 HVESP1Module16OperationalStatus 11108;
BA_ "SPN" SG_ 2364644094 HVESP1ThrmlMngmntSstmSLIInptPwr 11109;
BA_ "SPN" SG_ 2364644094 HVESP1TMtSstHVtIptPw 11110;
BA_ "SPN" SG_ 2364644094 HVESP1ThrmlMngmntSstmCmprssrSpd 11111;
BA_ "SPN" SG_ 2364644094 HVESP1ThrmlMngmntSstmRltvHmdt 11112;
BA_ "SPN" SG_ 2364644094 HVESP1ThrmlMngmntSstmHtrStts 11113;
BA_ "SPN" SG_ 2364644094 HVESP1ThrmlMngmntSstmHVILStts 12819;
BA_ "SPN" SG_ 2364644094 HVESP1ThrmlMngmntSstmMd 11114;
BA_ "SPN" SG_ 2364644094 HVESP1ThrmlMngmntSstmClntLvl 12898;
BA_ "SPN" SG_ 2364644350 HVESP1HghstCllVltgMdlNmr 11115;
BA_ "SPN" SG_ 2364644350 HVESP1HghstCllVltgCllNmr 11116;
BA_ "SPN" SG_ 2364644350 HVESP1LwstCllVltgMdlNmr 11117;
BA_ "SPN" SG_ 2364644350 HVESP1LwstCllVltgCllNmr 11118;
BA_ "SPN" SG_ 2364644350 HVESP1AverageCellVoltage 11119;
BA_ "SPN" SG_ 2364644606 HVESP1HghstCllTmprtrMdlNmr 11120;
BA_ "SPN" SG_ 2364644606 HVESP1HghstCllTmprtrCllNmr 11121;
BA_ "SPN" SG_ 2364644606 HVESP1LwstCllTmprtrMdlNmr 11122;
BA_ "SPN" SG_ 2364644606 HVESP1LwstCllTmprtrCllNmr 11123;
BA_ "SPN" SG_ 2364644862 HVESP1HghstCllSttfChrgMdlNmr 11124;
BA_ "SPN" SG_ 2364644862 HVESP1HghstCllSttfChrgCllNmr 11125;
BA_ "SPN" SG_ 2364644862 HVESP1LwstCllSttfChrgMdlNmr 11126;
BA_ "SPN" SG_ 2364644862 HVESP1LwstCllSttfChrgCllNmr 11127;
BA_ "SPN" SG_ 2364644862 HVESP1HghVltgBsAtvIsltnTstRslts 11128;
BA_ "SPN" SG_ 2364644862 HVESP1HVtBsPssvIstTstRsts 11129;
BA_ "SPN" SG_ 2364645118 HVESP1BsVltgNgtvtChsssGrndVltg 11130;
BA_ "SPN" SG_ 2364645118 HVESP1VltgLvlNgtvtChsssGrndVltg 11131;
BA_ "SPN" SG_ 2364645374 HVESP2DshrgPwrLmtDtSttfChrg 11154;
BA_ "SPN" SG_ 2364645374 HVESP2DshrgPwrLmtDtBttrTmprtr 11155;
BA_ "SPN" SG_ 2364645374 HVESP2DsPwLtDtBttDstCdt 11156;
BA_ "SPN" SG_ 2364645374 HVESP2DshrgPwrLmtDtBttrrCllVltg 11157;
BA_ "SPN" SG_ 2364645374 HVESP2DshrgPwrLmtDtBttrCrrnt 11158;
BA_ "SPN" SG_ 2364645374 HVESP2DshrgPwrLmtDtnUndfndCs 11159;
BA_ "SPN" SG_ 2364645374 HVESP2ChrgPwrLmtDtSttfChrg 11160;
BA_ "SPN" SG_ 2364645374 HVESP2ChrgPwrLmtDtBttrTmprtr 11161;
BA_ "SPN" SG_ 2364645374 HVESP2CPwLtDtBttDstCdt 11162;
BA_ "SPN" SG_ 2364645374 HVESP2ChrgPwrLmtDtBttrrCllVltg 11163;
BA_ "SPN" SG_ 2364645374 HVESP2ChrgPwrLmtDtBttrCrrnt 11164;
BA_ "SPN" SG_ 2364645374 HVESP2ChrgPwrLmtDtnUndfndCs 11165;
BA_ "SPN" SG_ 2364645630 HVESP2AvailableDischargePower 11166;
BA_ "SPN" SG_ 2364645630 HVESP2AvailableChargePower 11167;
BA_ "SPN" SG_ 2364645630 HVESP2VoltageLevel 11168;
BA_ "SPN" SG_ 2364645630 HVESP2Current 11169;
BA_ "SPN" SG_ 2364645886 HVESP2FastUpdateStateofCharge 11170;
BA_ "SPN" SG_ 2364645886 HVESP2HighestCellVoltage 11171;
BA_ "SPN" SG_ 2364645886 HVESP2LowestCellVoltage 11172;
BA_ "SPN" SG_ 2364645886 HVESP2CllVltgDffrntlStts 11173;
BA_ "SPN" SG_ 2364646142 HVESP2HighestCellTemperature 11174;
BA_ "SPN" SG_ 2364646142 HVESP2LowestCellTemperature 11175;
BA_ "SPN" SG_ 2364646142 HVESP2AverageCellTemperature 11176;
BA_ "SPN" SG_ 2364646142 HVESP2CllTmprtrDffrntlStts 11177;
BA_ "SPN" SG_ 2364646398 HVESP2DischargeCapacity 11178;
BA_ "SPN" SG_ 2364646398 HVESP2ChargeCapacity 11179;
BA_ "SPN" SG_ 2364646398 HVESP2CellBalancingCount 11180;
BA_ "SPN" SG_ 2364646654 HVESP2DischargeCurrentLimit 11181;
BA_ "SPN" SG_ 2364646654 HVESP2ChargeCurrentLimit 11182;
BA_ "SPN" SG_ 2364646654 HVESP2LowestCellStateofCharge 11183;
BA_ "SPN" SG_ 2364646654 HVESP2HighestCellStateofCharge 11184;
BA_ "SPN" SG_ 2364646910 HVESP2BusVoltage 11185;
BA_ "SPN" SG_ 2364646910 HVESP2IgnitionVoltage 11186;
BA_ "SPN" SG_ 2364646910 HVESP2IntakeCoolantTemperature 11187;
BA_ "SPN" SG_ 2364646910 HVESP2OutletCoolantTemperature 11188;
BA_ "SPN" SG_ 2364646910 HVESP2ElectronicsTemperature 11189;
BA_ "SPN" SG_ 2364646910 HVESP2Temperature 11190;
BA_ "SPN" SG_ 2364647166 HVESP2HghVltgBsPstvCnttrStt 11191;
BA_ "SPN" SG_ 2364647166 HVESP2HghVltgBsNgtvCnttrStt 11192;
BA_ "SPN" SG_ 2364647166 HVESP2HghVltgBsDsnntFrwrnng 11193;
BA_ "SPN" SG_ 2364647166 HVESP2HghVltgBsPrChrgRlStt 11194;
BA_ "SPN" SG_ 2364647166 HVESP2CntrfPkCnttrStt 11195;
BA_ "SPN" SG_ 2364647166 HVESP2HghVltgBsAtvIsltnTstStts 11196;
BA_ "SPN" SG_ 2364647166 HVESP2HghVltgBsPssvIsltnTstStts 11197;
BA_ "SPN" SG_ 2364647166 HVESP2HVILStatus 11198;
BA_ "SPN" SG_ 2364647166 HVESP2InertiaSwitchStatus 11199;
BA_ "SPN" SG_ 2364647166 HVESP2StateofChargeStatus 11200;
BA_ "SPN" SG_ 2364647166 HVESP2CellBalanceStatus 11201;
BA_ "SPN" SG_ 2364647166 HVESP2CellBalancingActive 11202;
BA_ "SPN" SG_ 2364647166 HVESP2InternalChargerStatus 11203;
BA_ "SPN" SG_ 2364647166 HVESP2HghVltgBsCnntnStts 11204;
BA_ "SPN" SG_ 2364647166 HVESP2OperationalStatus 11205;
BA_ "SPN" SG_ 2364647422 HVESP2DischargeEnergyCapacity 11206;
BA_ "SPN" SG_ 2364647422 HVESP2ChargeEnergyCapacity 11207;
BA_ "SPN" SG_ 2364647422 HVESP2MaximumChargeVoltageLimit 11208;
BA_ "SPN" SG_ 2364647678 HVESP2Module1OperationalStatus 11209;
BA_ "SPN" SG_ 2364647678 HVESP2Module2OperationalStatus 11210;
BA_ "SPN" SG_ 2364647678 HVESP2Module3OperationalStatus 11211;
BA_ "SPN" SG_ 2364647678 HVESP2Module4OperationalStatus 11212;
BA_ "SPN" SG_ 2364647678 HVESP2Module5OperationalStatus 11213;
BA_ "SPN" SG_ 2364647678 HVESP2Module6OperationalStatus 11214;
BA_ "SPN" SG_ 2364647678 HVESP2Module7OperationalStatus 11215;
BA_ "SPN" SG_ 2364647678 HVESP2Module8OperationalStatus 11216;
BA_ "SPN" SG_ 2364647678 HVESP2Module9OperationalStatus 11217;
BA_ "SPN" SG_ 2364647678 HVESP2Module10OperationalStatus 11218;
BA_ "SPN" SG_ 2364647678 HVESP2Module11OperationalStatus 11219;
BA_ "SPN" SG_ 2364647678 HVESP2Module12OperationalStatus 11220;
BA_ "SPN" SG_ 2364647678 HVESP2Module13OperationalStatus 11221;
BA_ "SPN" SG_ 2364647678 HVESP2Module14OperationalStatus 11222;
BA_ "SPN" SG_ 2364647678 HVESP2Module15OperationalStatus 11223;
BA_ "SPN" SG_ 2364647678 HVESP2Module16OperationalStatus 11224;
BA_ "SPN" SG_ 2364647934 HVESP2ThrmlMngmntSstmSLIInptPwr 11225;
BA_ "SPN" SG_ 2364647934 HVESP2TMtSstHVtIptPw 11226;
BA_ "SPN" SG_ 2364647934 HVESP2ThrmlMngmntSstmCmprssrSpd 11227;
BA_ "SPN" SG_ 2364647934 HVESP2ThrmlMngmntSstmRltvHmdt 11228;
BA_ "SPN" SG_ 2364647934 HVESP2ThrmlMngmntSstmHtrStts 11229;
BA_ "SPN" SG_ 2364647934 HVESP2ThrmlMngmntSstmHVILStts 12818;
BA_ "SPN" SG_ 2364647934 HVESP2ThrmlMngmntSstmMd 11230;
BA_ "SPN" SG_ 2364647934 HVESP2ThrmlMngmntSstmClntLvl 12899;
BA_ "SPN" SG_ 2364648190 HVESP2HghstCllVltgMdlNmr 11231;
BA_ "SPN" SG_ 2364648190 HVESP2HghstCllVltgCllNmr 11232;
BA_ "SPN" SG_ 2364648190 HVESP2LwstCllVltgMdlNmr 11233;
BA_ "SPN" SG_ 2364648190 HVESP2LwstCllVltgCllNmr 11234;
BA_ "SPN" SG_ 2364648190 HVESP2AverageCellVoltage 11235;
BA_ "SPN" SG_ 2364648446 HVESP2HghstCllTmprtrMdlNmr 11236;
BA_ "SPN" SG_ 2364648446 HVESP2HghstCllTmprtrCllNmr 11237;
BA_ "SPN" SG_ 2364648446 HVESP2LwstCllTmprtrMdlNmr 11238;
BA_ "SPN" SG_ 2364648446 HVESP2LwstCllTmprtrCllNmr 11239;
BA_ "SPN" SG_ 2364648702 HVESP2HghstCllSttfChrgMdlNmr 11240;
BA_ "SPN" SG_ 2364648702 HVESP2HghstCllSttfChrgCllNmr 11241;
BA_ "SPN" SG_ 2364648702 HVESP2LwstCllSttfChrgMdlNmr 11242;
BA_ "SPN" SG_ 2364648702 HVESP2LwstCllSttfChrgCllNmr 11243;
BA_ "SPN" SG_ 2364648702 HVESP2HghVltgBsAtvIsltnTstRslts 11244;
BA_ "SPN" SG_ 2364648702 HVESP2HVtBsPssvIstTstRsts 11245;
BA_ "SPN" SG_ 2364648958 HVESP2BsVltgNgtvtChsssGrndVltg 11246;
BA_ "SPN" SG_ 2364648958 HVESP2VltgLvlNgtvtChsssGrndVltg 11247;
BA_ "SPN" SG_ 2364649214 HVESP3DshrgPwrLmtDtSttfChrg 11270;
BA_ "SPN" SG_ 2364649214 HVESP3DshrgPwrLmtDtBttrTmprtr 11271;
BA_ "SPN" SG_ 2364649214 HVESP3DsPwLtDtBttDstCdt 11272;
BA_ "SPN" SG_ 2364649214 HVESP3DshrgPwrLmtDtBttrrCllVltg 11273;
BA_ "SPN" SG_ 2364649214 HVESP3DshrgPwrLmtDtBttrCrrnt 11274;
BA_ "SPN" SG_ 2364649214 HVESP3DshrgPwrLmtDtnUndfndCs 11275;
BA_ "SPN" SG_ 2364649214 HVESP3ChrgPwrLmtDtSttfChrg 11276;
BA_ "SPN" SG_ 2364649214 HVESP3ChrgPwrLmtDtBttrTmprtr 11277;
BA_ "SPN" SG_ 2364649214 HVESP3CPwLtDtBttDstCdt 11278;
BA_ "SPN" SG_ 2364649214 HVESP3ChrgPwrLmtDtBttrrCllVltg 11279;
BA_ "SPN" SG_ 2364649214 HVESP3ChrgPwrLmtDtBttrCrrnt 11280;
BA_ "SPN" SG_ 2364649214 HVESP3ChrgPwrLmtDtnUndfndCs 11281;
BA_ "SPN" SG_ 2364649470 HVESP3AvailableDischargePower 11282;
BA_ "SPN" SG_ 2364649470 HVESP3AvailableChargePower 11283;
BA_ "SPN" SG_ 2364649470 HVESP3VoltageLevel 11284;
BA_ "SPN" SG_ 2364649470 HVESP3Current 11285;
BA_ "SPN" SG_ 2364649726 HVESP3FastUpdateStateofCharge 11286;
BA_ "SPN" SG_ 2364649726 HVESP3HighestCellVoltage 11287;
BA_ "SPN" SG_ 2364649726 HVESP3LowestCellVoltage 11288;
BA_ "SPN" SG_ 2364649726 HVESP3CllVltgDffrntlStts 11289;
BA_ "SPN" SG_ 2364649982 HVESP3HighestCellTemperature 11290;
BA_ "SPN" SG_ 2364649982 HVESP3LowestCellTemperature 11291;
BA_ "SPN" SG_ 2364649982 HVESP3AverageCellTemperature 11292;
BA_ "SPN" SG_ 2364649982 HVESP3CllTmprtrDffrntlStts 11293;
BA_ "SPN" SG_ 2364650238 HVESP3DischargeCapacity 11294;
BA_ "SPN" SG_ 2364650238 HVESP3ChargeCapacity 11295;
BA_ "SPN" SG_ 2364650238 HVESP3CellBalancingCount 11296;
BA_ "SPN" SG_ 2364650494 HVESP3DischargeCurrentLimit 11297;
BA_ "SPN" SG_ 2364650494 HVESP3ChargeCurrentLimit 11298;
BA_ "SPN" SG_ 2364650494 HVESP3LowestCellStateofCharge 11299;
BA_ "SPN" SG_ 2364650494 HVESP3HighestCellStateofCharge 11300;
BA_ "SPN" SG_ 2364650750 HVESP3BusVoltage 11301;
BA_ "SPN" SG_ 2364650750 HVESP3IgnitionVoltage 11302;
BA_ "SPN" SG_ 2364650750 HVESP3IntakeCoolantTemperature 11303;
BA_ "SPN" SG_ 2364650750 HVESP3OutletCoolantTemperature 11304;
BA_ "SPN" SG_ 2364650750 HVESP3ElectronicsTemperature 11305;
BA_ "SPN" SG_ 2364650750 HVESP3Temperature 11306;
BA_ "SPN" SG_ 2364651006 HVESP3HghVltgBsPstvCnttrStt 11307;
BA_ "SPN" SG_ 2364651006 HVESP3HghVltgBsNgtvCnttrStt 11308;
BA_ "SPN" SG_ 2364651006 HVESP3HghVltgBsDsnntFrwrnng 11309;
BA_ "SPN" SG_ 2364651006 HVESP3HghVltgBsPrChrgRlStt 11310;
BA_ "SPN" SG_ 2364651006 HVESP3CntrfPkCnttrStt 11311;
BA_ "SPN" SG_ 2364651006 HVESP3HghVltgBsAtvIsltnTstStts 11312;
BA_ "SPN" SG_ 2364651006 HVESP3HghVltgBsPssvIsltnTstStts 11313;
BA_ "SPN" SG_ 2364651006 HVESP3HVILStatus 11314;
BA_ "SPN" SG_ 2364651006 HVESP3InertiaSwitchStatus 11315;
BA_ "SPN" SG_ 2364651006 HVESP3StateofChargeStatus 11316;
BA_ "SPN" SG_ 2364651006 HVESP3CellBalanceStatus 11317;
BA_ "SPN" SG_ 2364651006 HVESP3CellBalancingActive 11318;
BA_ "SPN" SG_ 2364651006 HVESP3InternalChargerStatus 11319;
BA_ "SPN" SG_ 2364651006 HVESP3HghVltgBsCnntnStts 11320;
BA_ "SPN" SG_ 2364651006 HVESP3OperationalStatus 11321;
BA_ "SPN" SG_ 2364651262 HVESP3DischargeEnergyCapacity 11322;
BA_ "SPN" SG_ 2364651262 HVESP3ChargeEnergyCapacity 11323;
BA_ "SPN" SG_ 2364651262 HVESP3MaximumChargeVoltageLimit 11324;
BA_ "SPN" SG_ 2364651518 HVESP3Module1OperationalStatus 11325;
BA_ "SPN" SG_ 2364651518 HVESP3Module2OperationalStatus 11326;
BA_ "SPN" SG_ 2364651518 HVESP3Module3OperationalStatus 11327;
BA_ "SPN" SG_ 2364651518 HVESP3Module4OperationalStatus 11328;
BA_ "SPN" SG_ 2364651518 HVESP3Module5OperationalStatus 11329;
BA_ "SPN" SG_ 2364651518 HVESP3Module6OperationalStatus 11330;
BA_ "SPN" SG_ 2364651518 HVESP3Module7OperationalStatus 11331;
BA_ "SPN" SG_ 2364651518 HVESP3Module8OperationalStatus 11332;
BA_ "SPN" SG_ 2364651518 HVESP3Module9OperationalStatus 11333;
BA_ "SPN" SG_ 2364651518 HVESP3Module10OperationalStatus 11334;
BA_ "SPN" SG_ 2364651518 HVESP3Module11OperationalStatus 11335;
BA_ "SPN" SG_ 2364651518 HVESP3Module12OperationalStatus 11336;
BA_ "SPN" SG_ 2364651518 HVESP3Module13OperationalStatus 11337;
BA_ "SPN" SG_ 2364651518 HVESP3Module14OperationalStatus 11338;
BA_ "SPN" SG_ 2364651518 HVESP3Module15OperationalStatus 11339;
BA_ "SPN" SG_ 2364651518 HVESP3Module16OperationalStatus 11340;
BA_ "SPN" SG_ 2364651774 HVESP3ThrmlMngmntSstmSLIInptPwr 11341;
BA_ "SPN" SG_ 2364651774 HVESP3TMtSstHVtIptPw 11342;
BA_ "SPN" SG_ 2364651774 HVESP3ThrmlMngmntSstmCmprssrSpd 11343;
BA_ "SPN" SG_ 2364651774 HVESP3ThrmlMngmntSstmRltvHmdt 11344;
BA_ "SPN" SG_ 2364651774 HVESP3ThrmlMngmntSstmHtrStts 11345;
BA_ "SPN" SG_ 2364651774 HVESP3ThrmlMngmntSstmHVILStts 12817;
BA_ "SPN" SG_ 2364651774 HVESP3ThrmlMngmntSstmMd 11346;
BA_ "SPN" SG_ 2364651774 HVESP3ThrmlMngmntSstmClntLvl 12900;
BA_ "SPN" SG_ 2364652030 HVESP3HghstCllVltgMdlNmr 11347;
BA_ "SPN" SG_ 2364652030 HVESP3HghstCllVltgCllNmr 11348;
BA_ "SPN" SG_ 2364652030 HVESP3LwstCllVltgMdlNmr 11349;
BA_ "SPN" SG_ 2364652030 HVESP3LwstCllVltgCllNmr 11350;
BA_ "SPN" SG_ 2364652030 HVESP3AverageCellVoltage 11351;
BA_ "SPN" SG_ 2364652286 HVESP3HghstCllTmprtrMdlNmr 11352;
BA_ "SPN" SG_ 2364652286 HVESP3HghstCllTmprtrCllNmr 11353;
BA_ "SPN" SG_ 2364652286 HVESP3LwstCllTmprtrMdlNmr 11354;
BA_ "SPN" SG_ 2364652286 HVESP3LwstCllTmprtrCllNmr 11355;
BA_ "SPN" SG_ 2364652542 HVESP3HghstCllSttfChrgMdlNmr 11356;
BA_ "SPN" SG_ 2364652542 HVESP3HghstCllSttfChrgCllNmr 11357;
BA_ "SPN" SG_ 2364652542 HVESP3LwstCllSttfChrgMdlNmr 11358;
BA_ "SPN" SG_ 2364652542 HVESP3LwstCllSttfChrgCllNmr 11359;
BA_ "SPN" SG_ 2364652542 HVESP3HghVltgBsAtvIsltnTstRslts 11360;
BA_ "SPN" SG_ 2364652542 HVESP3HVtBsPssvIstTstRsts 11361;
BA_ "SPN" SG_ 2364652798 HVESP3BsVltgNgtvtChsssGrndVltg 11362;
BA_ "SPN" SG_ 2364652798 HVESP3VltgLvlNgtvtChsssGrndVltg 11363;
BA_ "SPN" SG_ 2364653054 HVESP4DshrgPwrLmtDtSttfChrg 11386;
BA_ "SPN" SG_ 2364653054 HVESP4DshrgPwrLmtDtBttrTmprtr 11387;
BA_ "SPN" SG_ 2364653054 HVESP4DsPwLtDtBttDstCdt 11388;
BA_ "SPN" SG_ 2364653054 HVESP4DshrgPwrLmtDtBttrrCllVltg 11389;
BA_ "SPN" SG_ 2364653054 HVESP4DshrgPwrLmtDtBttrCrrnt 11390;
BA_ "SPN" SG_ 2364653054 HVESP4DshrgPwrLmtDtnUndfndCs 11391;
BA_ "SPN" SG_ 2364653054 HVESP4ChrgPwrLmtDtSttfChrg 11392;
BA_ "SPN" SG_ 2364653054 HVESP4ChrgPwrLmtDtBttrTmprtr 11393;
BA_ "SPN" SG_ 2364653054 HVESP4CPwLtDtBttDstCdt 11394;
BA_ "SPN" SG_ 2364653054 HVESP4ChrgPwrLmtDtBttrrCllVltg 11395;
BA_ "SPN" SG_ 2364653054 HVESP4ChrgPwrLmtDtBttrCrrnt 11396;
BA_ "SPN" SG_ 2364653054 HVESP4ChrgPwrLmtDtnUndfndCs 11397;
BA_ "SPN" SG_ 2364653310 HVESP4AvailableDischargePower 11398;
BA_ "SPN" SG_ 2364653310 HVESP4AvailableChargePower 11399;
BA_ "SPN" SG_ 2364653310 HVESP4VoltageLevel 11400;
BA_ "SPN" SG_ 2364653310 HVESP4Current 11401;
BA_ "SPN" SG_ 2364653566 HVESP4FastUpdateStateofCharge 11402;
BA_ "SPN" SG_ 2364653566 HVESP4HighestCellVoltage 11403;
BA_ "SPN" SG_ 2364653566 HVESP4LowestCellVoltage 11404;
BA_ "SPN" SG_ 2364653566 HVESP4CllVltgDffrntlStts 11405;
BA_ "SPN" SG_ 2364653822 HVESP4HighestCellTemperature 11406;
BA_ "SPN" SG_ 2364653822 HVESP4LowestCellTemperature 11407;
BA_ "SPN" SG_ 2364653822 HVESP4AverageCellTemperature 11408;
BA_ "SPN" SG_ 2364653822 HVESP4CllTmprtrDffrntlStts 11409;
BA_ "SPN" SG_ 2364654078 HVESP4DischargeCapacity 11410;
BA_ "SPN" SG_ 2364654078 HVESP4ChargeCapacity 11411;
BA_ "SPN" SG_ 2364654078 HVESP4CellBalancingCount 11412;
BA_ "SPN" SG_ 2364654334 HVESP4DischargeCurrentLimit 11413;
BA_ "SPN" SG_ 2364654334 HVESP4ChargeCurrentLimit 11414;
BA_ "SPN" SG_ 2364654334 HVESP4LowestCellStateofCharge 11415;
BA_ "SPN" SG_ 2364654334 HVESP4HighestCellStateofCharge 11416;
BA_ "SPN" SG_ 2364654590 HVESP4BusVoltage 11417;
BA_ "SPN" SG_ 2364654590 HVESP4IgnitionVoltage 11418;
BA_ "SPN" SG_ 2364654590 HVESP4IntakeCoolantTemperature 11419;
BA_ "SPN" SG_ 2364654590 HVESP4OutletCoolantTemperature 11420;
BA_ "SPN" SG_ 2364654590 HVESP4ElectronicsTemperature 11421;
BA_ "SPN" SG_ 2364654590 HVESP4Temperature 11422;
BA_ "SPN" SG_ 2364654846 HVESP4HghVltgBsPstvCnttrStt 11423;
BA_ "SPN" SG_ 2364654846 HVESP4HghVltgBsNgtvCnttrStt 11424;
BA_ "SPN" SG_ 2364654846 HVESP4HghVltgBsDsnntFrwrnng 11425;
BA_ "SPN" SG_ 2364654846 HVESP4HghVltgBsPrChrgRlStt 11426;
BA_ "SPN" SG_ 2364654846 HVESP4CntrfPkCnttrStt 11427;
BA_ "SPN" SG_ 2364654846 HVESP4HghVltgBsAtvIsltnTstStts 11428;
BA_ "SPN" SG_ 2364654846 HVESP4HghVltgBsPssvIsltnTstStts 11429;
BA_ "SPN" SG_ 2364654846 HVESP4HVILStatus 11430;
BA_ "SPN" SG_ 2364654846 HVESP4InertiaSwitchStatus 11431;
BA_ "SPN" SG_ 2364654846 HVESP4StateofChargeStatus 11432;
BA_ "SPN" SG_ 2364654846 HVESP4CellBalanceStatus 11433;
BA_ "SPN" SG_ 2364654846 HVESP4CellBalancingActive 11434;
BA_ "SPN" SG_ 2364654846 HVESP4InternalChargerStatus 11435;
BA_ "SPN" SG_ 2364654846 HVESP4HghVltgBsCnntnStts 11436;
BA_ "SPN" SG_ 2364654846 HVESP4OperationalStatus 11437;
BA_ "SPN" SG_ 2364655102 HVESP4DischargeEnergyCapacity 11438;
BA_ "SPN" SG_ 2364655102 HVESP4ChargeEnergyCapacity 11439;
BA_ "SPN" SG_ 2364655102 HVESP4MaximumChargeVoltageLimit 11440;
BA_ "SPN" SG_ 2364655358 HVESP4Module1OperationalStatus 11441;
BA_ "SPN" SG_ 2364655358 HVESP4Module2OperationalStatus 11442;
BA_ "SPN" SG_ 2364655358 HVESP4Module3OperationalStatus 11443;
BA_ "SPN" SG_ 2364655358 HVESP4Module4OperationalStatus 11444;
BA_ "SPN" SG_ 2364655358 HVESP4Module5OperationalStatus 11445;
BA_ "SPN" SG_ 2364655358 HVESP4Module6OperationalStatus 11446;
BA_ "SPN" SG_ 2364655358 HVESP4Module7OperationalStatus 11447;
BA_ "SPN" SG_ 2364655358 HVESP4Module8OperationalStatus 11448;
BA_ "SPN" SG_ 2364655358 HVESP4Module9OperationalStatus 11449;
BA_ "SPN" SG_ 2364655358 HVESP4Module10OperationalStatus 11450;
BA_ "SPN" SG_ 2364655358 HVESP4Module11OperationalStatus 11451;
BA_ "SPN" SG_ 2364655358 HVESP4Module12OperationalStatus 11452;
BA_ "SPN" SG_ 2364655358 HVESP4Module13OperationalStatus 11453;
BA_ "SPN" SG_ 2364655358 HVESP4Module14OperationalStatus 11454;
BA_ "SPN" SG_ 2364655358 HVESP4Module15OperationalStatus 11455;
BA_ "SPN" SG_ 2364655358 HVESP4Module16OperationalStatus 11456;
BA_ "SPN" SG_ 2364655614 HVESP4ThrmlMngmntSstmSLIInptPwr 11457;
BA_ "SPN" SG_ 2364655614 HVESP4TMtSstHVtIptPw 11458;
BA_ "SPN" SG_ 2364655614 HVESP4ThrmlMngmntSstmCmprssrSpd 11459;
BA_ "SPN" SG_ 2364655614 HVESP4ThrmlMngmntSstmRltvHmdt 11460;
BA_ "SPN" SG_ 2364655614 HVESP4ThrmlMngmntSstmHtrStts 11461;
BA_ "SPN" SG_ 2364655614 HVESP4ThrmlMngmntSstmHVILStts 12816;
BA_ "SPN" SG_ 2364655614 HVESP4ThrmlMngmntSstmMd 11462;
BA_ "SPN" SG_ 2364655614 HVESP4ThrmlMngmntSstmClntLvl 12901;
BA_ "SPN" SG_ 2364655870 HVESP4HghstCllVltgMdlNmr 11463;
BA_ "SPN" SG_ 2364655870 HVESP4HghstCllVltgCllNmr 11464;
BA_ "SPN" SG_ 2364655870 HVESP4LwstCllVltgMdlNmr 11465;
BA_ "SPN" SG_ 2364655870 HVESP4LwstCllVltgCllNmr 11466;
BA_ "SPN" SG_ 2364655870 HVESP4AverageCellVoltage 11467;
BA_ "SPN" SG_ 2364656126 HVESP4HghstCllTmprtrMdlNmr 11468;
BA_ "SPN" SG_ 2364656126 HVESP4HghstCllTmprtrCllNmr 11469;
BA_ "SPN" SG_ 2364656126 HVESP4LwstCllTmprtrMdlNmr 11470;
BA_ "SPN" SG_ 2364656126 HVESP4LwstCllTmprtrCllNmr 11471;
BA_ "SPN" SG_ 2364656382 HVESP4HghstCllSttfChrgMdlNmr 11472;
BA_ "SPN" SG_ 2364656382 HVESP4HghstCllSttfChrgCllNmr 11473;
BA_ "SPN" SG_ 2364656382 HVESP4LwstCllSttfChrgMdlNmr 11474;
BA_ "SPN" SG_ 2364656382 HVESP4LwstCllSttfChrgCllNmr 11475;
BA_ "SPN" SG_ 2364656382 HVESP4HghVltgBsAtvIsltnTstRslts 11476;
BA_ "SPN" SG_ 2364656382 HVESP4HVtBsPssvIstTstRsts 11477;
BA_ "SPN" SG_ 2364656638 HVESP4BsVltgNgtvtChsssGrndVltg 11478;
BA_ "SPN" SG_ 2364656638 HVESP4VltgLvlNgtvtChsssGrndVltg 11479;
BA_ "SPN" SG_ 2364656894 HVESP5DshrgPwrLmtDtSttfChrg 11502;
BA_ "SPN" SG_ 2364656894 HVESP5DshrgPwrLmtDtBttrTmprtr 11503;
BA_ "SPN" SG_ 2364656894 HVESP5DsPwLtDtBttDstCdt 11504;
BA_ "SPN" SG_ 2364656894 HVESP5DshrgPwrLmtDtBttrrCllVltg 11505;
BA_ "SPN" SG_ 2364656894 HVESP5DshrgPwrLmtDtBttrCrrnt 11506;
BA_ "SPN" SG_ 2364656894 HVESP5DshrgPwrLmtDtnUndfndCs 11507;
BA_ "SPN" SG_ 2364656894 HVESP5ChrgPwrLmtDtSttfChrg 11508;
BA_ "SPN" SG_ 2364656894 HVESP5ChrgPwrLmtDtBttrTmprtr 11509;
BA_ "SPN" SG_ 2364656894 HVESP5CPwLtDtBttDstCdt 11510;
BA_ "SPN" SG_ 2364656894 HVESP5ChrgPwrLmtDtBttrrCllVltg 11511;
BA_ "SPN" SG_ 2364656894 HVESP5ChrgPwrLmtDtBttrCrrnt 11512;
BA_ "SPN" SG_ 2364656894 HVESP5ChrgPwrLmtDtnUndfndCs 11513;
BA_ "SPN" SG_ 2364657150 HVESP5AvailableDischargePower 11514;
BA_ "SPN" SG_ 2364657150 HVESP5AvailableChargePower 11515;
BA_ "SPN" SG_ 2364657150 HVESP5VoltageLevel 11516;
BA_ "SPN" SG_ 2364657150 HVESP5Current 11517;
BA_ "SPN" SG_ 2364657406 HVESP5FastUpdateStateofCharge 11518;
BA_ "SPN" SG_ 2364657406 HVESP5HighestCellVoltage 11519;
BA_ "SPN" SG_ 2364657406 HVESP5LowestCellVoltage 11520;
BA_ "SPN" SG_ 2364657406 HVESP5CllVltgDffrntlStts 11521;
BA_ "SPN" SG_ 2364657662 HVESP5HighestCellTemperature 11522;
BA_ "SPN" SG_ 2364657662 HVESP5LowestCellTemperature 11523;
BA_ "SPN" SG_ 2364657662 HVESP5AverageCellTemperature 11524;
BA_ "SPN" SG_ 2364657662 HVESP5CllTmprtrDffrntlStts 11525;
BA_ "SPN" SG_ 2364657918 HVESP5DischargeCapacity 11526;
BA_ "SPN" SG_ 2364657918 HVESP5ChargeCapacity 11527;
BA_ "SPN" SG_ 2364657918 HVESP5CellBalancingCount 11528;
BA_ "SPN" SG_ 2364658174 HVESP5DischargeCurrentLimit 11529;
BA_ "SPN" SG_ 2364658174 HVESP5ChargeCurrentLimit 11530;
BA_ "SPN" SG_ 2364658174 HVESP5LowestCellStateofCharge 11531;
BA_ "SPN" SG_ 2364658174 HVESP5HighestCellStateofCharge 11532;
BA_ "SPN" SG_ 2364658430 HVESP5BusVoltage 11533;
BA_ "SPN" SG_ 2364658430 HVESP5IgnitionVoltage 11534;
BA_ "SPN" SG_ 2364658430 HVESP5IntakeCoolantTemperature 11535;
BA_ "SPN" SG_ 2364658430 HVESP5OutletCoolantTemperature 11536;
BA_ "SPN" SG_ 2364658430 HVESP5ElectronicsTemperature 11537;
BA_ "SPN" SG_ 2364658430 HVESP5Temperature 11538;
BA_ "SPN" SG_ 2364658686 HVESP5HghVltgBsPstvCnttrStt 11539;
BA_ "SPN" SG_ 2364658686 HVESP5HghVltgBsNgtvCnttrStt 11540;
BA_ "SPN" SG_ 2364658686 HVESP5HghVltgBsDsnntFrwrnng 11541;
BA_ "SPN" SG_ 2364658686 HVESP5HghVltgBsPrChrgRlStt 11542;
BA_ "SPN" SG_ 2364658686 HVESP5CntrfPkCnttrStt 11543;
BA_ "SPN" SG_ 2364658686 HVESP5HghVltgBsAtvIsltnTstStts 11544;
BA_ "SPN" SG_ 2364658686 HVESP5HghVltgBsPssvIsltnTstStts 11545;
BA_ "SPN" SG_ 2364658686 HVESP5HVILStatus 11546;
BA_ "SPN" SG_ 2364658686 HVESP5InertiaSwitchStatus 11547;
BA_ "SPN" SG_ 2364658686 HVESP5StateofChargeStatus 11548;
BA_ "SPN" SG_ 2364658686 HVESP5CellBalanceStatus 11549;
BA_ "SPN" SG_ 2364658686 HVESP5CellBalancingActive 11550;
BA_ "SPN" SG_ 2364658686 HVESP5InternalChargerStatus 11551;
BA_ "SPN" SG_ 2364658686 HVESP5HghVltgBsCnntnStts 11552;
BA_ "SPN" SG_ 2364658686 HVESP5OperationalStatus 11553;
BA_ "SPN" SG_ 2364658942 HVESP5DischargeEnergyCapacity 11554;
BA_ "SPN" SG_ 2364658942 HVESP5ChargeEnergyCapacity 11555;
BA_ "SPN" SG_ 2364658942 HVESP5MaximumChargeVoltageLimit 11556;
BA_ "SPN" SG_ 2364659198 HVESP5Module1OperationalStatus 11557;
BA_ "SPN" SG_ 2364659198 HVESP5Module2OperationalStatus 11558;
BA_ "SPN" SG_ 2364659198 HVESP5Module3OperationalStatus 11559;
BA_ "SPN" SG_ 2364659198 HVESP5Module4OperationalStatus 11560;
BA_ "SPN" SG_ 2364659198 HVESP5Module5OperationalStatus 11561;
BA_ "SPN" SG_ 2364659198 HVESP5Module6OperationalStatus 11562;
BA_ "SPN" SG_ 2364659198 HVESP5Module7OperationalStatus 11563;
BA_ "SPN" SG_ 2364659198 HVESP5Module8OperationalStatus 11564;
BA_ "SPN" SG_ 2364659198 HVESP5Module9OperationalStatus 11565;
BA_ "SPN" SG_ 2364659198 HVESP5Module10OperationalStatus 11566;
BA_ "SPN" SG_ 2364659198 HVESP5Module11OperationalStatus 11567;
BA_ "SPN" SG_ 2364659198 HVESP5Module12OperationalStatus 11568;
BA_ "SPN" SG_ 2364659198 HVESP5Module13OperationalStatus 11569;
BA_ "SPN" SG_ 2364659198 HVESP5Module14OperationalStatus 11570;
BA_ "SPN" SG_ 2364659198 HVESP5Module15OperationalStatus 11571;
BA_ "SPN" SG_ 2364659198 HVESP5Module16OperationalStatus 11572;
BA_ "SPN" SG_ 2364659454 HVESP5ThrmlMngmntSstmSLIInptPwr 11573;
BA_ "SPN" SG_ 2364659454 HVESP5TMtSstHVtIptPw 11574;
BA_ "SPN" SG_ 2364659454 HVESP5ThrmlMngmntSstmCmprssrSpd 11575;
BA_ "SPN" SG_ 2364659454 HVESP5ThrmlMngmntSstmRltvHmdt 11576;
BA_ "SPN" SG_ 2364659454 HVESP5ThrmlMngmntSstmHtrStts 11577;
BA_ "SPN" SG_ 2364659454 HVESP5ThrmlMngmntSstmHVILStts 12815;
BA_ "SPN" SG_ 2364659454 HVESP5ThrmlMngmntSstmMd 11578;
BA_ "SPN" SG_ 2364659454 HVESP5ThrmlMngmntSstmClntLvl 12902;
BA_ "SPN" SG_ 2364659710 HVESP5HghstCllVltgMdlNmr 11579;
BA_ "SPN" SG_ 2364659710 HVESP5HghstCllVltgCllNmr 11580;
BA_ "SPN" SG_ 2364659710 HVESP5LwstCllVltgMdlNmr 11581;
BA_ "SPN" SG_ 2364659710 HVESP5LwstCllVltgCllNmr 11582;
BA_ "SPN" SG_ 2364659710 HVESP5AverageCellVoltage 11583;
BA_ "SPN" SG_ 2364659966 HVESP5HghstCllTmprtrMdlNmr 11584;
BA_ "SPN" SG_ 2364659966 HVESP5HghstCllTmprtrCllNmr 11585;
BA_ "SPN" SG_ 2364659966 HVESP5LwstCllTmprtrMdlNmr 11586;
BA_ "SPN" SG_ 2364659966 HVESP5LwstCllTmprtrCllNmr 11587;
BA_ "SPN" SG_ 2364660222 HVESP5HghstCllSttfChrgMdlNmr 11588;
BA_ "SPN" SG_ 2364660222 HVESP5HghstCllSttfChrgCllNmr 11589;
BA_ "SPN" SG_ 2364660222 HVESP5LwstCllSttfChrgMdlNmr 11590;
BA_ "SPN" SG_ 2364660222 HVESP5LwstCllSttfChrgCllNmr 11591;
BA_ "SPN" SG_ 2364660222 HVESP5HghVltgBsAtvIsltnTstRslts 11592;
BA_ "SPN" SG_ 2364660222 HVESP5HVtBsPssvIstTstRsts 11593;
BA_ "SPN" SG_ 2364660478 HVESP5BsVltgNgtvtChsssGrndVltg 11594;
BA_ "SPN" SG_ 2364660478 HVESP5VltgLvlNgtvtChsssGrndVltg 11595;
